VERSION ""

NS_ :

BS_:

BU_:

BO_ 1484 PDU_2125: 8 Vector__XXX
 SG_ LnchCtlWhlSlSts : 1|5@0+ (1,0) [0|21] "" Vector__XXX
 SG_ LnchCtlEngRE46ts : 7|6@0+ (1,0) [0|38] "" TCM
 SG_ LnchCtlBrkPresVal : 8|4@0+ (10,0) [0|150] "%" Vector__XXX
 SG_ DrvModeVisScreenSts : 12|4@0+ (1,0) [0|12] "" Vector__XXX
 SG_ EngSndPerfModeReq : 16|3@0+ (1,0) [0|7] "" Vector__XXX
 SG_ LnchCtlLineLckTmrVal : 20|4@0+ (1,0) [0|15] "sec" TCM
 SG_ PerfTracMgmtMode : 26|3@0+ (1,0) [0|6] "" PCM,TCM
 SG_ HillDscntCtlSysSts : 29|3@0+ (1,0) [0|4] "" Vector__XXX
 SG_ SprtModeDrvlineVisDispVal : 33|3@0+ (1,0) [0|7] "" Vector__XXX
 SG_ SprtModeBrkPedVisDispVal : 36|3@0+ (1,0) [0|7] "" Vector__XXX
 SG_ SprtModeActvAeroVisDispVal : 39|3@0+ (1,0) [0|7] "" Vector__XXX
 SG_ SprtModeRideHghtVisDispVal : 40|3@0+ (1,0) [0|7] "" Vector__XXX
 SG_ SprtModePwrtrnVisDispVal : 43|3@0+ (1,0) [0|7] "" Vector__XXX
 SG_ SprtModeESCVisDispVal : 46|3@0+ (1,0) [0|7] "" Vector__XXX
 SG_ SprtModeSpnsnVisDispVal : 50|3@0+ (1,0) [0|7] "" Vector__XXX
 SG_ SprtModeSndVisDispVal : 53|3@0+ (1,0) [0|7] "" Vector__XXX
 SG_ ShfToPrkBfrExtIndOn : 56|1@0+ (1,0) [0|1] "" Vector__XXX
 SG_ HillDscntCtlVirtSwAvl : 57|1@0+ (1,0) [0|1] "" Vector__XXX
 SG_ WthrSnwModeStrgVisDispVal : 60|3@0+ (1,0) [0|7] "" Vector__XXX
 SG_ SprtModeStrgVisDispVal : 63|3@0+ (1,0) [0|7] "" Vector__XXX

BO_ 1485 PDU_2126: 8 Vector__XXX
 SG_ TkModeBrkPedVisDispVal : 1|3@0+ (1,0) [0|7] "" CGM
 SG_ TkModeActvAeroVisDispVal : 4|3@0+ (1,0) [0|7] "" CGM
 SG_ TireTrdTempSts : 7|3@0+ (1,0) [0|5] "" CGM,PCM,TCM
 SG_ TkModePwrtrnVisDispVal : 8|3@0+ (1,0) [0|7] "" CGM
 SG_ TkModeESCVisDispVal : 11|3@0+ (1,0) [0|7] "" CGM
 SG_ TkModeDrvlineVisDispVal : 14|3@0+ (1,0) [0|7] "" CGM
 SG_ TkModeSndVisDispVal : 18|3@0+ (1,0) [0|7] "" CGM
 SG_ TkModeRideHghtVisDispVal : 21|3@0+ (1,0) [0|7] "" CGM
 SG_ TourModeActvAeroVisDispVal : 25|3@0+ (1,0) [0|7] "" CGM
 SG_ TkModeStrgVisDispVal : 28|3@0+ (1,0) [0|7] "" CGM
 SG_ TkModeSpnsnVisDispVal : 31|3@0+ (1,0) [0|7] "" CGM
 SG_ TourModeESCVisDispVal : 32|3@0+ (1,0) [0|7] "" CGM
 SG_ TourModeDrvlineVisDispVal : 35|3@0+ (1,0) [0|7] "" CGM
 SG_ TourModeBrkPedVisDispVal : 38|3@0+ (1,0) [0|7] "" CGM
 SG_ TourModeRideHghtVisDispVal : 42|3@0+ (1,0) [0|7] "" CGM
 SG_ TourModePwrtrnVisDispVal : 45|3@0+ (1,0) [0|7] "" CGM
 SG_ TourModeStrgVisDispVal : 49|3@0+ (1,0) [0|7] "" CGM
 SG_ TourModeSpnsnVisDispVal : 52|3@0+ (1,0) [0|7] "" CGM
 SG_ TourModeSndVisDispVal : 55|3@0+ (1,0) [0|7] "" CGM
 SG_ TrlrStbAsstActIO : 56|1@0+ (1,0) [0|1] "" CGM
 SG_ TrcCntrlOnIO : 57|1@0+ (1,0) [0|1] "" CGM
 SG_ TrcCntrlOffIO : 58|1@0+ (1,0) [0|1] "" CGM
 SG_ TnDrvTrCtrlOffUnvIndOn : 59|1@0+ (1,0) [0|1] "" CGM
 SG_ SrBkLwBkFlDrVisMsgRqOn : 60|1@0+ (1,0) [0|1] "" CGM
 SG_ TrcStbScrConfig : 62|2@0+ (1,0) [0|3] "" CGM

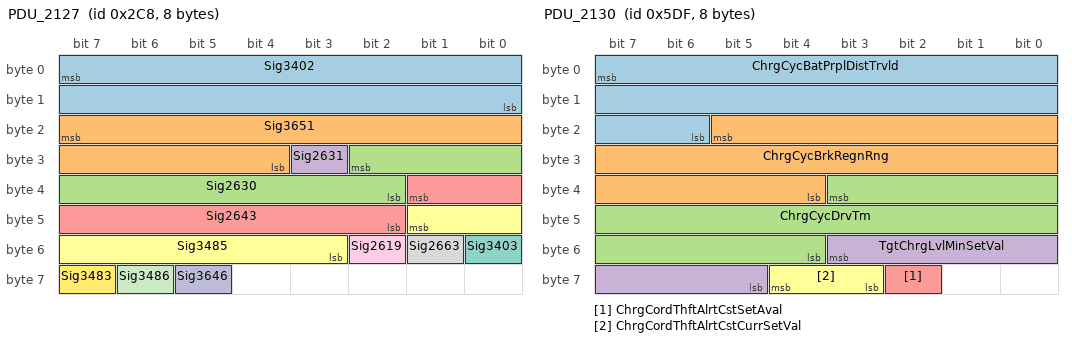
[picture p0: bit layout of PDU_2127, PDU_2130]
BO_ 712 PDU_2127: 8 Vector__XXX
 SG_ Sig3402 : 7|16@0+ (3.05176e-05,0) [0|1.99997] "liters" CGM
 SG_ Sig3651 : 23|12@0+ (0.025,0) [0|102.375] "ltrs/hr" CGM
 SG_ Sig2630 : 26|9@0+ (1,-110) [-110|401] "kPa" CGM
 SG_ Sig2631 : 27|1@0+ (1,0) [0|1] "" CGM
 SG_ Sig2643 : 33|8@0+ (0.392157,0) [0|100] "%" CGM
 SG_ Sig3485 : 41|7@0+ (1,0) [0|127] "%" CGM
 SG_ Sig3403 : 48|1@0+ (1,0) [0|1] "" CGM
 SG_ Sig2663 : 49|1@0+ (1,0) [0|1] "" CGM
 SG_ Sig2619 : 50|1@0+ (1,0) [0|1] "" CGM
 SG_ Sig3646 : 61|1@0+ (1,0) [0|1] "" CGM
 SG_ Sig3486 : 62|1@0+ (1,0) [0|1] "" CGM
 SG_ Sig3483 : 63|1@0+ (1,0) [0|1] "" CGM

BO_ 731 PDU_2128: 4 Vector__XXX
 SG_ ACRfHiSdFldPrs : 6|8@0+ (14,0) [0|3570] "kPaG" BSM,CGM
 SG_ ACRfHiSdFldPrs_Inv : 7|1@0+ (1,0) [0|1] "" BSM,CGM

BO_ 1503 PDU_2130: 8 Vector__XXX
 SG_ ChrgCycBatPrplDistTrvld : 7|18@0+ (0.1,0) [0|26214.3] "km" Vector__XXX
 SG_ ChrgCycBrkRegnRng : 21|18@0+ (0.1,0) [0|26214.3] "km" Vector__XXX
 SG_ ChrgCycDrvTm : 35|16@0+ (1,0) [0|65535] "min" Vector__XXX
 SG_ TgtChrgLvlMinSetVal : 51|7@0+ (1,0) [0|127] "%" Vector__XXX
 SG_ ChrgCordThftAlrtCstSetAval : 58|1@0+ (1,0) [0|1] "" Vector__XXX
 SG_ ChrgCordThftAlrtCstCurrSetVal : 60|2@0+ (1,0) [0|2] "" Vector__XXX

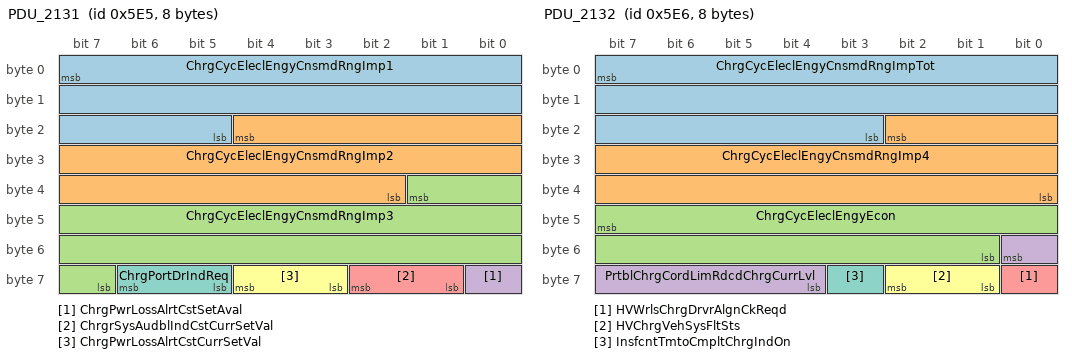
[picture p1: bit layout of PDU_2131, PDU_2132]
BO_ 1509 PDU_2131: 8 Vector__XXX
 SG_ ChrgCycEleclEngyCnsmdRngImp1 : 7|19@0- (0.1,0) [-26214.4|26214.3] "km" Vector__XXX
 SG_ ChrgCycEleclEngyCnsmdRngImp2 : 20|19@0- (0.1,0) [-26214.4|26214.3] "km" Vector__XXX
 SG_ ChrgCycEleclEngyCnsmdRngImp3 : 33|19@0- (0.1,0) [-26214.4|26214.3] "km" Vector__XXX
 SG_ ChrgPwrLossAlrtCstSetAval : 56|1@0+ (1,0) [0|1] "" Vector__XXX
 SG_ ChrgrSysAudblIndCstCurrSetVal : 58|2@0+ (1,0) [0|2] "" Vector__XXX
 SG_ ChrgPwrLossAlrtCstCurrSetVal : 60|2@0+ (1,0) [0|2] "" Vector__XXX
 SG_ ChrgPortDrIndReq : 62|2@0+ (1,0) [0|3] "" Vector__XXX

BO_ 1510 PDU_2132: 8 Vector__XXX
 SG_ ChrgCycEleclEngyCnsmdRngImpTot : 7|21@0- (0.1,0) [-104858|104858] "km" Vector__XXX
 SG_ ChrgCycEleclEngyCnsmdRngImp4 : 18|19@0- (0.1,0) [-26214.4|26214.3] "km" Vector__XXX
 SG_ ChrgCycEleclEngyEcon : 47|15@0- (0.1,0) [-1638.4|1638.3] "" Vector__XXX
 SG_ PrtblChrgCordLimRdcdChrgCurrLvl : 48|5@0+ (1,0) [0|31] "A" Vector__XXX
 SG_ HVWrlsChrgDrvrAlgnCkReqd : 56|1@0+ (1,0) [0|1] "" Vector__XXX
 SG_ HVChrgVehSysFltSts : 58|2@0+ (1,0) [0|2] "" Vector__XXX
 SG_ InsfcntTmtoCmpltChrgIndOn : 59|1@0+ (1,0) [0|1] "" Vector__XXX

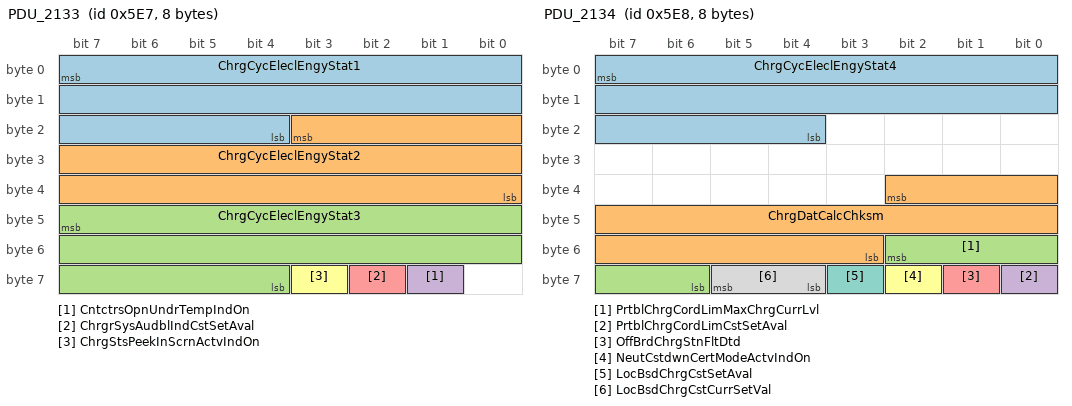
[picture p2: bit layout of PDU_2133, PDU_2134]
BO_ 1511 PDU_2133: 8 Vector__XXX
 SG_ ChrgCycEleclEngyStat1 : 7|20@0+ (0.01,0) [0|10485.8] "kWh" Vector__XXX
 SG_ ChrgCycEleclEngyStat2 : 19|20@0+ (0.01,0) [0|10485.8] "kWh" Vector__XXX
 SG_ ChrgCycEleclEngyStat3 : 47|20@0+ (0.01,0) [0|10485.8] "kWh" Vector__XXX
 SG_ CntctrsOpnUndrTempIndOn : 57|1@0+ (1,0) [0|1] "" Vector__XXX
 SG_ ChrgrSysAudblIndCstSetAval : 58|1@0+ (1,0) [0|1] "" Vector__XXX
 SG_ ChrgStsPeekInScrnActvIndOn : 59|1@0+ (1,0) [0|1] "" Vector__XXX

BO_ 1512 PDU_2134: 8 Vector__XXX
 SG_ ChrgCycEleclEngyStat4 : 7|20@0+ (0.01,0) [0|10485.8] "kWh" Vector__XXX
 SG_ ChrgDatCalcChksm : 34|16@0+ (1,0) [0|65535] "" Vector__XXX
 SG_ PrtblChrgCordLimMaxChrgCurrLvl : 50|5@0+ (1,0) [0|31] "A" Vector__XXX
 SG_ PrtblChrgCordLimCstSetAval : 56|1@0+ (1,0) [0|1] "" Vector__XXX
 SG_ OffBrdChrgStnFltDtd : 57|1@0+ (1,0) [0|1] "" Vector__XXX
 SG_ NeutCstdwnCertModeActvIndOn : 58|1@0+ (1,0) [0|1] "" Vector__XXX
 SG_ LocBsdChrgCstSetAval : 59|1@0+ (1,0) [0|1] "" Vector__XXX
 SG_ LocBsdChrgCstCurrSetVal : 61|2@0+ (1,0) [0|2] "" Vector__XXX

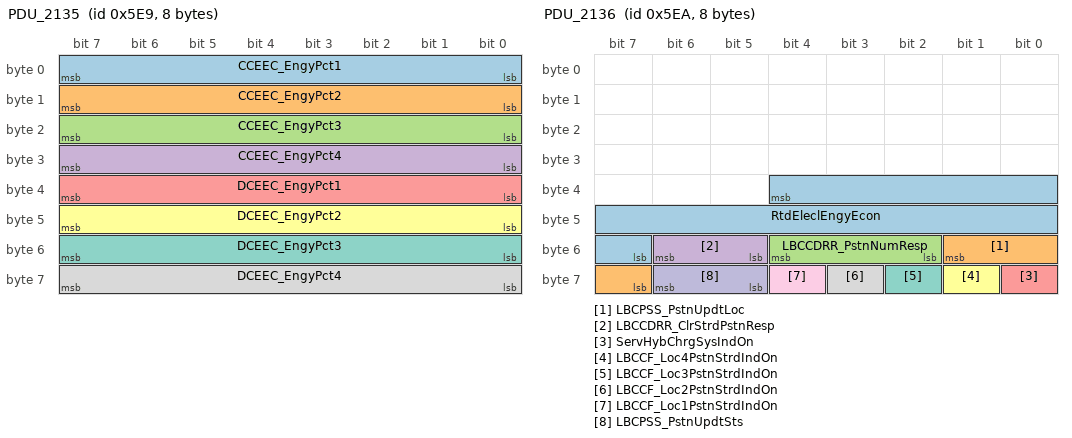
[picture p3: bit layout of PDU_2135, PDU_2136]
BO_ 1513 PDU_2135: 8 Vector__XXX
 SG_ CCEEC_EngyPct1 : 7|8@0+ (0.392157,0) [0|100] "%" Vector__XXX
 SG_ CCEEC_EngyPct2 : 15|8@0+ (0.392157,0) [0|100] "%" Vector__XXX
 SG_ CCEEC_EngyPct3 : 23|8@0+ (0.392157,0) [0|100] "%" Vector__XXX
 SG_ CCEEC_EngyPct4 : 31|8@0+ (0.392157,0) [0|100] "%" Vector__XXX
 SG_ DCEEC_EngyPct1 : 39|8@0+ (0.392157,0) [0|100] "%" Vector__XXX
 SG_ DCEEC_EngyPct2 : 47|8@0+ (0.392157,0) [0|100] "%" Vector__XXX
 SG_ DCEEC_EngyPct3 : 55|8@0+ (0.392157,0) [0|100] "%" Vector__XXX
 SG_ DCEEC_EngyPct4 : 63|8@0+ (0.392157,0) [0|100] "%" Vector__XXX

BO_ 1514 PDU_2136: 8 Vector__XXX
 SG_ RtdEleclEngyEcon : 36|14@0+ (0.1,0) [0|1638.3] "" Vector__XXX
 SG_ LBCPSS_PstnUpdtLoc : 49|3@0+ (1,0) [0|4] "" Vector__XXX
 SG_ LBCCDRR_PstnNumResp : 52|3@0+ (1,0) [0|4] "" Vector__XXX
 SG_ LBCCDRR_ClrStrdPstnResp : 54|2@0+ (1,0) [0|2] "" Vector__XXX
 SG_ ServHybChrgSysIndOn : 56|1@0+ (1,0) [0|1] "" VDM
 SG_ LBCCF_Loc4PstnStrdIndOn : 57|1@0+ (1,0) [0|1] "" Vector__XXX
 SG_ LBCCF_Loc3PstnStrdIndOn : 58|1@0+ (1,0) [0|1] "" Vector__XXX
 SG_ LBCCF_Loc2PstnStrdIndOn : 59|1@0+ (1,0) [0|1] "" Vector__XXX
 SG_ LBCCF_Loc1PstnStrdIndOn : 60|1@0+ (1,0) [0|1] "" Vector__XXX
 SG_ LBCPSS_PstnUpdtSts : 62|2@0+ (1,0) [0|2] "" Vector__XXX

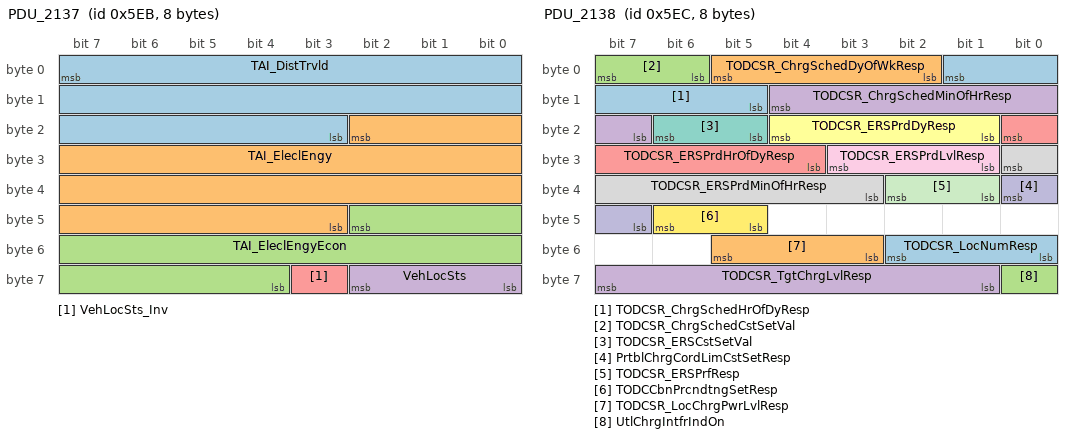
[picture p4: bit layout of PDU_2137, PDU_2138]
BO_ 1515 PDU_2137: 8 Vector__XXX
 SG_ TAI_DistTrvld : 7|21@0+ (0.1,0) [0|209715] "km" Vector__XXX
 SG_ TAI_EleclEngy : 18|24@0+ (0.1,0) [0|1.67772e+006] "kWh" Vector__XXX
 SG_ TAI_EleclEngyEcon : 42|15@0- (0.1,0) [-1638.4|1638.3] "" Vector__XXX
 SG_ VehLocSts : 58|3@0+ (1,0) [0|4] "" Vector__XXX
 SG_ VehLocSts_Inv : 59|1@0+ (1,0) [0|1] "" Vector__XXX

BO_ 1516 PDU_2138: 8 Vector__XXX
 SG_ TODCSR_ChrgSchedHrOfDyResp : 1|5@0+ (1,0) [0|31] "h" Vector__XXX
 SG_ TODCSR_ChrgSchedDyOfWkResp : 5|4@0+ (1,0) [0|10] "" Vector__XXX
 SG_ TODCSR_ChrgSchedCstSetVal : 7|2@0+ (1,0) [0|2] "" Vector__XXX
 SG_ TODCSR_ChrgSchedMinOfHrResp : 12|6@0+ (1,0) [0|63] "min" Vector__XXX
 SG_ TODCSR_ERSPrdHrOfDyResp : 16|5@0+ (1,0) [0|31] "h" Vector__XXX
 SG_ TODCSR_ERSPrdDyResp : 20|4@0+ (1,0) [0|10] "" Vector__XXX
 SG_ TODCSR_ERSCstSetVal : 22|2@0+ (1,0) [0|2] "" Vector__XXX
 SG_ TODCSR_ERSPrdMinOfHrResp : 24|6@0+ (1,0) [0|63] "min" Vector__XXX
 SG_ TODCSR_ERSPrdLvlResp : 27|3@0+ (1,0) [0|5] "" Vector__XXX
 SG_ PrtblChrgCordLimCstSetResp : 32|2@0+ (1,0) [0|2] "" Vector__XXX
 SG_ TODCSR_ERSPrfResp : 34|2@0+ (1,0) [0|3] "" Vector__XXX
 SG_ TODCCbnPrcndtngSetResp : 46|2@0+ (1,0) [0|2] "" Vector__XXX
 SG_ TODCSR_LocNumResp : 50|3@0+ (1,0) [0|5] "" Vector__XXX
 SG_ TODCSR_LocChrgPwrLvlResp : 53|3@0+ (1,0) [0|4] "" Vector__XXX
 SG_ UtlChrgIntfrIndOn : 56|1@0+ (1,0) [0|1] "" Vector__XXX
 SG_ TODCSR_TgtChrgLvlResp : 63|7@0+ (1,0) [0|127] "%" Vector__XXX

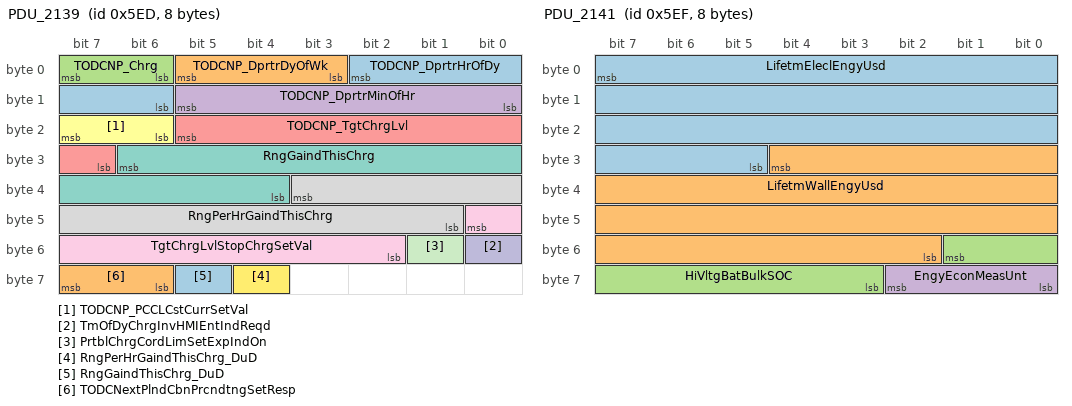
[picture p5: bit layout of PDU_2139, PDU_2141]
BO_ 1517 PDU_2139: 8 Vector__XXX
 SG_ TODCNP_DprtrHrOfDy : 2|5@0+ (1,0) [0|31] "h" Vector__XXX
 SG_ TODCNP_DprtrDyOfWk : 5|3@0+ (1,0) [0|7] "" Vector__XXX
 SG_ TODCNP_Chrg : 7|2@0+ (1,0) [0|3] "" Vector__XXX
 SG_ TODCNP_DprtrMinOfHr : 13|6@0+ (1,0) [0|63] "min" Vector__XXX
 SG_ TODCNP_TgtChrgLvl : 21|7@0+ (1,0) [0|127] "%" Vector__XXX
 SG_ TODCNP_PCCLCstCurrSetVal : 23|2@0+ (1,0) [0|2] "" Vector__XXX
 SG_ RngGaindThisChrg : 30|11@0+ (1,0) [0|2047] "km" Vector__XXX
 SG_ RngPerHrGaindThisChrg : 35|11@0+ (1,0) [0|2047] "km/h" Vector__XXX
 SG_ TgtChrgLvlStopChrgSetVal : 40|7@0+ (1,0) [0|127] "%" Vector__XXX
 SG_ TmOfDyChrgInvHMIEntIndReqd : 48|1@0+ (1,0) [0|1] "" Vector__XXX
 SG_ PrtblChrgCordLimSetExpIndOn : 49|1@0+ (1,0) [0|1] "" Vector__XXX
 SG_ RngPerHrGaindThisChrg_DuD : 60|1@0+ (1,0) [0|1] "" Vector__XXX
 SG_ RngGaindThisChrg_DuD : 61|1@0+ (1,0) [0|1] "" Vector__XXX
 SG_ TODCNextPlndCbnPrcndtngSetResp : 63|2@0+ (1,0) [0|2] "" Vector__XXX

BO_ 1518 PDU_2140: 8 Vector__XXX
 SG_ LifetmBatPrplDistTrvld : 7|24@0+ (0.1,0) [0|1.67772e+006] "km" Vector__XXX
 SG_ DrvCycBrkRegnRng : 32|14@0+ (0.1,0) [0|1638.3] "km" Vector__XXX
 SG_ DrvCycDrvTm : 50|11@0+ (1,0) [0|2047] "min" Vector__XXX

BO_ 1519 PDU_2141: 8 Vector__XXX
 SG_ LifetmEleclEngyUsd : 7|27@0+ (0.1,0) [0|1.34218e+007] "kWh" Vector__XXX
 SG_ LifetmWallEngyUsd : 28|27@0+ (0.1,0) [0|1.34218e+007] "kWh" Vector__XXX
 SG_ HiVltgBatBulkSOC : 49|7@0+ (1,0) [0|127] "%" Vector__XXX
 SG_ EngyEconMeasUnt : 58|3@0+ (1,0) [0|5] "" Vector__XXX

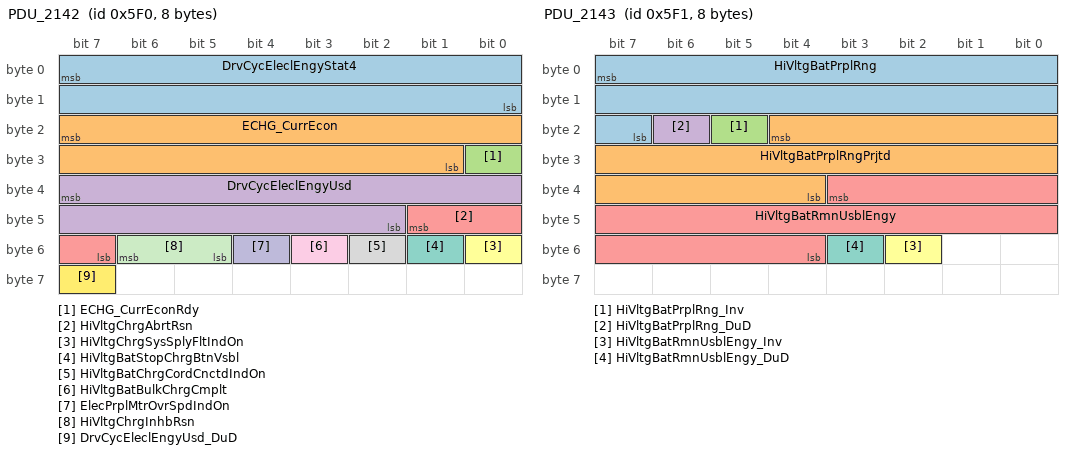
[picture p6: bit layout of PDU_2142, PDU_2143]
BO_ 1520 PDU_2142: 8 Vector__XXX
 SG_ DrvCycEleclEngyStat4 : 7|16@0+ (0.01,0) [0|655.35] "kWh" Vector__XXX
 SG_ ECHG_CurrEcon : 23|15@0- (0.1,0) [-1638.4|1638.3] "" Vector__XXX
 SG_ ECHG_CurrEconRdy : 24|1@0+ (1,0) [0|1] "" Vector__XXX
 SG_ DrvCycEleclEngyUsd : 39|14@0+ (0.1,0) [0|1638.3] "kWh" Vector__XXX
 SG_ HiVltgChrgAbrtRsn : 41|3@0+ (1,0) [0|6] "" Vector__XXX
 SG_ HiVltgChrgSysSplyFltIndOn : 48|1@0+ (1,0) [0|1] "" Vector__XXX
 SG_ HiVltgBatStopChrgBtnVsbl : 49|1@0+ (1,0) [0|1] "" Vector__XXX
 SG_ HiVltgBatChrgCordCnctdIndOn : 50|1@0+ (1,0) [0|1] "" VDM
 SG_ HiVltgBatBulkChrgCmplt : 51|1@0+ (1,0) [0|1] "" Vector__XXX
 SG_ ElecPrplMtrOvrSpdIndOn : 52|1@0+ (1,0) [0|1] "" Vector__XXX
 SG_ HiVltgChrgInhbRsn : 54|2@0+ (1,0) [0|3] "" Vector__XXX
 SG_ DrvCycEleclEngyUsd_DuD : 63|1@0+ (1,0) [0|1] "" Vector__XXX

BO_ 1521 PDU_2143: 8 Vector__XXX
 SG_ HiVltgBatPrplRng : 7|17@0+ (0.015625,0) [0|2047.98] "km" ADIMa,ADIMb,VDM
 SG_ HiVltgBatPrplRngPrjtd : 20|17@0+ (0.015625,0) [0|2047.98] "km" Vector__XXX
 SG_ HiVltgBatPrplRng_Inv : 21|1@0+ (1,0) [0|1] "" ADIMa,ADIMb,VDM
 SG_ HiVltgBatPrplRng_DuD : 22|1@0+ (1,0) [0|1] "" ADIMa,ADIMb,VDM
 SG_ HiVltgBatRmnUsblEngy : 35|16@0+ (0.01,0) [0|655.35] "kWh" VDM
 SG_ HiVltgBatRmnUsblEngy_Inv : 50|1@0+ (1,0) [0|1] "" VDM
 SG_ HiVltgBatRmnUsblEngy_DuD : 51|1@0+ (1,0) [0|1] "" VDM

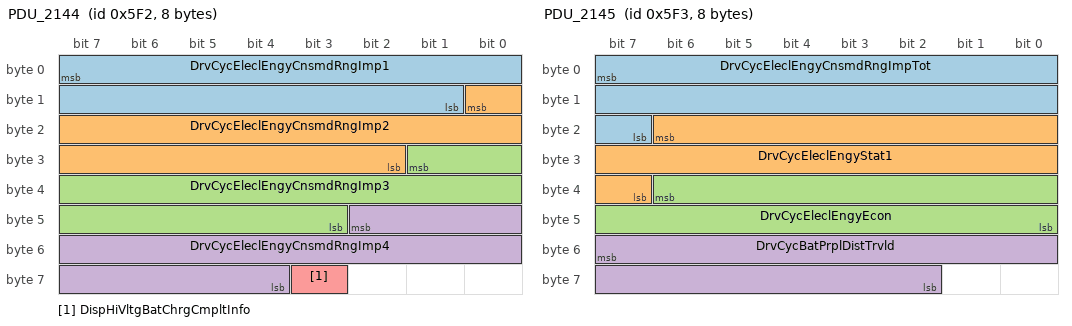
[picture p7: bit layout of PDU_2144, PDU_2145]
BO_ 1522 PDU_2144: 8 Vector__XXX
 SG_ DrvCycEleclEngyCnsmdRngImp1 : 7|15@0- (0.1,0) [-1638.4|1638.3] "km" Vector__XXX
 SG_ DrvCycEleclEngyCnsmdRngImp2 : 8|15@0- (0.1,0) [-1638.4|1638.3] "km" Vector__XXX
 SG_ DrvCycEleclEngyCnsmdRngImp3 : 25|15@0- (0.1,0) [-1638.4|1638.3] "km" Vector__XXX
 SG_ DrvCycEleclEngyCnsmdRngImp4 : 42|15@0- (0.1,0) [-1638.4|1638.3] "km" Vector__XXX
 SG_ DispHiVltgBatChrgCmpltInfo : 59|1@0+ (1,0) [0|1] "" Vector__XXX

BO_ 1523 PDU_2145: 8 Vector__XXX
 SG_ DrvCycEleclEngyCnsmdRngImpTot : 7|17@0- (0.1,0) [-6553.6|6553.5] "km" Vector__XXX
 SG_ DrvCycEleclEngyStat1 : 22|16@0+ (0.01,0) [0|655.35] "kWh" Vector__XXX
 SG_ DrvCycEleclEngyEcon : 38|15@0- (0.1,0) [-1638.4|1638.3] "" Vector__XXX
 SG_ DrvCycBatPrplDistTrvld : 55|14@0+ (0.1,0) [0|1638.3] "km" Vector__XXX

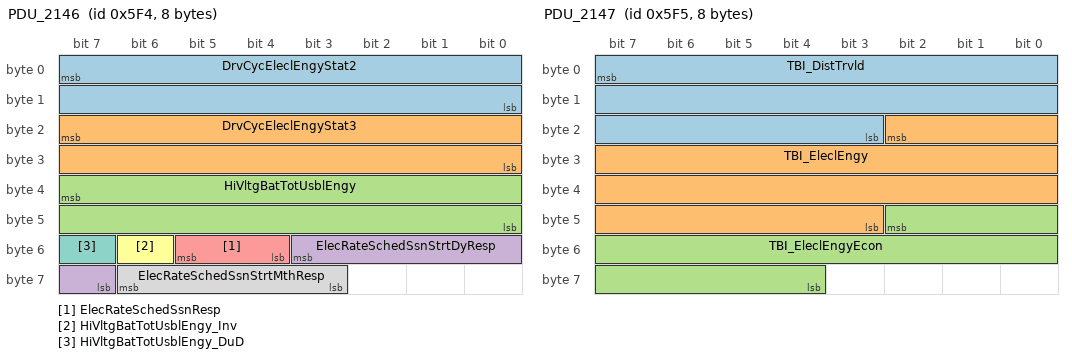
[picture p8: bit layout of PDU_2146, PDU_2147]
BO_ 1524 PDU_2146: 8 Vector__XXX
 SG_ DrvCycEleclEngyStat2 : 7|16@0+ (0.01,0) [0|655.35] "kWh" Vector__XXX
 SG_ DrvCycEleclEngyStat3 : 23|16@0+ (0.01,0) [0|655.35] "kWh" Vector__XXX
 SG_ HiVltgBatTotUsblEngy : 39|16@0+ (0.01,0) [0|655.35] "kWh" VDM
 SG_ ElecRateSchedSsnStrtDyResp : 51|5@0+ (1,0) [0|31] "day" Vector__XXX
 SG_ ElecRateSchedSsnResp : 53|2@0+ (1,0) [0|3] "" Vector__XXX
 SG_ HiVltgBatTotUsblEngy_Inv : 54|1@0+ (1,0) [0|1] "" VDM
 SG_ HiVltgBatTotUsblEngy_DuD : 55|1@0+ (1,0) [0|1] "" VDM
 SG_ ElecRateSchedSsnStrtMthResp : 62|4@0+ (1,0) [0|12] "" Vector__XXX

BO_ 1525 PDU_2147: 8 Vector__XXX
 SG_ TBI_DistTrvld : 7|21@0+ (0.1,0) [0|209715] "km" Vector__XXX
 SG_ TBI_EleclEngy : 18|24@0+ (0.1,0) [0|1.67772e+006] "kWh" Vector__XXX
 SG_ TBI_EleclEngyEcon : 42|15@0- (0.1,0) [-1638.4|1638.3] "" Vector__XXX

BO_ 736 PDU_2150: 8 Vector__XXX
 SG_ LIB1PackExtrnVltg : 7|11@0+ (0.01,3) [3|23.47] "Volts" FOPM
 SG_ LIB1AvgTemp : 10|8@0+ (1,-40) [-40|215] "C" ECM,FOPM,PCM
 SG_ LIB1PackExtrnVltg_Inv : 11|1@0+ (1,0) [0|1] "" FOPM
 SG_ LIB1PackExtrnVltg_DuD : 12|1@0+ (1,0) [0|1] "" Vector__XXX
 SG_ LIB1MaxTemp : 16|8@0+ (1,-40) [-40|215] "C" ADIMa,ADIMb,ECM,FOPM,PCM
 SG_ LIB1AvgTemp_Inv : 17|1@0+ (1,0) [0|1] "" ECM,FOPM,PCM
 SG_ LIB1AvgTemp_DuD : 18|1@0+ (1,0) [0|1] "" ECM,PCM
 SG_ LIB1MaxTemp_DuD : 24|1@0+ (1,0) [0|1] "" ECM,PCM
 SG_ LIB1MinTemp : 38|8@0+ (1,-40) [-40|215] "C" ADIMa,ADIMb,ECM,FOPM,PCM
 SG_ LIB1MaxTemp_Inv : 39|1@0+ (1,0) [0|1] "" ADIMa,ADIMb,ECM,FOPM,PCM
 SG_ LIB1StatOfChrg : 44|8@0+ (0.39,0) [0|99.45] "%" ECM,FOPM,PCM
 SG_ LIB1MinTemp_Inv : 45|1@0+ (1,0) [0|1] "" ADIMa,ADIMb,ECM,FOPM,PCM
 SG_ LIB1MinTemp_DuD : 46|1@0+ (1,0) [0|1] "" ECM,PCM
 SG_ LIB1CellBalFlt_DuD : 48|1@0+ (1,0) [0|1] "" Vector__XXX
 SG_ LIB1CellBalFlt : 50|2@0+ (1,0) [0|3] "" FOPM
 SG_ LIB1StatOfChrg_Inv : 51|1@0+ (1,0) [0|1] "" ECM,FOPM,PCM
 SG_ LIB1StatOfChrg_DuD : 52|1@0+ (1,0) [0|1] "" ECM,PCM
 SG_ LIB1CellVltgFlt_Inv : 59|1@0+ (1,0) [0|1] "" FOPM
 SG_ LIB1CellVltgFlt_DuD : 60|1@0+ (1,0) [0|1] "" Vector__XXX
 SG_ LIB1CellVltgFlt : 62|2@0+ (1,0) [0|3] "" FOPM
 SG_ LIB1CellBalFlt_Inv : 63|1@0+ (1,0) [0|1] "" FOPM

BO_ 949 PDU_2153: 8 Vector__XXX
 SG_ ACCTOSHiThrtLicVehTmToClsn1 : 7|16@0+ (0.001,0) [0|65.535] "s" Vector__XXX
 SG_ ACCTOSHiThrtLicVehTmToClsn10 : 23|16@0+ (0.001,0) [0|65.535] "s" Vector__XXX
 SG_ ACCTOSHiThrtLicVehTmToClsn2 : 39|16@0+ (0.001,0) [0|65.535] "s" Vector__XXX
 SG_ ACCTOSHiThrtLicVehTmToClsn3 : 55|16@0+ (0.001,0) [0|65.535] "s" Vector__XXX

BO_ 950 PDU_2154: 8 Vector__XXX
 SG_ ACCTOSHiThrtLicVehTmToClsn4 : 7|16@0+ (0.001,0) [0|65.535] "s" Vector__XXX
 SG_ ACCTOSHiThrtLicVehTmToClsn5 : 23|16@0+ (0.001,0) [0|65.535] "s" Vector__XXX
 SG_ ACCTOSHiThrtLicVehTmToClsn6 : 39|16@0+ (0.001,0) [0|65.535] "s" Vector__XXX
 SG_ ACCTOSHiThrtLicVehTmToClsn7 : 55|16@0+ (0.001,0) [0|65.535] "s" Vector__XXX

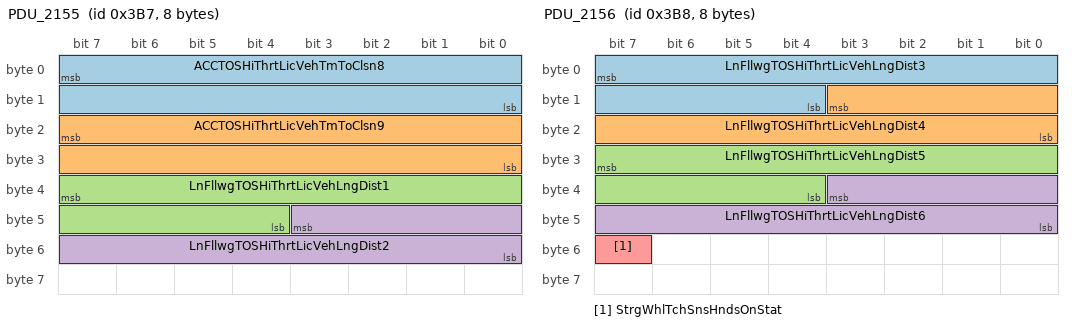
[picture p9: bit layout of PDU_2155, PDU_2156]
BO_ 951 PDU_2155: 8 Vector__XXX
 SG_ ACCTOSHiThrtLicVehTmToClsn8 : 7|16@0+ (0.001,0) [0|65.535] "s" Vector__XXX
 SG_ ACCTOSHiThrtLicVehTmToClsn9 : 23|16@0+ (0.001,0) [0|65.535] "s" Vector__XXX
 SG_ LnFllwgTOSHiThrtLicVehLngDist1 : 39|12@0- (0.125,0) [-256|255.875] "m" Vector__XXX
 SG_ LnFllwgTOSHiThrtLicVehLngDist2 : 43|12@0- (0.125,0) [-256|255.875] "m" Vector__XXX

BO_ 952 PDU_2156: 8 Vector__XXX
 SG_ LnFllwgTOSHiThrtLicVehLngDist3 : 7|12@0- (0.125,0) [-256|255.875] "m" Vector__XXX
 SG_ LnFllwgTOSHiThrtLicVehLngDist4 : 11|12@0- (0.125,0) [-256|255.875] "m" Vector__XXX
 SG_ LnFllwgTOSHiThrtLicVehLngDist5 : 31|12@0- (0.125,0) [-256|255.875] "m" Vector__XXX
 SG_ LnFllwgTOSHiThrtLicVehLngDist6 : 35|12@0- (0.125,0) [-256|255.875] "m" Vector__XXX
 SG_ StrgWhlTchSnsHndsOnStat : 55|1@0+ (1,0) [0|1] "" Vector__XXX

BO_ 1417 PDU_2157: 8 Vector__XXX
 SG_ ACCDrSlctdSpd : 5|12@0+ (0.0625,0) [0|255.938] "km/h" CGM
 SG_ ACCAutoStSpStat : 7|2@0+ (1,0) [0|3] "" CGM
 SG_ ACCSpdLimSgnUnt : 8|1@0+ (1,0) [0|1] "" CGM
 SG_ ACCDrSlctdSpdIndOn : 9|1@0+ (1,0) [0|1] "" CGM
 SG_ ACCSpdLimSgnVal : 23|8@0+ (1,0) [0|255] "" CGM
 SG_ FrwdImpMtgnOpSlctCstCrStVal : 26|3@0+ (1,0) [0|7] "" CGM
 SG_ FrntPCMRspTypCstCrStVal : 29|3@0+ (1,0) [0|7] "" CGM
 SG_ ACCSysSlctdMd : 31|2@0+ (1,0) [0|2] "" CGM
 SG_ FrntPCMRspTypCstAvlFlg1 : 32|1@0+ (1,0) [0|1] "" CGM
 SG_ AutoEmrgBrkgDsbldIndOn : 33|1@0+ (1,0) [0|1] "" CGM
 SG_ ACCGoNtfrChmEvntSt : 34|1@0+ (1,0) [0|1] "" CGM
 SG_ AnmlWrnIndReq : 36|2@0+ (1,0) [0|2] "" CGM
 SG_ FrwdVehAhdIndReq : 39|3@0+ (1,0) [0|5] "" CGM
 SG_ FrtPedtrnClsnMtgnAudAttnReqd : 40|1@0+ (1,0) [0|1] "" CGM
 SG_ FrntPCMRspTypCstStAvl : 41|1@0+ (1,0) [0|1] "" CGM
 SG_ FrntPCMRspTypCstAvlFlg7 : 42|1@0+ (1,0) [0|1] "" CGM
 SG_ FrntPCMRspTypCstAvlFlg6 : 43|1@0+ (1,0) [0|1] "" CGM
 SG_ FrntPCMRspTypCstAvlFlg5 : 44|1@0+ (1,0) [0|1] "" CGM
 SG_ FrntPCMRspTypCstAvlFlg4 : 45|1@0+ (1,0) [0|1] "" CGM
 SG_ FrntPCMRspTypCstAvlFlg3 : 46|1@0+ (1,0) [0|1] "" CGM
 SG_ FrntPCMRspTypCstAvlFlg2 : 47|1@0+ (1,0) [0|1] "" CGM
 SG_ FrwdImpMtgnOpSlctCstAvlFlg7 : 48|1@0+ (1,0) [0|1] "" CGM
 SG_ FrwdImpMtgnOpSlctCstAvlFlg6 : 49|1@0+ (1,0) [0|1] "" CGM
 SG_ FrwdImpMtgnOpSlctCstAvlFlg5 : 50|1@0+ (1,0) [0|1] "" CGM
 SG_ FrwdImpMtgnOpSlctCstAvlFlg4 : 51|1@0+ (1,0) [0|1] "" CGM
 SG_ FrwdImpMtgnOpSlctCstAvlFlg3 : 52|1@0+ (1,0) [0|1] "" CGM
 SG_ FrwdImpMtgnOpSlctCstAvlFlg2 : 53|1@0+ (1,0) [0|1] "" CGM
 SG_ FrwdImpMtgnOpSlctCstAvlFlg1 : 54|1@0+ (1,0) [0|1] "" CGM
 SG_ FrwdClsnAlrtImntAlrtAudAttnReqd : 55|1@0+ (1,0) [0|1] "" CGM
 SG_ GoNotfrCstAvlFlg7 : 56|1@0+ (1,0) [0|1] "" CGM
 SG_ GoNotfrCstAvlFlg6 : 57|1@0+ (1,0) [0|1] "" CGM
 SG_ GoNotfrCstAvlFlg5 : 58|1@0+ (1,0) [0|1] "" CGM
 SG_ GoNotfrCstAvlFlg4 : 59|1@0+ (1,0) [0|1] "" CGM
 SG_ GoNotfrCstAvlFlg3 : 60|1@0+ (1,0) [0|1] "" CGM
 SG_ GoNotfrCstAvlFlg2 : 61|1@0+ (1,0) [0|1] "" CGM
 SG_ GoNotfrCstAvlFlg1 : 62|1@0+ (1,0) [0|1] "" CGM
 SG_ FrwdImpMtgnOpSlctCstStAvl : 63|1@0+ (1,0) [0|1] "" CGM

BO_ 1259 PDU_2158: 6 Vector__XXX
 SG_ SprTireSt : 7|2@0+ (1,0) [0|2] "" CGM,EPS,EPSb,PCM,RDCM,TCCM,TCM

BO_ 40 PDU_2159: 16 Vector__XXX
 SG_ RAI1P_RrAxlEstdTrqAuth : 7|11@0+ (5,-5120) [-5120|5115] "Nm" ADIMa,ADIMb,ECP_E,ECP_S
 SG_ PrplSysPriAxlLtTrqCmdAuth : 9|19@0- (0.25,0) [-65536|65535.8] "Nm" EPS,EPSb
 SG_ RAI1P_RrAxlStsAuth : 11|2@0+ (1,0) [0|3] "" ADIMa,ADIMb,ECP_E,ECP_S
 SG_ RAI1P_RrAxlEstdTrqAuth_Inv : 12|1@0+ (1,0) [0|1] "" ADIMa,ADIMb,ECP_E,ECP_S
 SG_ PrplSysPriAxlRtTrqCmdAuth : 38|19@0- (0.25,0) [-65536|65535.8] "Nm" EPS,EPSb
 SG_ PrplSysSecAxlTrqCmdAuth : 51|19@0- (0.25,0) [-65536|65535.8] "Nm" EPS,EPSb

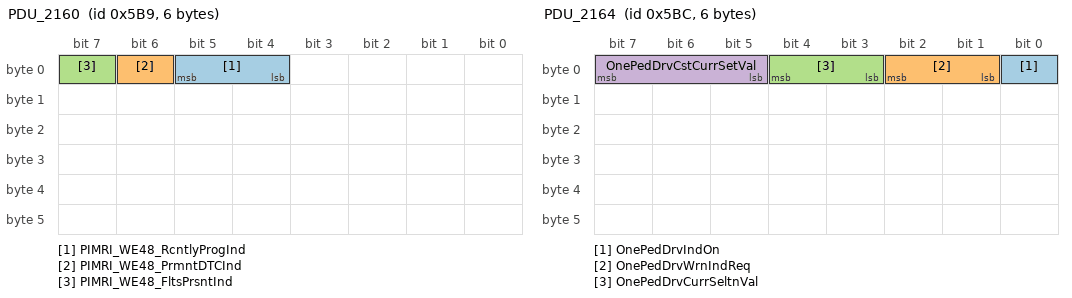
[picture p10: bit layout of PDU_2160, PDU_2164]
BO_ 1465 PDU_2160: 6 Vector__XXX
 SG_ PIMRI_WE48_RcntlyProgInd : 5|2@0+ (1,0) [0|3] "" ECM,PCM,ECP_E
 SG_ PIMRI_WE48_PrmntDTCInd : 6|1@0+ (1,0) [0|1] "" ECM,PCM,ECP_E
 SG_ PIMRI_WE48_FltsPrsntInd : 7|1@0+ (1,0) [0|1] "" ECM,PCM,ECP_E

BO_ 1466 PDU_2161: 8 Vector__XXX
 SG_ TirePrsLRInr : 7|8@0+ (4,0) [0|1020] "kPaG" EBCM
 SG_ TirePrsRRInr : 11|8@0+ (4,0) [0|1020] "kPaG" EBCM
 SG_ TirePrsStatLRInr : 14|3@0+ (1,0) [0|5] "" EBCM
 SG_ TirePrsLRInr_Inv : 15|1@0+ (1,0) [0|1] "" EBCM
 SG_ TirePrsStatRRInr : 18|3@0+ (1,0) [0|5] "" EBCM
 SG_ TirePrsRRInr_Inv : 19|1@0+ (1,0) [0|1] "" EBCM
 SG_ ElecRateSchedSsnStrtMthReq : 24|4@0+ (1,0) [0|12] "" VICM
 SG_ ElecRateSchedSsnStrtDyReq : 29|5@0+ (1,0) [0|31] "day" VICM
 SG_ ElecRateSchedSsnReq : 31|2@0+ (1,0) [0|3] "" VICM
 SG_ CbnPrcndtngSchTempCstSetReq : 36|5@0+ (0.5,16) [16|31.5] "Deg C" VICM
 SG_ VirtOnePedDrvReq : 40|2@0+ (1,0) [0|2] "" ECP_E
 SG_ TlmHVDCFstChrgSoonReq : 42|2@0+ (1,0) [0|2] "" VICM
 SG_ HVDCFstChrgSoonReq : 44|2@0+ (1,0) [0|2] "" VICM
 SG_ OnePedDrvCstChgSetReq : 47|3@0+ (1,0) [0|4] "" ECP_E
 SG_ Sig2580 : 49|2@0+ (1,0) [0|3] "" ADIMa,ADIMb
 SG_ Sig0613 : 51|2@0+ (1,0) [0|3] "" ADIMa,ADIMb
 SG_ E44MutDrvrReq : 53|2@0+ (1,0) [0|2] "" ACP2_MCU,EOCM,EOCM_HC_Superset
 SG_ CbnPrcndtngSchTempCstSetReqAtv : 54|1@0+ (1,0) [0|1] "" VICM
 SG_ DMSIntnDrvrCstChgSetReq : 58|3@0+ (1,0) [0|2] "" ACP2_MCU,EOCM_HC_Superset,FCM
 SG_ DMSDrwDrvrCstChgSetReq : 61|3@0+ (1,0) [0|3] "" ACP2_MCU,EOCM_HC_Superset,FCM
 SG_ Sig3200 : 63|2@0+ (1,0) [0|3] "" ADIMa,ADIMb

BO_ 929 PDU_2162: 6 Vector__XXX
 SG_ VehDynsPerfModeReq : 4|3@0+ (1,0) [0|7] "" ADIMa,ADIMb,ECP_E
 SG_ RrDiffPerfModeReq : 7|3@0+ (1,0) [0|7] "" ADIMa,ADIMb,ECP_E

BO_ 1467 PDU_2163: 6 Vector__XXX
 SG_ OnePedDrvCstSetAval : 0|1@0+ (1,0) [0|1] "" CGM
 SG_ OnePedDrvCstSetAllwdFlg7 : 1|1@0+ (1,0) [0|1] "" CGM
 SG_ OnePedDrvCstSetAllwdFlg6 : 2|1@0+ (1,0) [0|1] "" CGM
 SG_ OnePedDrvCstSetAllwdFlg5 : 3|1@0+ (1,0) [0|1] "" CGM
 SG_ OnePedDrvCstSetAllwdFlg4 : 4|1@0+ (1,0) [0|1] "" CGM
 SG_ OnePedDrvCstSetAllwdFlg3 : 5|1@0+ (1,0) [0|1] "" CGM
 SG_ OnePedDrvCstSetAllwdFlg2 : 6|1@0+ (1,0) [0|1] "" CGM
 SG_ OnePedDrvCstSetAllwdFlg1 : 7|1@0+ (1,0) [0|1] "" CGM
 SG_ VirtOnePedDrvCtlAval : 8|1@0+ (1,0) [0|1] "" CGM
 SG_ OnePedDrvCstSetAvlFlg7 : 9|1@0+ (1,0) [0|1] "" CGM
 SG_ OnePedDrvCstSetAvlFlg6 : 10|1@0+ (1,0) [0|1] "" CGM
 SG_ OnePedDrvCstSetAvlFlg5 : 11|1@0+ (1,0) [0|1] "" CGM
 SG_ OnePedDrvCstSetAvlFlg4 : 12|1@0+ (1,0) [0|1] "" CGM
 SG_ OnePedDrvCstSetAvlFlg3 : 13|1@0+ (1,0) [0|1] "" CGM
 SG_ OnePedDrvCstSetAvlFlg2 : 14|1@0+ (1,0) [0|1] "" CGM
 SG_ OnePedDrvCstSetAvlFlg1 : 15|1@0+ (1,0) [0|1] "" CGM
 SG_ VirtOnePedDrvUserCtlAllwd : 23|1@0+ (1,0) [0|1] "" CGM

BO_ 1468 PDU_2164: 6 Vector__XXX
 SG_ OnePedDrvIndOn : 0|1@0+ (1,0) [0|1] "" CGM
 SG_ OnePedDrvWrnIndReq : 2|2@0+ (1,0) [0|1] "" CGM
 SG_ OnePedDrvCurrSeltnVal : 4|2@0+ (1,0) [0|2] "" CGM
 SG_ OnePedDrvCstCurrSetVal : 7|3@0+ (1,0) [0|4] "" CGM

BO_ 931 PDU_2165: 6 Vector__XXX
 SG_ ElecMchnAInvrtStat : 7|3@0+ (1,0) [0|5] "" VDM

BO_ 115 PDU_2167: 6 Vector__XXX
 SG_ Sig4927 : 6|16@0- (0.125,0) [-4096|4095.88] "Nm" CGM,VDM
 SG_ Sig4928 : 7|1@0+ (1,0) [0|1] "" CGM,VDM

BO_ 194 PDU_2168: 6 Vector__XXX
 SG_ PrplSysInvrtBDCCurrAuth : 7|15@0- (0.1,0) [-1638.4|1638.3] "Amp" VDM
 SG_ PrplSysInvrtBDCCurrAuth_Inv : 8|1@0+ (1,0) [0|1] "" VDM

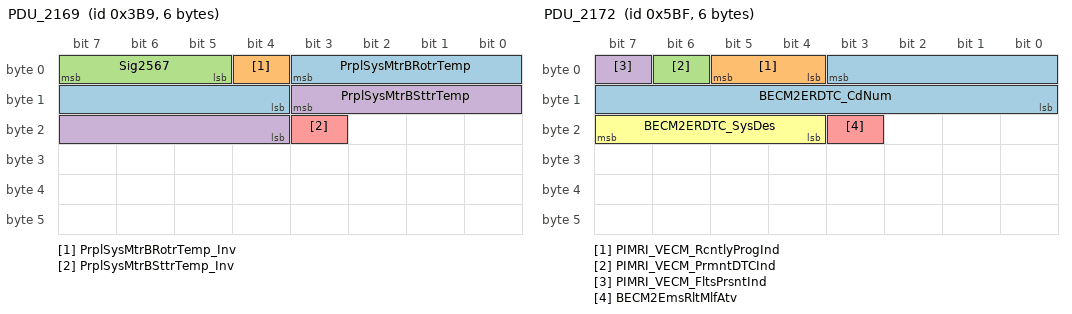
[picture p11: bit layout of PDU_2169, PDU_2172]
BO_ 953 PDU_2169: 6 Vector__XXX
 SG_ PrplSysMtrBRotrTemp : 3|8@0+ (1,-40) [-40|215] "deg C" VDM,ECP_E
 SG_ PrplSysMtrBRotrTemp_Inv : 4|1@0+ (1,0) [0|1] "" VDM,ECP_E
 SG_ Sig2567 : 7|3@0+ (1,0) [0|5] "" VDM
 SG_ PrplSysMtrBSttrTemp : 11|8@0+ (1,-40) [-40|215] "deg C" VDM,ECP_E
 SG_ PrplSysMtrBSttrTemp_Inv : 19|1@0+ (1,0) [0|1] "" VDM,ECP_E

BO_ 1471 PDU_2172: 6 Vector__XXX
 SG_ BECM2ERDTC_CdNum : 3|12@0+ (1,0) [0|4095] "Counts" ECP_E
 SG_ PIMRI_VECM_RcntlyProgInd : 5|2@0+ (1,0) [0|3] "" ECM,PCM,ECP_E
 SG_ PIMRI_VECM_PrmntDTCInd : 6|1@0+ (1,0) [0|1] "" ECM,PCM,ECP_E
 SG_ PIMRI_VECM_FltsPrsntInd : 7|1@0+ (1,0) [0|1] "" ECM,PCM,ECP_E
 SG_ BECM2EmsRltMlfAtv : 19|1@0+ (1,0) [0|1] "" ECP_E
 SG_ BECM2ERDTC_SysDes : 23|4@0+ (1,0) [0|15] "" ECP_E

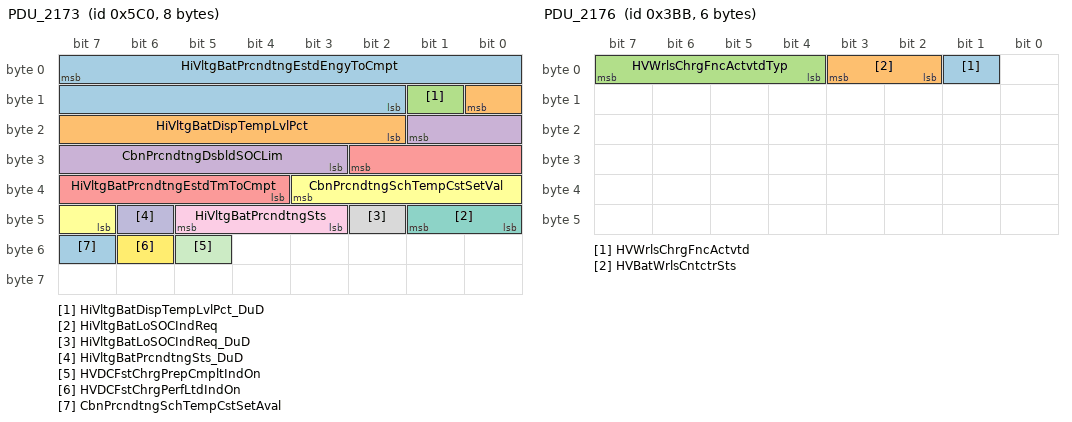
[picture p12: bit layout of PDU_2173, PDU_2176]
BO_ 1472 PDU_2173: 8 Vector__XXX
 SG_ HiVltgBatPrcndtngEstdEngyToCmpt : 7|14@0+ (0.01,0) [0|163.83] "kWh" CGM
 SG_ HiVltgBatDispTempLvlPct : 8|7@0+ (1,0) [0|127] "%" CGM
 SG_ HiVltgBatDispTempLvlPct_DuD : 9|1@0+ (1,0) [0|1] "" CGM
 SG_ CbnPrcndtngDsbldSOCLim : 17|7@0+ (1,0) [0|127] "%" CGM
 SG_ HiVltgBatPrcndtngEstdTmToCmpt : 26|7@0+ (1,0) [0|127] "min" CGM
 SG_ CbnPrcndtngSchTempCstSetVal : 35|5@0+ (0.5,16) [16|31.5] "Deg C" CGM
 SG_ HiVltgBatLoSOCIndReq : 41|2@0+ (1,0) [0|3] "" CGM
 SG_ HiVltgBatLoSOCIndReq_DuD : 42|1@0+ (1,0) [0|1] "" CGM
 SG_ HiVltgBatPrcndtngSts : 45|3@0+ (1,0) [0|5] "" CGM
 SG_ HiVltgBatPrcndtngSts_DuD : 46|1@0+ (1,0) [0|1] "" CGM
 SG_ HVDCFstChrgPrepCmpltIndOn : 53|1@0+ (1,0) [0|1] "" CGM
 SG_ HVDCFstChrgPerfLtdIndOn : 54|1@0+ (1,0) [0|1] "" CGM
 SG_ CbnPrcndtngSchTempCstSetAval : 55|1@0+ (1,0) [0|1] "" CGM

BO_ 954 PDU_2174: 12 Vector__XXX
 SG_ HiVltgIsltnResist : 7|16@0+ (1,0) [0|65535] "KOhm" VDM
 SG_ HiVltgBatMaxCellVltg : 22|13@0+ (0.001,0) [0|8.191] "Volt" VDM
 SG_ HiVltgBatMaxCellVltg_Inv : 23|1@0+ (1,0) [0|1] "" VDM
 SG_ HiVltgBatMinCellVltg : 24|13@0+ (0.001,0) [0|8.191] "Volt" VDM
 SG_ HiVltgBatMinCellVltg_Inv : 25|1@0+ (1,0) [0|1] "" VDM
 SG_ HiVltgBatMaxCellVltgNum : 43|7@0+ (1,1) [1|128] "" VDM
 SG_ HiVltgBatMaxTempSnsrNum : 52|7@0+ (1,1) [1|128] "" VDM
 SG_ HiVltgBatMinCellVltgNum : 61|7@0+ (1,1) [1|128] "cell" VDM
 SG_ HiVltgBatMinTempSnsrNum : 70|7@0+ (1,1) [1|128] "" VDM
 SG_ AuxPwrModDCDCStat : 79|1@0+ (1,0) [0|1] "" VDM

BO_ 178 PDU_2175: 6 Vector__XXX
 SG_ PrplSysInvrtADCCurrAuth : 7|15@0- (0.1,0) [-1638.4|1638.3] "Amp" BSM,VDM
 SG_ PrplSysInvrtADCCurrAuth_Inv : 8|1@0+ (1,0) [0|1] "" BSM,VDM

BO_ 955 PDU_2176: 6 Vector__XXX
 SG_ HVWrlsChrgFncActvtd : 1|1@0+ (1,0) [0|1] "" Vector__XXX
 SG_ HVBatWrlsCntctrSts : 3|2@0+ (1,0) [0|2] "" Vector__XXX
 SG_ HVWrlsChrgFncActvtdTyp : 7|4@0+ (1,0) [0|11] "" Vector__XXX

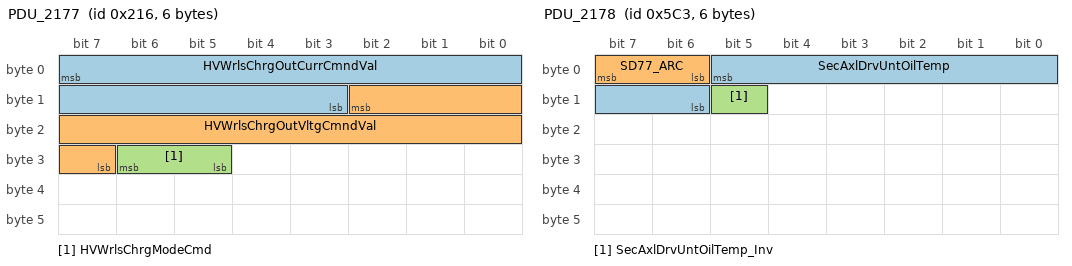
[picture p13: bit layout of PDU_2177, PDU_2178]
BO_ 534 PDU_2177: 6 Vector__XXX
 SG_ HVWrlsChrgOutCurrCmndVal : 7|13@0+ (0.02,0) [0|163.82] "A" Vector__XXX
 SG_ HVWrlsChrgOutVltgCmndVal : 10|12@0+ (0.125,0) [0|511.875] "V" Vector__XXX
 SG_ HVWrlsChrgModeCmd : 30|2@0+ (1,0) [0|2] "" Vector__XXX

BO_ 1475 PDU_2178: 6 Vector__XXX
 SG_ SecAxlDrvUntOilTemp : 5|8@0+ (1,-40) [-40|215] "deg C" ECM,PCM,ECP_E
 SG_ SD77_ARC : 7|2@0+ (1,0) [0|3] "" ECM,PCM,ECP_E
 SG_ SecAxlDrvUntOilTemp_Inv : 13|1@0+ (1,0) [0|1] "" ECM,PCM,ECP_E

BO_ 1435 PDU_2179: 6 Vector__XXX
 SG_ RrStrgModeSeltnIndOn : 4|1@0+ (1,0) [0|1] "" ACP2_MCU,CGM,EOCM,EOCM_HC_Superset,FCM
 SG_ RrStrgModeUnvIndReq : 7|3@0+ (1,0) [0|6] "" ACP2_MCU,CGM,EOCM,EOCM_HC_Superset,FCM

BO_ 1470 PDU_2180: 6 Vector__XXX
 SG_ Sig4476 : 7|1@0+ (1,0) [0|1] "" ECM

BO_ 1476 PDU_2181: 6 Vector__XXX
 SG_ Sig5753 : 4|2@0+ (1,0) [0|3] "" ECM,PCM
 SG_ Sig5752 : 6|2@0+ (1,0) [0|3] "" ECM,PCM
 SG_ Sig5020 : 7|1@0+ (1,0) [0|1] "" ECM,PCM

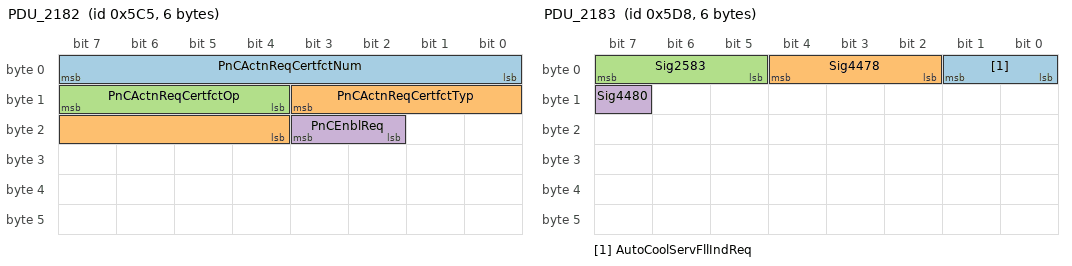
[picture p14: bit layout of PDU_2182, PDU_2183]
BO_ 1477 PDU_2182: 6 Vector__XXX
 SG_ PnCActnReqCertfctNum : 7|8@0+ (1,0) [0|255] "" VICM
 SG_ PnCActnReqCertfctTyp : 11|8@0+ (1,0) [0|14] "" VICM
 SG_ PnCActnReqCertfctOp : 15|4@0+ (1,0) [0|4] "" VICM
 SG_ PnCEnblReq : 19|2@0+ (1,0) [0|3] "" VICM

BO_ 1496 PDU_2183: 6 Vector__XXX
 SG_ AutoCoolServFllIndReq : 1|2@0+ (1,0) [0|3] "" CGM
 SG_ Sig4478 : 4|3@0+ (1,0) [0|7] "" CGM
 SG_ Sig2583 : 7|3@0+ (1,0) [0|4] "" CGM
 SG_ Sig4480 : 15|1@0+ (1,0) [0|1] "" CGM

BO_ 1504 PDU_2184: 6 Vector__XXX
 SG_ PrplSysChsSysPriAxlRtTrqReqSts : 4|3@0+ (1,0) [0|6] "" EBCM
 SG_ PrplSysChsSysPriAxlLtTrqReqSts : 7|3@0+ (1,0) [0|6] "" EBCM

BO_ 1505 PDU_2185: 6 Vector__XXX
 SG_ PrplSysElecPrkBrkApplReqd : 7|1@0+ (1,0) [0|1] "" EBCM

BO_ 74 PDU_2186: 6 Vector__XXX
 SG_ PrplSysAxlTrqDstTrqCmdPriLt : 7|15@0+ (2,-22534) [-22534|43000] "Nm" EBCM
 SG_ PrplSysAxlTrqDstTrqCmdPriRt : 8|15@0+ (2,-22534) [-22534|43000] "Nm" EBCM
 SG_ DrvMtrSysFltd : 25|1@0+ (1,0) [0|1] "" EBCM

BO_ 1535 PDU_2187: 6 Vector__XXX
 SG_ ICMTrngOncmgTrfcChmEvntStat : 3|2@0+ (1,0) [0|2] "" CGM
 SG_ ICMRtChmEvntStat : 5|2@0+ (1,0) [0|2] "" CGM
 SG_ ICMLtChmEvntStat : 7|2@0+ (1,0) [0|2] "" CGM

BO_ 1811 PDU_2188: 6 Vector__XXX
 SG_ RIMUnvTlgtIndOn : 4|1@0+ (1,0) [0|1] "" CGM
 SG_ ICMWrnIndReq : 7|3@0+ (1,0) [0|3] "" CGM

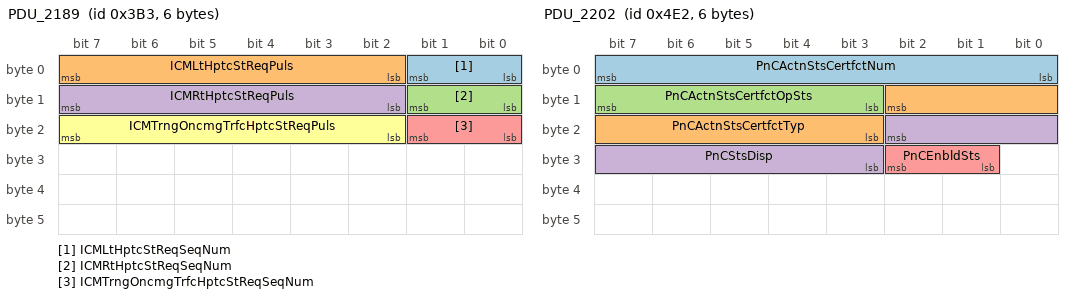
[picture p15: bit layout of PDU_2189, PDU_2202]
BO_ 947 PDU_2189: 6 Vector__XXX
 SG_ ICMLtHptcStReqSeqNum : 1|2@0+ (1,0) [0|3] "" CGM
 SG_ ICMLtHptcStReqPuls : 7|6@0+ (1,0) [0|63] "" CGM
 SG_ ICMRtHptcStReqSeqNum : 9|2@0+ (1,0) [0|3] "" CGM
 SG_ ICMRtHptcStReqPuls : 15|6@0+ (1,0) [0|63] "" CGM
 SG_ ICMTrngOncmgTrfcHptcStReqSeqNum : 17|2@0+ (1,0) [0|3] "" CGM
 SG_ ICMTrngOncmgTrfcHptcStReqPuls : 23|6@0+ (1,0) [0|63] "" CGM

BO_ 1812 PDU_2193: 64 Vector__XXX
 SG_ PnCCertStsDispCertIssdFrmNm : 7|496@0+ (1,0) [0|0] "" Vector__XXX
 SG_ PnCCertStsDispCertNum2 : 503|8@0+ (1,0) [0|255] "" Vector__XXX
 SG_ PnCCertStsDispCertTyp2 : 511|8@0+ (1,0) [0|5] "" Vector__XXX

BO_ 1253 PDU_2194: 64 Vector__XXX
 SG_ PnCCertStsDispCertIssdToNm : 7|496@0+ (1,0) [0|0] "" Vector__XXX
 SG_ PnCCertStsDispCertNum3 : 503|8@0+ (1,0) [0|255] "" Vector__XXX
 SG_ PnCCertStsDispCertTyp3 : 511|8@0+ (1,0) [0|5] "" Vector__XXX

BO_ 1813 PDU_2195: 64 Vector__XXX
 SG_ PnCCertStsDispCertExpiryDate : 7|192@0+ (1,0) [0|0] "" Vector__XXX
 SG_ PnCCertStsDispCertIssDate : 199|192@0+ (1,0) [0|0] "" Vector__XXX
 SG_ PnCCertStsDispCertNum4 : 391|8@0+ (1,0) [0|255] "" Vector__XXX
 SG_ PnCCertStsDispCertTyp4 : 399|8@0+ (1,0) [0|5] "" Vector__XXX
 SG_ PnCCertStsDispCertNum1 : 407|8@0+ (1,0) [0|255] "" Vector__XXX
 SG_ PnCCertStsDispCertTyp1 : 412|8@0+ (1,0) [0|5] "" Vector__XXX
 SG_ PnCCertStsDispCertSts : 415|3@0+ (1,0) [0|3] "" Vector__XXX
 SG_ PnCCertStsDispNumOfCertsInstld : 420|8@0+ (1,0) [0|255] "" Vector__XXX
 SG_ PnCCertStsDispNumOfCertsSuptd : 428|8@0+ (1,0) [0|255] "" Vector__XXX

BO_ 1252 PDU_2196: 48 Vector__XXX
 SG_ PnCCertStsDispCertIdNum : 7|144@0+ (1,0) [0|0] "" Vector__XXX
 SG_ PnCCertStsDispCertNum5 : 151|8@0+ (1,0) [0|255] "" Vector__XXX
 SG_ PnCCertStsDispCertTyp5 : 159|8@0+ (1,0) [0|5] "" Vector__XXX
 SG_ PnCPrvsngCertID : 167|144@0+ (1,0) [0|0] "" Vector__XXX

BO_ 957 PDU_2197: 6 Vector__XXX
 SG_ Sig0071 : 7|1@0+ (1,0) [0|1] "" ECM

BO_ 116 PDU_2198: 6 Vector__XXX
 SG_ HVBatOutOfEngyRdcdPrplReq : 7|1@0+ (1,0) [0|1] "" ECM,ECP_E

BO_ 958 PDU_2199: 6 Vector__XXX
 SG_ Sig0070 : 7|1@0+ (1,0) [0|1] "" BSM

BO_ 1814 PDU_2200: 6 Vector__XXX
 SG_ DrvMtrInvrt3MaxTemp : 6|8@0+ (1,-40) [-40|215] "deg C" VICM,ECP_E,ECP_S
 SG_ DrvMtrInvrt3MaxTemp_Inv : 7|1@0+ (1,0) [0|1] "" VICM,ECP_E,ECP_S

BO_ 1815 PDU_2201: 6 Vector__XXX
 SG_ ManRgnModeOvrrdn : 7|1@0+ (1,0) [0|1] "" Vector__XXX

BO_ 1250 PDU_2202: 6 Vector__XXX
 SG_ PnCActnStsCertfctNum : 7|8@0+ (1,0) [0|255] "" CGM
 SG_ PnCActnStsCertfctTyp : 10|8@0+ (1,0) [0|14] "" CGM
 SG_ PnCActnStsCertfctOpSts : 15|5@0+ (1,0) [0|17] "" CGM
 SG_ PnCStsDisp : 18|8@0+ (1,0) [0|8] "" CGM
 SG_ PnCEnbldSts : 26|2@0+ (1,0) [0|2] "" CGM

BO_ 659 PDU_2204: 12 Vector__XXX
 SG_ GNSSVel01EstVel : 7|15@0- (0.01,0) [-163.84|163.83] "" ECP_E
 SG_ GNSSVel01EstVelUncrtnty : 8|8@0+ (0.01,0) [0|2.55] "" ECP_E
 SG_ GNSSVel01EstVelUncrtnty_DuD : 16|1@0+ (1,0) [0|1] "" ECP_E
 SG_ GNSSVel01NrthVel : 28|15@0- (0.01,0) [-163.84|163.83] "" ECP_E
 SG_ GNSSVel01EstVel_Inv : 29|1@0+ (1,0) [0|1] "" ECP_E
 SG_ GNSSVel01EstVel_DuD : 30|1@0+ (1,0) [0|1] "" ECP_E
 SG_ GNSSVel01EstVelUncrtnty_Inv : 31|1@0+ (1,0) [0|1] "" ECP_E
 SG_ GNSSVel01NrthVelUncrtnty : 45|8@0+ (0.01,0) [0|2.55] "" ECP_E
 SG_ GNSSVel02UpVel : 49|14@0- (0.01,0) [-81.92|81.91] "" ECP_E
 SG_ GNSSVel01NrthVel_Inv : 50|1@0+ (1,0) [0|1] "" ECP_E
 SG_ GNSSVel01NrthVel_DuD : 51|1@0+ (1,0) [0|1] "" ECP_E
 SG_ GNSSVel01NrthVelUncrtnty_Inv : 52|1@0+ (1,0) [0|1] "" ECP_E
 SG_ GNSSVel01NrthVelUncrtnty_DuD : 53|1@0+ (1,0) [0|1] "" ECP_E
 SG_ GNSSVel02UpVelUncrtnty : 67|8@0+ (0.01,0) [0|2.55] "" ECP_E
 SG_ GNSSVel02UpVel_Inv : 72|1@0+ (1,0) [0|1] "" ECP_E
 SG_ GNSSVel02UpVel_DuD : 73|1@0+ (1,0) [0|1] "" ECP_E
 SG_ GNSSVel02UpVelUncrtnty_Inv : 74|1@0+ (1,0) [0|1] "" ECP_E
 SG_ GNSSVel02UpVelUncrtnty_DuD : 75|1@0+ (1,0) [0|1] "" ECP_E
 SG_ GPSQM_PPSMode : 80|3@0+ (1,0) [0|7] "" ACP2_MCU
 SG_ GPSQM_PPSMode_Inv : 81|1@0+ (1,0) [0|1] "" ACP2_MCU
 SG_ WndPstnStsRR : 84|3@0+ (1,0) [0|7] "" ACP2_MCU,EOCM,EOCM_HC_Superset
 SG_ WndPstnStsLR : 87|3@0+ (1,0) [0|7] "" ACP2_MCU,EOCM,EOCM_HC_Superset

BO_ 1249 PDU_2205: 6 Vector__XXX
 SG_ HiBmSelSwActv : 4|1@0+ (1,0) [0|1] "" AHL_AFL
 SG_ AE44BkBtnSts : 5|1@0+ (1,0) [0|1] "" ACP2_MCU,EOCM,EOCM_HC_Superset
 SG_ AE44SuprPrkSts : 7|2@0+ (1,0) [0|2] "" ACP2_MCU,EOCM,EOCM_HC_Superset

BO_ 961 PDU_2206: 6 Vector__XXX
 SG_ LvlgSysFrtAxlEstdLd : 7|9@0+ (10,0) [0|5110] "kg" ECP_E
 SG_ LvlgSysRrAxlEstdLd : 14|9@0+ (10,0) [0|5110] "kg" ECP_E

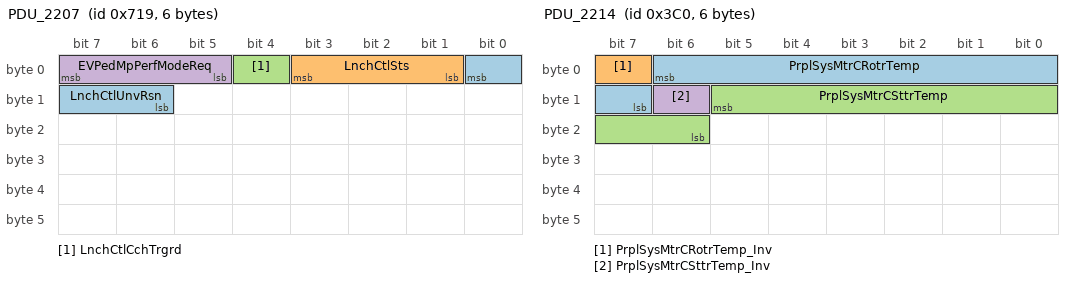
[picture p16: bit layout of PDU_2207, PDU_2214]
BO_ 1817 PDU_2207: 6 Vector__XXX
 SG_ LnchCtlUnvRsn : 0|3@0+ (1,0) [0|7] "" CGM
 SG_ LnchCtlSts : 3|3@0+ (1,0) [0|7] "" CGM,ECP_E
 SG_ LnchCtlCchTrgrd : 4|1@0+ (1,0) [0|1] "" CGM
 SG_ EVPedMpPerfModeReq : 7|3@0+ (1,0) [0|7] "" ECP_E

BO_ 31 PDU_2208: 6 Vector__XXX
 SG_ Sig2415 : 7|1@0+ (1,0) [0|1] "" ECP_X1

BO_ 1248 PDU_2210: 6 Vector__XXX
 SG_ VirtRrAxlLckSts : 7|2@0+ (1,0) [0|3] "" CGM

BO_ 960 PDU_2214: 6 Vector__XXX
 SG_ PrplSysMtrCRotrTemp : 6|8@0+ (1,-40) [-40|215] "deg C" ECP_E,ECP_S
 SG_ PrplSysMtrCRotrTemp_Inv : 7|1@0+ (1,0) [0|1] "" ECP_E,ECP_S
 SG_ PrplSysMtrCSttrTemp : 13|8@0+ (1,-40) [-40|215] "deg C" ECP_E,ECP_S
 SG_ PrplSysMtrCSttrTemp_Inv : 14|1@0+ (1,0) [0|1] "" ECP_E,ECP_S

BO_ 117 PDU_2215: 6 Vector__XXX
 SG_ Sig2414 : 7|3@0+ (1,0) [0|5] "" ECM

BO_ 1818 PDU_2216: 6 Vector__XXX
 SG_ SuprRmtPrkAval : 7|1@0+ (1,0) [0|1] "" CGM

BO_ 1247 PDU_2218: 12 Vector__XXX
 SG_ Sig4600 : 0|1@0+ (1,0) [0|1] "" CGM
 SG_ Sig4599 : 1|1@0+ (1,0) [0|1] "" CGM
 SG_ Sig4598 : 2|1@0+ (1,0) [0|1] "" CGM
 SG_ Sig4597 : 3|1@0+ (1,0) [0|1] "" CGM
 SG_ Sig4596 : 4|1@0+ (1,0) [0|1] "" CGM
 SG_ Sig4595 : 5|1@0+ (1,0) [0|1] "" CGM
 SG_ E49HrnChrpReq : 7|2@0+ (1,0) [0|2] "" CGM
 SG_ Sig4608 : 8|1@0+ (1,0) [0|1] "" CGM
 SG_ Sig4607 : 9|1@0+ (1,0) [0|1] "" CGM
 SG_ Sig4606 : 10|1@0+ (1,0) [0|1] "" CGM
 SG_ Sig4605 : 11|1@0+ (1,0) [0|1] "" CGM
 SG_ Sig4604 : 12|1@0+ (1,0) [0|1] "" CGM
 SG_ Sig4603 : 13|1@0+ (1,0) [0|1] "" CGM
 SG_ Sig4602 : 14|1@0+ (1,0) [0|1] "" CGM
 SG_ Sig4601 : 15|1@0+ (1,0) [0|1] "" CGM
 SG_ Sig4802 : 16|1@0+ (1,0) [0|1] "" CGM
 SG_ Sig4801 : 17|1@0+ (1,0) [0|1] "" CGM
 SG_ Sig4800 : 18|1@0+ (1,0) [0|1] "" CGM
 SG_ Sig4688 : 19|1@0+ (1,0) [0|1] "" CGM
 SG_ Sig4687 : 20|1@0+ (1,0) [0|1] "" CGM
 SG_ Sig4626 : 21|1@0+ (1,0) [0|1] "" CGM
 SG_ Sig4625 : 22|1@0+ (1,0) [0|1] "" CGM
 SG_ Sig4609 : 23|1@0+ (1,0) [0|1] "" CGM
 SG_ Sig4810 : 24|1@0+ (1,0) [0|1] "" CGM
 SG_ Sig4809 : 25|1@0+ (1,0) [0|1] "" CGM
 SG_ Sig4808 : 26|1@0+ (1,0) [0|1] "" CGM
 SG_ Sig4807 : 27|1@0+ (1,0) [0|1] "" CGM
 SG_ Sig4806 : 28|1@0+ (1,0) [0|1] "" CGM
 SG_ Sig4805 : 29|1@0+ (1,0) [0|1] "" CGM
 SG_ Sig4804 : 30|1@0+ (1,0) [0|1] "" CGM
 SG_ Sig4803 : 31|1@0+ (1,0) [0|1] "" CGM
 SG_ Sig4826 : 32|1@0+ (1,0) [0|1] "" CGM
 SG_ Sig4825 : 33|1@0+ (1,0) [0|1] "" CGM
 SG_ Sig4824 : 34|1@0+ (1,0) [0|1] "" CGM
 SG_ Sig4823 : 35|1@0+ (1,0) [0|1] "" CGM
 SG_ Sig4814 : 36|1@0+ (1,0) [0|1] "" CGM
 SG_ Sig4813 : 37|1@0+ (1,0) [0|1] "" CGM
 SG_ Sig4812 : 38|1@0+ (1,0) [0|1] "" CGM
 SG_ Sig4811 : 39|1@0+ (1,0) [0|1] "" CGM
 SG_ Sig4834 : 40|1@0+ (1,0) [0|1] "" CGM
 SG_ Sig4833 : 41|1@0+ (1,0) [0|1] "" CGM
 SG_ Sig4832 : 42|1@0+ (1,0) [0|1] "" CGM
 SG_ Sig4831 : 43|1@0+ (1,0) [0|1] "" CGM
 SG_ Sig4830 : 44|1@0+ (1,0) [0|1] "" CGM
 SG_ Sig4829 : 45|1@0+ (1,0) [0|1] "" CGM
 SG_ Sig4828 : 46|1@0+ (1,0) [0|1] "" CGM
 SG_ Sig4827 : 47|1@0+ (1,0) [0|1] "" CGM
 SG_ Sig4860 : 48|1@0+ (1,0) [0|1] "" CGM
 SG_ Sig4859 : 49|1@0+ (1,0) [0|1] "" CGM
 SG_ Sig4858 : 50|1@0+ (1,0) [0|1] "" CGM
 SG_ Sig4857 : 51|1@0+ (1,0) [0|1] "" CGM
 SG_ Sig4856 : 52|1@0+ (1,0) [0|1] "" CGM
 SG_ Sig4837 : 53|1@0+ (1,0) [0|1] "" CGM
 SG_ Sig4836 : 54|1@0+ (1,0) [0|1] "" CGM
 SG_ Sig4835 : 55|1@0+ (1,0) [0|1] "" CGM
 SG_ Sig4883 : 56|1@0+ (1,0) [0|1] "" CGM
 SG_ Sig4882 : 57|1@0+ (1,0) [0|1] "" CGM
 SG_ Sig4881 : 58|1@0+ (1,0) [0|1] "" CGM
 SG_ Sig4880 : 59|1@0+ (1,0) [0|1] "" CGM
 SG_ Sig4879 : 60|1@0+ (1,0) [0|1] "" CGM
 SG_ Sig4878 : 61|1@0+ (1,0) [0|1] "" CGM
 SG_ Sig4862 : 62|1@0+ (1,0) [0|1] "" CGM
 SG_ Sig4861 : 63|1@0+ (1,0) [0|1] "" CGM
 SG_ Sig4884 : 71|1@0+ (1,0) [0|1] "" CGM

BO_ 661 PDU_2219: 6 Vector__XXX
 SG_ LIBSOCCalReqd : 7|1@0+ (1,0) [0|1] "" Vector__XXX

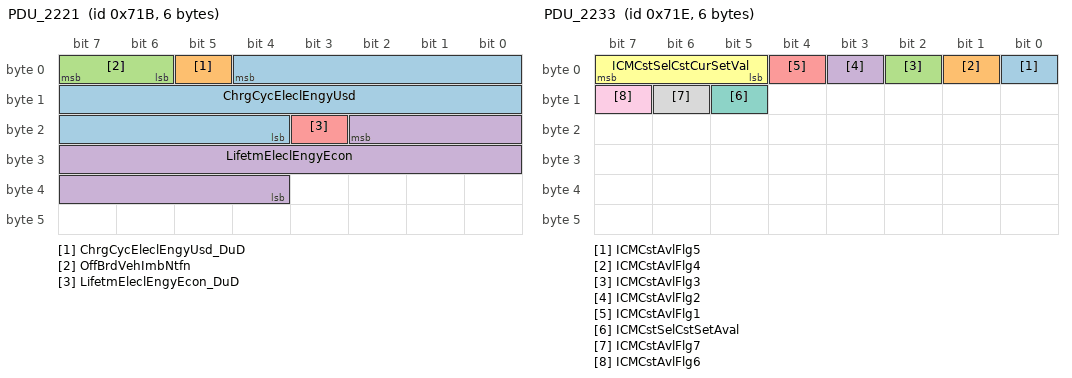
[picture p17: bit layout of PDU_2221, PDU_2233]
BO_ 1819 PDU_2221: 6 Vector__XXX
 SG_ ChrgCycEleclEngyUsd : 4|17@0+ (0.1,0) [0|13107.1] "kWh" CGM
 SG_ ChrgCycEleclEngyUsd_DuD : 5|1@0+ (1,0) [0|1] "" CGM
 SG_ OffBrdVehImbNtfn : 7|2@0+ (1,0) [0|3] "" CGM
 SG_ LifetmEleclEngyEcon : 18|15@0- (0.1,0) [-1638.4|1638.3] "" CGM
 SG_ LifetmEleclEngyEcon_DuD : 19|1@0+ (1,0) [0|1] "" CGM

BO_ 176 PDU_2222: 6 Vector__XXX
 SG_ Sig4428 : 7|4@0+ (1,0) [0|15] "counts" ECP_X1

BO_ 536 PDU_2223: 6 Vector__XXX
 SG_ Sig2531 : 1|11@0+ (0.5,130) [130|1153.5] "Ohm" ECM
 SG_ Sig2533 : 3|2@0+ (1,0) [0|3] "" ECM
 SG_ Sig4427 : 7|4@0+ (1,0) [0|15] "counts" ECM
 SG_ Sig2532 : 22|11@0+ (0.5,130) [130|1153.5] "Ohm" ECM

BO_ 1246 PDU_2224: 6 Vector__XXX
 SG_ HVThrmlPwrCnsmd : 7|12@0+ (0.1,0) [0|409.5] "KW" VDM
 SG_ HVThrmlPwrCnsmd_Inv : 10|1@0+ (1,0) [0|1] "" VDM
 SG_ HVThrmlPwrCnsmd_DuD : 11|1@0+ (1,0) [0|1] "" VDM

BO_ 959 PDU_2225: 6 Vector__XXX
 SG_ RmtPRNDMBklgtLvl : 7|8@0+ (0.392157,0) [0|100] "%" ECM,PCM
 SG_ RmtPRNDMIndLvl : 15|8@0+ (0.392157,0) [0|100] "%" ECM,PCM

BO_ 73 PDU_2226: 6 Vector__XXX
 SG_ Sig4939 : 7|12@0+ (0.5,-848) [-848|1199.5] "Nm" Vector__XXX
 SG_ Sig4940 : 11|1@0+ (1,0) [0|1] "" Vector__XXX

BO_ 1821 PDU_2229: 6 Vector__XXX
 SG_ EngCmptAjr : 6|1@0+ (1,0) [0|1] "" AHL_AFL
 SG_ EngCmptAjr_Inv : 7|1@0+ (1,0) [0|1] "" AHL_AFL

BO_ 738 PDU_2230: 6 Vector__XXX
 SG_ Sig7819 : 7|2@0+ (1,0) [0|2] "" CGM

BO_ 1245 PDU_2231: 6 Vector__XXX
 SG_ ElecShfPriLoManSeltnIndReq : 7|2@0+ (1,0) [0|2] "" CGM

BO_ 1244 PDU_2232: 6 Vector__XXX
 SG_ DrLckLRStsAuth : 1|2@0+ (1,0) [0|2] "" ACP2_MCU,EOCM,EOCM_HC_Superset
 SG_ DrLckLFStsAuth : 3|2@0+ (1,0) [0|2] "" ACP2_MCU,EOCM,EOCM_HC_Superset
 SG_ CntrStckDispFlrIndOn : 4|1@0+ (1,0) [0|1] "" ACP2_MCU,EBCM,EOCM,EOCM_HC_Superset
 SG_ ICMCstChgSetReq : 7|3@0+ (1,0) [0|4] "" ACP2_MCU,EOCM,EOCM_HC_Superset,FCM
 SG_ PrplDispExtndCpbltyLvlPct_DuD : 8|1@0+ (1,0) [0|1] "" EBCM
 SG_ Sig7636 : 9|1@0+ (1,0) [0|1] "" TCM
 SG_ CrnrLmpRtCmndOn : 10|1@0+ (1,0) [0|1] "" AHL_AFL
 SG_ CrnrLmpLtCmndOn : 11|1@0+ (1,0) [0|1] "" AHL_AFL
 SG_ DrLckRRStsAuth : 13|2@0+ (1,0) [0|2] "" ACP2_MCU,EOCM,EOCM_HC_Superset
 SG_ DrLckRFStsAuth : 15|2@0+ (1,0) [0|2] "" ACP2_MCU,EOCM,EOCM_HC_Superset
 SG_ DMSDrwIntnWrnDrvrResp : 16|1@0+ (1,0) [0|1] "" ACP2_MCU,EOCM_HC_Superset,FCM
 SG_ PrplDispExtndCpbltyLvlPct : 23|7@0+ (1,0) [0|127] "%" EBCM
 SG_ E44SftBtnSeltdStatRw : 26|2@0+ (1,0) [0|3] "" ACP2_MCU,EOCM,EOCM_HC_Superset
 SG_ FrtCmptShftrLckReqd : 27|1@0+ (1,0) [0|1] "" ECM,PCM
 SG_ VirtCtlVehEmrgOffSwReqd : 28|1@0+ (1,0) [0|1] "" ACP2_MCU,EOCM,EOCM_HC_Superset
 SG_ VirtCtlVehOffSwReq : 30|2@0+ (1,0) [0|2] "" ACP2_MCU,EOCM,EOCM_HC_Superset
 SG_ DrMtzdStBltUnIndOn : 31|1@0+ (1,0) [0|1] "" ACP2_MCU,EOCM_HC_Superset,FCM

BO_ 1822 PDU_2233: 6 Vector__XXX
 SG_ ICMCstAvlFlg5 : 0|1@0+ (1,0) [0|1] "" CGM
 SG_ ICMCstAvlFlg4 : 1|1@0+ (1,0) [0|1] "" CGM
 SG_ ICMCstAvlFlg3 : 2|1@0+ (1,0) [0|1] "" CGM
 SG_ ICMCstAvlFlg2 : 3|1@0+ (1,0) [0|1] "" CGM
 SG_ ICMCstAvlFlg1 : 4|1@0+ (1,0) [0|1] "" CGM
 SG_ ICMCstSelCstCurSetVal : 7|3@0+ (1,0) [0|4] "" CGM
 SG_ ICMCstSelCstSetAval : 13|1@0+ (1,0) [0|1] "" CGM
 SG_ ICMCstAvlFlg7 : 14|1@0+ (1,0) [0|1] "" CGM
 SG_ ICMCstAvlFlg6 : 15|1@0+ (1,0) [0|1] "" CGM

BO_ 175 PDU_2234: 6 Vector__XXX
 SG_ PrcsrSecurPtrn_ECP_E : 7|4@0+ (1,0) [0|15] "counts" VICM,ECP_S,ECP_S2

BO_ 537 PDU_2235: 6 Vector__XXX
 SG_ PrcsrSecurPtrn_VICM : 7|4@0+ (1,0) [0|15] "counts" ECP_E

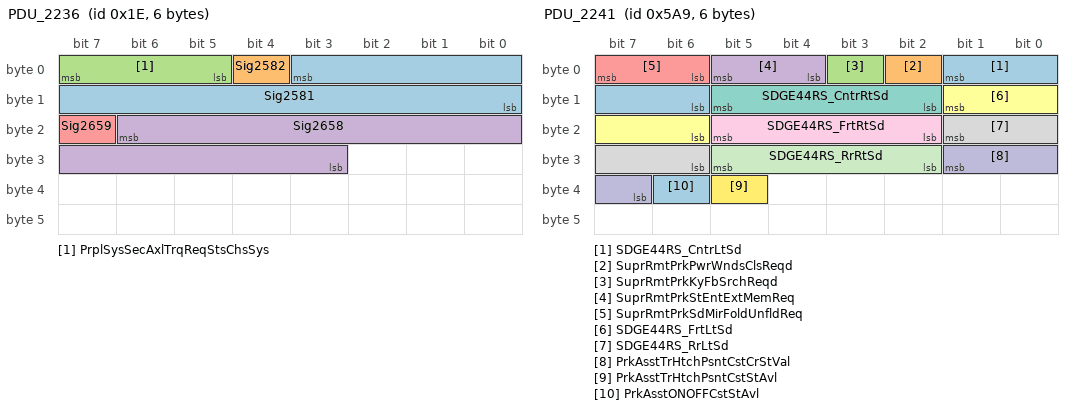
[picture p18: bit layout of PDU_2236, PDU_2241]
BO_ 30 PDU_2236: 6 Vector__XXX
 SG_ Sig2581 : 3|12@0+ (1,-848) [-848|3247] "Nm" TCM
 SG_ Sig2582 : 4|1@0+ (1,0) [0|1] "" TCM
 SG_ PrplSysSecAxlTrqReqStsChsSys : 7|3@0+ (1,0) [0|6] "" EBCM
 SG_ Sig2658 : 22|12@0+ (1,-848) [-848|3247] "Nm" TCM
 SG_ Sig2659 : 23|1@0+ (1,0) [0|1] "" TCM

BO_ 1243 PDU_2237: 48 Vector__XXX
 SG_ NextChrgDestLat : 7|30@0- (1,0) [-5.36871e+008|5.36871e+008] "ms arc" VICM
 SG_ NextChrgDestLng : 25|31@0- (1,0) [-1.07374e+009|1.07374e+009] "ms arc" VICM
 SG_ NavRtePrdtdCustUsblSOC : 57|16@0+ (0.00152588,0) [0|99.9985] "%" VICM
 SG_ NavRteChgOcc : 58|1@0+ (1,0) [0|1] "" VICM
 SG_ NavRtePrdtdOAT : 73|7@0+ (1,-40) [-40|87] "C" VICM
 SG_ NavRtePrdtdRdLdPwr : 82|17@0- (0.01,0) [-655.36|655.35] "kW" VICM
 SG_ NavRtePrdtdVehSpd : 97|8@0+ (1,0) [0|255] "km/h" VICM
 SG_ NavRteSts : 105|3@0+ (1,0) [0|4] "" VICM
 SG_ NavRtePrdtdEngyDelt : 112|17@0- (0.01,0) [-655.36|655.35] "kWh" VICM
 SG_ NavRteTmIdx1 : 118|6@0+ (1,0) [0|63] "minute" VICM
 SG_ NavRtePrdtdLat : 143|30@0- (1,0) [-5.36871e+008|5.36871e+008] "ms arc" VICM
 SG_ NavRteTmIdx3 : 161|6@0+ (1,0) [0|63] "minute" VICM
 SG_ NavRtePrdtdElvtn : 171|15@0- (1,0) [-16384|16383] "m" VICM
 SG_ NavRtePrdtdLng : 188|31@0- (1,0) [-1.07374e+009|1.07374e+009] "ms arc" VICM
 SG_ NavRteTmIdx2 : 221|6@0+ (1,0) [0|63] "minute" VICM
 SG_ NextChrgDestDistToArvl : 231|11@0+ (1,0) [0|2047] "km" VICM
 SG_ NextChrgDestPwrLvl : 236|16@0+ (0.01,0) [0|655.35] "kW" VICM
 SG_ NextChrgDestTmToArvl : 250|11@0+ (1,0) [0|2047] "minute" VICM
 SG_ NextChrgDestSts : 252|2@0+ (1,0) [0|3] "" VICM

BO_ 174 PDU_2239: 6 Vector__XXX
 SG_ RegnOnDmndActv : 7|1@0+ (1,0) [0|1] "" ACP2_MCU,EOCM,EOCM_HC_Superset,FCM

BO_ 965 PDU_2240: 6 Vector__XXX
 SG_ OnePedDrvMdDrvrSeltnEnbld : 7|1@0+ (1,0) [0|1] "" EBCM

BO_ 1449 PDU_2241: 6 Vector__XXX
 SG_ SDGE44RS_CntrLtSd : 1|4@0+ (1,0) [0|14] "" CGM
 SG_ SuprRmtPrkPwrWndsClsReqd : 2|1@0+ (1,0) [0|1] "" CGM
 SG_ SuprRmtPrkKyFbSrchReqd : 3|1@0+ (1,0) [0|1] "" CGM
 SG_ SuprRmtPrkStEntExtMemReq : 5|2@0+ (1,0) [0|3] "" CGM
 SG_ SuprRmtPrkSdMirFoldUnfldReq : 7|2@0+ (1,0) [0|2] "" CGM
 SG_ SDGE44RS_FrtLtSd : 9|4@0+ (1,0) [0|14] "" CGM
 SG_ SDGE44RS_CntrRtSd : 13|4@0+ (1,0) [0|14] "" CGM
 SG_ SDGE44RS_RrLtSd : 17|4@0+ (1,0) [0|14] "" CGM
 SG_ SDGE44RS_FrtRtSd : 21|4@0+ (1,0) [0|14] "" CGM
 SG_ PrkAsstTrHtchPsntCstCrStVal : 25|3@0+ (1,0) [0|7] "" CGM
 SG_ SDGE44RS_RrRtSd : 29|4@0+ (1,0) [0|14] "" CGM
 SG_ PrkAsstTrHtchPsntCstStAvl : 37|1@0+ (1,0) [0|1] "" CGM
 SG_ PrkAsstONOFFCstStAvl : 38|1@0+ (1,0) [0|1] "" CGM

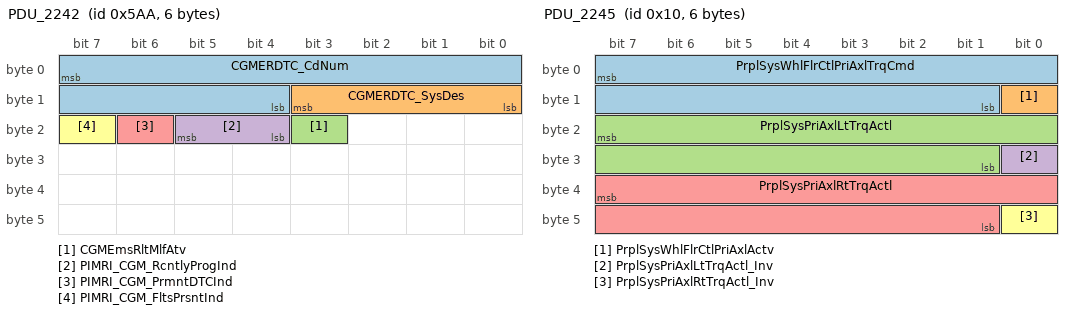
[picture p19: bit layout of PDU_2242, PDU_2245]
BO_ 1450 PDU_2242: 6 Vector__XXX
 SG_ CGMERDTC_CdNum : 7|12@0+ (1,0) [0|4095] "" ECM,PCM,ECP_E
 SG_ CGMERDTC_SysDes : 11|4@0+ (1,0) [0|15] "" ECM,PCM,ECP_E
 SG_ CGMEmsRltMlfAtv : 19|1@0+ (1,0) [0|1] "" ECM,PCM,ECP_E
 SG_ PIMRI_CGM_RcntlyProgInd : 21|2@0+ (1,0) [0|3] "" ECM,PCM,ECP_E
 SG_ PIMRI_CGM_PrmntDTCInd : 22|1@0+ (1,0) [0|1] "" ECM,PCM,ECP_E
 SG_ PIMRI_CGM_FltsPrsntInd : 23|1@0+ (1,0) [0|1] "" ECM,PCM,ECP_E

BO_ 1024 PDU_2243: 6 Vector__XXX
 SG_ Sig7635 : 0|1@0+ (1,0) [0|1] "" CGM
 SG_ Sig7637 : 7|7@0+ (1,0) [0|127] "%" CGM

BO_ 768 PDU_2244: 6 Vector__XXX
 SG_ ChsSysTracCtlTgtVel : 7|8@0+ (1,0) [0|255] "kph" ECP_E,ECP_S,ECP_S2

BO_ 16 PDU_2245: 6 Vector__XXX
 SG_ PrplSysWhlFlrCtlPriAxlTrqCmd : 7|15@0+ (2,-22534) [-22534|43000] "Nm" EBCM
 SG_ PrplSysWhlFlrCtlPriAxlActv : 8|1@0+ (1,0) [0|1] "" EBCM
 SG_ PrplSysPriAxlLtTrqActl : 23|15@0+ (2,-22534) [-22534|43000] "Nm" EBCM
 SG_ PrplSysPriAxlLtTrqActl_Inv : 24|1@0+ (1,0) [0|1] "" EBCM
 SG_ PrplSysPriAxlRtTrqActl : 39|15@0+ (2,-22534) [-22534|43000] "Nm" EBCM
 SG_ PrplSysPriAxlRtTrqActl_Inv : 40|1@0+ (1,0) [0|1] "" EBCM

BO_ 17 PDU_2246: 6 Vector__XXX
 SG_ PrplSysWhlFlrCtlSecAxlTrqCmd : 7|15@0+ (2,-22534) [-22534|43000] "Nm" EBCM
 SG_ PrplSysWhlFlrCtlSecAxlActv : 8|1@0+ (1,0) [0|1] "" EBCM

BO_ 18 PDU_2247: 6 Vector__XXX
 SG_ PrplSysWhlFlrCtlPriAxlLtTrqCmd : 7|15@0+ (2,-22534) [-22534|43000] "Nm" EBCM
 SG_ PrplSysWhlFlrCtlPriAxlLtActv : 8|1@0+ (1,0) [0|1] "" EBCM

BA_DEF_ SG_  "SignalType" STRING ;
BA_DEF_ SG_  "SignalLongName" STRING ;
BA_DEF_ BO_  "GenMsgCycleTime" INT 0 10000;
BA_DEF_ BO_  "GenMsgSendType" ENUM "cyclicX","spontanX","cyclicIfActiveX","spontanWithDelay","cyclicAndSpontanX","cyclicAndSpontanWithDelay","spontanWithRepetition","cyclicIfActiveAndSpontanWD";
BA_DEF_ BO_  "VFrameFormat" ENUM  "StandardCAN","ExtendedCAN","reserved","reserved","reserved","reserved","reserved","reserved","reserved","reserved","reserved","reserved","reserved","reserved","StandardCAN_FD","ExtendedCAN_FD";
BA_DEF_DEF_  "SignalType" "";
BA_DEF_DEF_  "SignalLongName" "";
BA_DEF_DEF_  "GenMsgCycleTime" 0;
BA_DEF_DEF_  "GenMsgSendType" "cyclicX";
BA_DEF_DEF_  "VFrameFormat" "StandardCAN";
BA_ "GenMsgCycleTime" BO_ 1484 1000;
BA_ "VFrameFormat" BO_ 1484 14;
BA_ "GenMsgCycleTime" BO_ 1485 1000;
BA_ "VFrameFormat" BO_ 1485 14;
BA_ "GenMsgCycleTime" BO_ 712 100;
BA_ "VFrameFormat" BO_ 712 14;
BA_ "GenMsgCycleTime" BO_ 731 100;
BA_ "VFrameFormat" BO_ 731 14;
BA_ "GenMsgCycleTime" BO_ 1503 1000;
BA_ "VFrameFormat" BO_ 1503 14;
BA_ "GenMsgCycleTime" BO_ 1509 1000;
BA_ "VFrameFormat" BO_ 1509 14;
BA_ "GenMsgCycleTime" BO_ 1510 1000;
BA_ "VFrameFormat" BO_ 1510 14;
BA_ "GenMsgCycleTime" BO_ 1511 1000;
BA_ "VFrameFormat" BO_ 1511 14;
BA_ "GenMsgCycleTime" BO_ 1512 1000;
BA_ "VFrameFormat" BO_ 1512 14;
BA_ "GenMsgCycleTime" BO_ 1513 1000;
BA_ "VFrameFormat" BO_ 1513 14;
BA_ "GenMsgCycleTime" BO_ 1514 1000;
BA_ "VFrameFormat" BO_ 1514 14;
BA_ "GenMsgCycleTime" BO_ 1515 1000;
BA_ "VFrameFormat" BO_ 1515 14;
BA_ "GenMsgCycleTime" BO_ 1516 1000;
BA_ "VFrameFormat" BO_ 1516 14;
BA_ "GenMsgCycleTime" BO_ 1517 1000;
BA_ "VFrameFormat" BO_ 1517 14;
BA_ "GenMsgCycleTime" BO_ 1518 1000;
BA_ "VFrameFormat" BO_ 1518 14;
BA_ "GenMsgCycleTime" BO_ 1519 1000;
BA_ "VFrameFormat" BO_ 1519 14;
BA_ "GenMsgCycleTime" BO_ 1520 1000;
BA_ "VFrameFormat" BO_ 1520 14;
BA_ "GenMsgCycleTime" BO_ 1521 1000;
BA_ "VFrameFormat" BO_ 1521 14;
BA_ "GenMsgCycleTime" BO_ 1522 1000;
BA_ "VFrameFormat" BO_ 1522 14;
BA_ "GenMsgCycleTime" BO_ 1523 1000;
BA_ "VFrameFormat" BO_ 1523 14;
BA_ "GenMsgCycleTime" BO_ 1524 1000;
BA_ "VFrameFormat" BO_ 1524 14;
BA_ "GenMsgCycleTime" BO_ 1525 1000;
BA_ "VFrameFormat" BO_ 1525 14;
BA_ "GenMsgCycleTime" BO_ 736 100;
BA_ "VFrameFormat" BO_ 736 14;
BA_ "GenMsgCycleTime" BO_ 949 500;
BA_ "VFrameFormat" BO_ 949 14;
BA_ "GenMsgCycleTime" BO_ 950 500;
BA_ "VFrameFormat" BO_ 950 14;
BA_ "GenMsgCycleTime" BO_ 951 500;
BA_ "VFrameFormat" BO_ 951 14;
BA_ "GenMsgCycleTime" BO_ 952 500;
BA_ "VFrameFormat" BO_ 952 14;
BA_ "GenMsgCycleTime" BO_ 1417 1000;
BA_ "VFrameFormat" BO_ 1417 14;
BA_ "GenMsgCycleTime" BO_ 1259 1000;
BA_ "VFrameFormat" BO_ 1259 14;
BA_ "GenMsgCycleTime" BO_ 40 10;
BA_ "VFrameFormat" BO_ 40 14;
BA_ "GenMsgCycleTime" BO_ 1465 1000;
BA_ "VFrameFormat" BO_ 1465 14;
BA_ "GenMsgCycleTime" BO_ 1466 1000;
BA_ "VFrameFormat" BO_ 1466 14;
BA_ "GenMsgCycleTime" BO_ 929 250;
BA_ "VFrameFormat" BO_ 929 14;
BA_ "GenMsgCycleTime" BO_ 1467 1000;
BA_ "VFrameFormat" BO_ 1467 14;
BA_ "GenMsgCycleTime" BO_ 1468 1000;
BA_ "VFrameFormat" BO_ 1468 14;
BA_ "GenMsgCycleTime" BO_ 931 250;
BA_ "VFrameFormat" BO_ 931 14;
BA_ "GenMsgCycleTime" BO_ 115 12.5;
BA_ "VFrameFormat" BO_ 115 14;
BA_ "GenMsgCycleTime" BO_ 194 25;
BA_ "VFrameFormat" BO_ 194 14;
BA_ "GenMsgCycleTime" BO_ 953 250;
BA_ "VFrameFormat" BO_ 953 14;
BA_ "GenMsgCycleTime" BO_ 1471 1000;
BA_ "VFrameFormat" BO_ 1471 14;
BA_ "GenMsgCycleTime" BO_ 1472 1000;
BA_ "VFrameFormat" BO_ 1472 14;
BA_ "GenMsgCycleTime" BO_ 954 250;
BA_ "VFrameFormat" BO_ 954 14;
BA_ "GenMsgCycleTime" BO_ 178 25;
BA_ "VFrameFormat" BO_ 178 14;
BA_ "GenMsgCycleTime" BO_ 955 250;
BA_ "VFrameFormat" BO_ 955 14;
BA_ "GenMsgCycleTime" BO_ 534 50;
BA_ "VFrameFormat" BO_ 534 14;
BA_ "GenMsgCycleTime" BO_ 1475 1000;
BA_ "VFrameFormat" BO_ 1475 14;
BA_ "GenMsgCycleTime" BO_ 1435 1000;
BA_ "VFrameFormat" BO_ 1435 14;
BA_ "GenMsgCycleTime" BO_ 1470 1000;
BA_ "VFrameFormat" BO_ 1470 14;
BA_ "GenMsgCycleTime" BO_ 1476 1000;
BA_ "VFrameFormat" BO_ 1476 14;
BA_ "GenMsgCycleTime" BO_ 1477 1000;
BA_ "VFrameFormat" BO_ 1477 14;
BA_ "GenMsgCycleTime" BO_ 1496 1000;
BA_ "VFrameFormat" BO_ 1496 14;
BA_ "GenMsgCycleTime" BO_ 1504 1000;
BA_ "VFrameFormat" BO_ 1504 14;
BA_ "GenMsgCycleTime" BO_ 1505 1000;
BA_ "VFrameFormat" BO_ 1505 14;
BA_ "GenMsgCycleTime" BO_ 74 12.5;
BA_ "VFrameFormat" BO_ 74 14;
BA_ "GenMsgCycleTime" BO_ 1535 1000;
BA_ "VFrameFormat" BO_ 1535 14;
BA_ "GenMsgCycleTime" BO_ 1811 1000;
BA_ "VFrameFormat" BO_ 1811 14;
BA_ "GenMsgCycleTime" BO_ 947 250;
BA_ "VFrameFormat" BO_ 947 14;
BA_ "GenMsgCycleTime" BO_ 1812 1000;
BA_ "VFrameFormat" BO_ 1812 14;
BA_ "GenMsgCycleTime" BO_ 1253 1000;
BA_ "VFrameFormat" BO_ 1253 14;
BA_ "GenMsgCycleTime" BO_ 1813 1000;
BA_ "VFrameFormat" BO_ 1813 14;
BA_ "GenMsgCycleTime" BO_ 1252 1000;
BA_ "VFrameFormat" BO_ 1252 14;
BA_ "GenMsgCycleTime" BO_ 957 250;
BA_ "VFrameFormat" BO_ 957 14;
BA_ "GenMsgCycleTime" BO_ 116 12.5;
BA_ "VFrameFormat" BO_ 116 14;
BA_ "GenMsgCycleTime" BO_ 958 250;
BA_ "VFrameFormat" BO_ 958 14;
BA_ "GenMsgCycleTime" BO_ 1814 1000;
BA_ "VFrameFormat" BO_ 1814 14;
BA_ "GenMsgCycleTime" BO_ 1815 1000;
BA_ "VFrameFormat" BO_ 1815 14;
BA_ "GenMsgCycleTime" BO_ 1250 1000;
BA_ "VFrameFormat" BO_ 1250 14;
BA_ "GenMsgCycleTime" BO_ 659 100;
BA_ "VFrameFormat" BO_ 659 14;
BA_ "GenMsgCycleTime" BO_ 1249 1000;
BA_ "VFrameFormat" BO_ 1249 14;
BA_ "GenMsgCycleTime" BO_ 961 500;
BA_ "VFrameFormat" BO_ 961 14;
BA_ "GenMsgCycleTime" BO_ 1817 1000;
BA_ "VFrameFormat" BO_ 1817 14;
BA_ "GenMsgCycleTime" BO_ 31 12.5;
BA_ "VFrameFormat" BO_ 31 14;
BA_ "GenMsgCycleTime" BO_ 1248 1000;
BA_ "VFrameFormat" BO_ 1248 14;
BA_ "GenMsgCycleTime" BO_ 960 250;
BA_ "VFrameFormat" BO_ 960 14;
BA_ "GenMsgCycleTime" BO_ 117 12.5;
BA_ "VFrameFormat" BO_ 117 14;
BA_ "GenMsgCycleTime" BO_ 1818 1000;
BA_ "VFrameFormat" BO_ 1818 14;
BA_ "GenMsgCycleTime" BO_ 1247 1000;
BA_ "VFrameFormat" BO_ 1247 14;
BA_ "GenMsgCycleTime" BO_ 661 100;
BA_ "VFrameFormat" BO_ 661 14;
BA_ "GenMsgCycleTime" BO_ 1819 1000;
BA_ "VFrameFormat" BO_ 1819 14;
BA_ "GenMsgCycleTime" BO_ 176 25;
BA_ "VFrameFormat" BO_ 176 14;
BA_ "GenMsgCycleTime" BO_ 536 25;
BA_ "VFrameFormat" BO_ 536 14;
BA_ "GenMsgCycleTime" BO_ 1246 1000;
BA_ "VFrameFormat" BO_ 1246 14;
BA_ "GenMsgCycleTime" BO_ 959 250;
BA_ "VFrameFormat" BO_ 959 14;
BA_ "GenMsgCycleTime" BO_ 73 12.5;
BA_ "VFrameFormat" BO_ 73 14;
BA_ "GenMsgCycleTime" BO_ 1821 1000;
BA_ "VFrameFormat" BO_ 1821 14;
BA_ "GenMsgCycleTime" BO_ 738 100;
BA_ "VFrameFormat" BO_ 738 14;
BA_ "GenMsgCycleTime" BO_ 1245 1000;
BA_ "VFrameFormat" BO_ 1245 14;
BA_ "GenMsgCycleTime" BO_ 1244 1000;
BA_ "VFrameFormat" BO_ 1244 14;
BA_ "GenMsgCycleTime" BO_ 1822 1000;
BA_ "VFrameFormat" BO_ 1822 14;
BA_ "GenMsgCycleTime" BO_ 175 25;
BA_ "VFrameFormat" BO_ 175 14;
BA_ "GenMsgCycleTime" BO_ 537 25;
BA_ "VFrameFormat" BO_ 537 14;
BA_ "GenMsgCycleTime" BO_ 30 12.5;
BA_ "VFrameFormat" BO_ 30 14;
BA_ "GenMsgCycleTime" BO_ 1243 1000;
BA_ "VFrameFormat" BO_ 1243 14;
BA_ "GenMsgCycleTime" BO_ 174 25;
BA_ "VFrameFormat" BO_ 174 14;
BA_ "GenMsgCycleTime" BO_ 965 250;
BA_ "VFrameFormat" BO_ 965 14;
BA_ "GenMsgCycleTime" BO_ 1449 1000;
BA_ "VFrameFormat" BO_ 1449 14;
BA_ "GenMsgCycleTime" BO_ 1450 1000;
BA_ "VFrameFormat" BO_ 1450 14;
BA_ "GenMsgCycleTime" BO_ 1024 1000;
BA_ "VFrameFormat" BO_ 1024 14;
BA_ "GenMsgCycleTime" BO_ 768 250;
BA_ "VFrameFormat" BO_ 768 14;
BA_ "GenMsgCycleTime" BO_ 16 12.5;
BA_ "VFrameFormat" BO_ 16 14;
BA_ "GenMsgCycleTime" BO_ 17 12.5;
BA_ "VFrameFormat" BO_ 17 14;
BA_ "GenMsgCycleTime" BO_ 18 12.5;
BA_ "VFrameFormat" BO_ 18 14;
BA_ "SignalType" SG_ 1484 LnchCtlWhlSlSts "ENM";
BA_ "SignalLongName" SG_ 1484 LnchCtlWhlSlSts "Launch Control Wheel Slip Status";
BA_ "SignalType" SG_ 1484 LnchCtlEngRE46ts "ENM";
BA_ "SignalLongName" SG_ 1484 LnchCtlEngRE46ts "Launch Control Engine RPM Status";
BA_ "SignalLongName" SG_ 1484 LnchCtlBrkPresVal "Launch Control Brake Pressure Value";
BA_ "SignalType" SG_ 1484 DrvModeVisScreenSts "ENM";
BA_ "SignalLongName" SG_ 1484 DrvModeVisScreenSts "Driving Mode Visualization Screen Status";
BA_ "SignalType" SG_ 1484 EngSndPerfModeReq "ENM";
BA_ "SignalLongName" SG_ 1484 EngSndPerfModeReq "Engine Sound Performance Mode Request";
BA_ "SignalLongName" SG_ 1484 LnchCtlLineLckTmrVal "Launch Control Line Lock Timer Value";
BA_ "SignalType" SG_ 1484 PerfTracMgmtMode "ENM";
BA_ "SignalLongName" SG_ 1484 PerfTracMgmtMode "Performance Traction Management Mode";
BA_ "SignalType" SG_ 1484 HillDscntCtlSysSts "ENM";
BA_ "SignalLongName" SG_ 1484 HillDscntCtlSysSts "Hill Descent Control System Status";
BA_ "SignalType" SG_ 1484 SprtModeDrvlineVisDispVal "ENM";
BA_ "SignalLongName" SG_ 1484 SprtModeDrvlineVisDispVal "Sport Mode Driveline Visualization Display Value";
BA_ "SignalType" SG_ 1484 SprtModeBrkPedVisDispVal "ENM";
BA_ "SignalLongName" SG_ 1484 SprtModeBrkPedVisDispVal "Sport Mode Brake Pedal Visualization Display Value";
BA_ "SignalType" SG_ 1484 SprtModeActvAeroVisDispVal "ENM";
BA_ "SignalLongName" SG_ 1484 SprtModeActvAeroVisDispVal "Sport Mode Active Aerodynamics Visualization Display Value";
BA_ "SignalType" SG_ 1484 SprtModeRideHghtVisDispVal "ENM";
BA_ "SignalLongName" SG_ 1484 SprtModeRideHghtVisDispVal "Sport Mode Ride Height Visualization Display Value";
BA_ "SignalType" SG_ 1484 SprtModePwrtrnVisDispVal "ENM";
BA_ "SignalLongName" SG_ 1484 SprtModePwrtrnVisDispVal "Sport Mode Powertrain Visualization Display Value";
BA_ "SignalType" SG_ 1484 SprtModeESCVisDispVal "ENM";
BA_ "SignalLongName" SG_ 1484 SprtModeESCVisDispVal "Sport Mode ESC Visualization Display Value";
BA_ "SignalType" SG_ 1484 SprtModeSpnsnVisDispVal "ENM";
BA_ "SignalLongName" SG_ 1484 SprtModeSpnsnVisDispVal "Sport Mode Suspension Visualization Display Value";
BA_ "SignalType" SG_ 1484 SprtModeSndVisDispVal "ENM";
BA_ "SignalLongName" SG_ 1484 SprtModeSndVisDispVal "Sport Mode Sound Visualization Display Value";
BA_ "SignalType" SG_ 1484 ShfToPrkBfrExtIndOn "ENM";
BA_ "SignalLongName" SG_ 1484 ShfToPrkBfrExtIndOn "Shift To Park Before Exiting Indication On";
BA_ "SignalType" SG_ 1484 HillDscntCtlVirtSwAvl "ENM";
BA_ "SignalLongName" SG_ 1484 HillDscntCtlVirtSwAvl "Hill Descent Control Virtual Switch Available";
BA_ "SignalType" SG_ 1484 WthrSnwModeStrgVisDispVal "ENM";
BA_ "SignalLongName" SG_ 1484 WthrSnwModeStrgVisDispVal "Weather Snow Mode Steering Visualization Display Value";
BA_ "SignalType" SG_ 1484 SprtModeStrgVisDispVal "ENM";
BA_ "SignalLongName" SG_ 1484 SprtModeStrgVisDispVal "Sport Mode Steering Visualization Display Value";
BA_ "SignalType" SG_ 1485 TkModeBrkPedVisDispVal "ENM";
BA_ "SignalLongName" SG_ 1485 TkModeBrkPedVisDispVal "Track Mode Brake Pedal Visualization Display Value";
BA_ "SignalType" SG_ 1485 TkModeActvAeroVisDispVal "ENM";
BA_ "SignalLongName" SG_ 1485 TkModeActvAeroVisDispVal "Track Mode Active Aerodynamics Visualization Display Value";
BA_ "SignalType" SG_ 1485 TireTrdTempSts "ENM";
BA_ "SignalLongName" SG_ 1485 TireTrdTempSts "Tire Tread Temperature Status";
BA_ "SignalType" SG_ 1485 TkModePwrtrnVisDispVal "ENM";
BA_ "SignalLongName" SG_ 1485 TkModePwrtrnVisDispVal "Track Mode Powertrain Visualization Display Value";
BA_ "SignalType" SG_ 1485 TkModeESCVisDispVal "ENM";
BA_ "SignalLongName" SG_ 1485 TkModeESCVisDispVal "Track Mode ESC Visualization Display Value";
BA_ "SignalType" SG_ 1485 TkModeDrvlineVisDispVal "ENM";
BA_ "SignalLongName" SG_ 1485 TkModeDrvlineVisDispVal "Track Mode Driveline Visualization Display Value";
BA_ "SignalType" SG_ 1485 TkModeSndVisDispVal "ENM";
BA_ "SignalLongName" SG_ 1485 TkModeSndVisDispVal "Track Mode Sound Visualization Display Value";
BA_ "SignalType" SG_ 1485 TkModeRideHghtVisDispVal "ENM";
BA_ "SignalLongName" SG_ 1485 TkModeRideHghtVisDispVal "Track Mode Ride Height Visualization Display Value";
BA_ "SignalType" SG_ 1485 TourModeActvAeroVisDispVal "ENM";
BA_ "SignalLongName" SG_ 1485 TourModeActvAeroVisDispVal "Tour Mode Active Aerodynamics Visualization Display Value";
BA_ "SignalType" SG_ 1485 TkModeStrgVisDispVal "ENM";
BA_ "SignalLongName" SG_ 1485 TkModeStrgVisDispVal "Track Mode Steering Visualization Display Value";
BA_ "SignalType" SG_ 1485 TkModeSpnsnVisDispVal "ENM";
BA_ "SignalLongName" SG_ 1485 TkModeSpnsnVisDispVal "Track Mode Suspension Visualization Display Value";
BA_ "SignalType" SG_ 1485 TourModeESCVisDispVal "ENM";
BA_ "SignalLongName" SG_ 1485 TourModeESCVisDispVal "Tour Mode ESC Visualization Display Value";
BA_ "SignalType" SG_ 1485 TourModeDrvlineVisDispVal "ENM";
BA_ "SignalLongName" SG_ 1485 TourModeDrvlineVisDispVal "Tour Mode Driveline Visualization Display Value";
BA_ "SignalType" SG_ 1485 TourModeBrkPedVisDispVal "ENM";
BA_ "SignalLongName" SG_ 1485 TourModeBrkPedVisDispVal "Tour Mode Brake Pedal Visualization Display Value";
BA_ "SignalType" SG_ 1485 TourModeRideHghtVisDispVal "ENM";
BA_ "SignalLongName" SG_ 1485 TourModeRideHghtVisDispVal "Tour Mode Ride Height Visualization Display Value";
BA_ "SignalType" SG_ 1485 TourModePwrtrnVisDispVal "ENM";
BA_ "SignalLongName" SG_ 1485 TourModePwrtrnVisDispVal "Tour Mode Powertrain Visualization Display Value";
BA_ "SignalType" SG_ 1485 TourModeStrgVisDispVal "ENM";
BA_ "SignalLongName" SG_ 1485 TourModeStrgVisDispVal "Tour Mode Steering Visualization Display Value";
BA_ "SignalType" SG_ 1485 TourModeSpnsnVisDispVal "ENM";
BA_ "SignalLongName" SG_ 1485 TourModeSpnsnVisDispVal "Tour Mode Suspension Visualization Display Value";
BA_ "SignalType" SG_ 1485 TourModeSndVisDispVal "ENM";
BA_ "SignalLongName" SG_ 1485 TourModeSndVisDispVal "Tour Mode Sound Visualization Display Value";
BA_ "SignalType" SG_ 1485 TrlrStbAsstActIO "ENM";
BA_ "SignalLongName" SG_ 1485 TrlrStbAsstActIO "TrailerStabilityAssistActiveIndicationOn";
BA_ "SignalType" SG_ 1485 TrcCntrlOnIO "ENM";
BA_ "SignalLongName" SG_ 1485 TrcCntrlOnIO "Traction Control On Indication On";
BA_ "SignalType" SG_ 1485 TrcCntrlOffIO "ENM";
BA_ "SignalLongName" SG_ 1485 TrcCntrlOffIO "Traction Control Off Indication On";
BA_ "SignalType" SG_ 1485 TnDrvTrCtrlOffUnvIndOn "ENM";
BA_ "SignalLongName" SG_ 1485 TnDrvTrCtrlOffUnvIndOn "Teen Driver Traction Control Off Unavailable Indication On";
BA_ "SignalType" SG_ 1485 SrBkLwBkFlDrVisMsgRqOn "ENM";
BA_ "SignalLongName" SG_ 1485 SrBkLwBkFlDrVisMsgRqOn "Service Brakes Low Brake Fluid Driver Visual Message Request On";
BA_ "SignalType" SG_ 1485 TrcStbScrConfig "ENM";
BA_ "SignalLongName" SG_ 1485 TrcStbScrConfig "Traction and Stability Screen Configuration";
BA_ "SignalLongName" SG_ 712 Sig3402 "Signal3350";
BA_ "SignalLongName" SG_ 712 Sig3651 "Signal4034";
BA_ "SignalLongName" SG_ 712 Sig2630 "Signal2636";
BA_ "SignalType" SG_ 712 Sig2631 "ENM";
BA_ "SignalLongName" SG_ 712 Sig2631 "Signal2637";
BA_ "SignalLongName" SG_ 712 Sig2643 "Signal2649";
BA_ "SignalLongName" SG_ 712 Sig3485 "Signal3343";
BA_ "SignalType" SG_ 712 Sig3403 "ENM";
BA_ "SignalLongName" SG_ 712 Sig3403 "Signal3351";
BA_ "SignalType" SG_ 712 Sig2663 "ENM";
BA_ "SignalLongName" SG_ 712 Sig2663 "Signal2669";
BA_ "SignalType" SG_ 712 Sig2619 "ENM";
BA_ "SignalLongName" SG_ 712 Sig2619 "Signal2625";
BA_ "SignalType" SG_ 712 Sig3646 "ENM";
BA_ "SignalLongName" SG_ 712 Sig3646 "Signal4029";
BA_ "SignalType" SG_ 712 Sig3486 "ENM";
BA_ "SignalLongName" SG_ 712 Sig3486 "Signal3364";
BA_ "SignalType" SG_ 712 Sig3483 "ENM";
BA_ "SignalLongName" SG_ 712 Sig3483 "Signal3341";
BA_ "SignalLongName" SG_ 731 ACRfHiSdFldPrs "Air Conditioning Refrigerant High Side Fluid Pressure";
BA_ "SignalType" SG_ 731 ACRfHiSdFldPrs_Inv "ENM";
BA_ "SignalLongName" SG_ 731 ACRfHiSdFldPrs_Inv "Air Conditioning Refrigerant High Side Fluid Pressure Invalid";
BA_ "SignalLongName" SG_ 1503 ChrgCycBatPrplDistTrvld "Charge Cycle Battery Propulsion Distance Traveled";
BA_ "SignalLongName" SG_ 1503 ChrgCycBrkRegnRng "Charge Cycle Brake Regeneration Range";
BA_ "SignalLongName" SG_ 1503 ChrgCycDrvTm "Charge Cycle Drive Time";
BA_ "SignalLongName" SG_ 1503 TgtChrgLvlMinSetVal "Target Charge Level Minimum Setting Value";
BA_ "SignalType" SG_ 1503 ChrgCordThftAlrtCstSetAval "ENM";
BA_ "SignalLongName" SG_ 1503 ChrgCordThftAlrtCstSetAval "Charge Cord Theft Alert Customization Setting Available";
BA_ "SignalType" SG_ 1503 ChrgCordThftAlrtCstCurrSetVal "ENM";
BA_ "SignalLongName" SG_ 1503 ChrgCordThftAlrtCstCurrSetVal "Charge Cord Theft Alert Customization Current Setting Value";
BA_ "SignalLongName" SG_ 1509 ChrgCycEleclEngyCnsmdRngImp1 "Charge Cycle Electrical Energy Consumed Range Impact 1";
BA_ "SignalLongName" SG_ 1509 ChrgCycEleclEngyCnsmdRngImp2 "Charge Cycle Electrical Energy Consumed Range Impact 2";
BA_ "SignalLongName" SG_ 1509 ChrgCycEleclEngyCnsmdRngImp3 "Charge Cycle Electrical Energy Consumed Range Impact 3";
BA_ "SignalType" SG_ 1509 ChrgPwrLossAlrtCstSetAval "ENM";
BA_ "SignalLongName" SG_ 1509 ChrgPwrLossAlrtCstSetAval "Charge Power Loss Alert Customization Setting Available";
BA_ "SignalType" SG_ 1509 ChrgrSysAudblIndCstCurrSetVal "ENM";
BA_ "SignalLongName" SG_ 1509 ChrgrSysAudblIndCstCurrSetVal "Charger System Audible Indication Customization Current Setting Value";
BA_ "SignalType" SG_ 1509 ChrgPwrLossAlrtCstCurrSetVal "ENM";
BA_ "SignalLongName" SG_ 1509 ChrgPwrLossAlrtCstCurrSetVal "Charge Power Loss Alert Customization Current Setting Value";
BA_ "SignalType" SG_ 1509 ChrgPortDrIndReq "ENM";
BA_ "SignalLongName" SG_ 1509 ChrgPortDrIndReq "Charge Port Door Indication Request";
BA_ "SignalLongName" SG_ 1510 ChrgCycEleclEngyCnsmdRngImpTot "Charge Cycle Electrical Energy Consumed Range Impact Total";
BA_ "SignalLongName" SG_ 1510 ChrgCycEleclEngyCnsmdRngImp4 "Charge Cycle Electrical Energy Consumed Range Impact 4";
BA_ "SignalLongName" SG_ 1510 ChrgCycEleclEngyEcon "Charge Cycle Electrical Energy Economy";
BA_ "SignalLongName" SG_ 1510 PrtblChrgCordLimRdcdChrgCurrLvl "Portable Charge Cord Limit Reduced Charge Current Level";
BA_ "SignalType" SG_ 1510 HVWrlsChrgDrvrAlgnCkReqd "ENM";
BA_ "SignalLongName" SG_ 1510 HVWrlsChrgDrvrAlgnCkReqd "High Voltage Wireless Charging Driver Alignment Check Requested";
BA_ "SignalType" SG_ 1510 HVChrgVehSysFltSts "ENM";
BA_ "SignalLongName" SG_ 1510 HVChrgVehSysFltSts "High Voltage Charging Vehicle System Fault Status";
BA_ "SignalType" SG_ 1510 InsfcntTmtoCmpltChrgIndOn "ENM";
BA_ "SignalLongName" SG_ 1510 InsfcntTmtoCmpltChrgIndOn "Insufficient Time to Complete Charge Indication On";
BA_ "SignalLongName" SG_ 1511 ChrgCycEleclEngyStat1 "Charge Cycle Electrical Energy State 1";
BA_ "SignalLongName" SG_ 1511 ChrgCycEleclEngyStat2 "Charge Cycle Electrical Energy State 2";
BA_ "SignalLongName" SG_ 1511 ChrgCycEleclEngyStat3 "Charge Cycle Electrical Energy State 3";
BA_ "SignalType" SG_ 1511 CntctrsOpnUndrTempIndOn "ENM";
BA_ "SignalLongName" SG_ 1511 CntctrsOpnUndrTempIndOn "Contactors Open Under Temperature Indication On";
BA_ "SignalType" SG_ 1511 ChrgrSysAudblIndCstSetAval "ENM";
BA_ "SignalLongName" SG_ 1511 ChrgrSysAudblIndCstSetAval "Charger System Audible Indication Customization Setting Available";
BA_ "SignalType" SG_ 1511 ChrgStsPeekInScrnActvIndOn "ENM";
BA_ "SignalLongName" SG_ 1511 ChrgStsPeekInScrnActvIndOn "Charge Status Peek In Screen Active Indication On";
BA_ "SignalLongName" SG_ 1512 ChrgCycEleclEngyStat4 "Charge Cycle Electrical Energy State 4";
BA_ "SignalLongName" SG_ 1512 ChrgDatCalcChksm "Charging Data Calculated Checksum";
BA_ "SignalLongName" SG_ 1512 PrtblChrgCordLimMaxChrgCurrLvl "Portable Charge Cord Limit Maximum Charge Current Level";
BA_ "SignalType" SG_ 1512 PrtblChrgCordLimCstSetAval "ENM";
BA_ "SignalLongName" SG_ 1512 PrtblChrgCordLimCstSetAval "Portable Charge Cord Limit Customization Setting Available";
BA_ "SignalType" SG_ 1512 OffBrdChrgStnFltDtd "ENM";
BA_ "SignalLongName" SG_ 1512 OffBrdChrgStnFltDtd "Off Board Charge Station Fault Detected";
BA_ "SignalType" SG_ 1512 NeutCstdwnCertModeActvIndOn "ENM";
BA_ "SignalLongName" SG_ 1512 NeutCstdwnCertModeActvIndOn "Neutral Coastdown Certification Mode Active Indication On";
BA_ "SignalType" SG_ 1512 LocBsdChrgCstSetAval "ENM";
BA_ "SignalLongName" SG_ 1512 LocBsdChrgCstSetAval "Location Based Charging Customization Setting Available";
BA_ "SignalType" SG_ 1512 LocBsdChrgCstCurrSetVal "ENM";
BA_ "SignalLongName" SG_ 1512 LocBsdChrgCstCurrSetVal "Location Based Charging Customization Current Setting Value";
BA_ "SignalLongName" SG_ 1513 CCEEC_EngyPct1 "Charge Cycle Electrical Energy Consumed : Energy Percent 1";
BA_ "SignalLongName" SG_ 1513 CCEEC_EngyPct2 "Charge Cycle Electrical Energy Consumed : Energy Percent 2";
BA_ "SignalLongName" SG_ 1513 CCEEC_EngyPct3 "Charge Cycle Electrical Energy Consumed : Energy Percent 3";
BA_ "SignalLongName" SG_ 1513 CCEEC_EngyPct4 "Charge Cycle Electrical Energy Consumed : Energy Percent 4";
BA_ "SignalLongName" SG_ 1513 DCEEC_EngyPct1 "Drive Cycle Electrical Energy Consumed : Energy Percent 1";
BA_ "SignalLongName" SG_ 1513 DCEEC_EngyPct2 "Drive Cycle Electrical Energy Consumed : Energy Percent 2";
BA_ "SignalLongName" SG_ 1513 DCEEC_EngyPct3 "Drive Cycle Electrical Energy Consumed : Energy Percent 3";
BA_ "SignalLongName" SG_ 1513 DCEEC_EngyPct4 "Drive Cycle Electrical Energy Consumed : Energy Percent 4";
BA_ "SignalLongName" SG_ 1514 RtdEleclEngyEcon "Rated Electrical Energy Economy";
BA_ "SignalType" SG_ 1514 LBCPSS_PstnUpdtLoc "ENM";
BA_ "SignalLongName" SG_ 1514 LBCPSS_PstnUpdtLoc "Location Based Charging Position Storage Status : Position Update Location";
BA_ "SignalType" SG_ 1514 LBCCDRR_PstnNumResp "ENM";
BA_ "SignalLongName" SG_ 1514 LBCCDRR_PstnNumResp "Location Based Charging Customer Data Reset Response : Position Number Response";
BA_ "SignalType" SG_ 1514 LBCCDRR_ClrStrdPstnResp "ENM";
BA_ "SignalLongName" SG_ 1514 LBCCDRR_ClrStrdPstnResp "Location Based Charging Customer Data Reset Response : Clear Stored Position Response";
BA_ "SignalType" SG_ 1514 ServHybChrgSysIndOn "ENM";
BA_ "SignalLongName" SG_ 1514 ServHybChrgSysIndOn "Service Hybrid Charging System Indication On";
BA_ "SignalType" SG_ 1514 LBCCF_Loc4PstnStrdIndOn "ENM";
BA_ "SignalLongName" SG_ 1514 LBCCF_Loc4PstnStrdIndOn "Location Based Charging Customer Feedback : Location 4 Position Stored Indication On";
BA_ "SignalType" SG_ 1514 LBCCF_Loc3PstnStrdIndOn "ENM";
BA_ "SignalLongName" SG_ 1514 LBCCF_Loc3PstnStrdIndOn "Location Based Charging Customer Feedback : Location 3 Position Stored Indication On";
BA_ "SignalType" SG_ 1514 LBCCF_Loc2PstnStrdIndOn "ENM";
BA_ "SignalLongName" SG_ 1514 LBCCF_Loc2PstnStrdIndOn "Location Based Charging Customer Feedback : Location 2 Position Stored Indication On";
BA_ "SignalType" SG_ 1514 LBCCF_Loc1PstnStrdIndOn "ENM";
BA_ "SignalLongName" SG_ 1514 LBCCF_Loc1PstnStrdIndOn "Location Based Charging Customer Feedback : Location 1 Position Stored Indication On";
BA_ "SignalType" SG_ 1514 LBCPSS_PstnUpdtSts "ENM";
BA_ "SignalLongName" SG_ 1514 LBCPSS_PstnUpdtSts "Location Based Charging Position Storage Status : Position Update Status";
BA_ "SignalLongName" SG_ 1515 TAI_DistTrvld "Trip A Information : Distance Traveled";
BA_ "SignalLongName" SG_ 1515 TAI_EleclEngy "Trip A Information : Electrical Energy";
BA_ "SignalLongName" SG_ 1515 TAI_EleclEngyEcon "Trip A Information : Electrical Energy Economy";
BA_ "SignalType" SG_ 1515 VehLocSts "ENM";
BA_ "SignalLongName" SG_ 1515 VehLocSts "Vehicle Location Status";
BA_ "SignalType" SG_ 1515 VehLocSts_Inv "ENM";
BA_ "SignalLongName" SG_ 1515 VehLocSts_Inv "Vehicle Location Status Invalid";
BA_ "SignalLongName" SG_ 1516 TODCSR_ChrgSchedHrOfDyResp "Time of Day Charging Setting Response : Charge Schedule Hour of Day Response";
BA_ "SignalType" SG_ 1516 TODCSR_ChrgSchedDyOfWkResp "ENM";
BA_ "SignalLongName" SG_ 1516 TODCSR_ChrgSchedDyOfWkResp "Time of Day Charging Setting Response : Charge Schedule Day of Week Response";
BA_ "SignalType" SG_ 1516 TODCSR_ChrgSchedCstSetVal "ENM";
BA_ "SignalLongName" SG_ 1516 TODCSR_ChrgSchedCstSetVal "Time of Day Charging Setting Response : Charge Schedule Customization Setting Value";
BA_ "SignalLongName" SG_ 1516 TODCSR_ChrgSchedMinOfHrResp "Time of Day Charging Setting Response : Charge Schedule Minute of Hour Response";
BA_ "SignalLongName" SG_ 1516 TODCSR_ERSPrdHrOfDyResp "Time of Day Charging Setting Response : Electric Rate Schedule Period Hour of Day Response";
BA_ "SignalType" SG_ 1516 TODCSR_ERSPrdDyResp "ENM";
BA_ "SignalLongName" SG_ 1516 TODCSR_ERSPrdDyResp "Time of Day Charging Setting Response : Electric Rate Schedule Period Day Response";
BA_ "SignalType" SG_ 1516 TODCSR_ERSCstSetVal "ENM";
BA_ "SignalLongName" SG_ 1516 TODCSR_ERSCstSetVal "Time of Day Charging Setting Response : Electric Rate Schedule Customization Setting Value";
BA_ "SignalLongName" SG_ 1516 TODCSR_ERSPrdMinOfHrResp "Time of Day Charging Setting Response : Electric Rate Schedule Period Minute of Hour Response";
BA_ "SignalType" SG_ 1516 TODCSR_ERSPrdLvlResp "ENM";
BA_ "SignalLongName" SG_ 1516 TODCSR_ERSPrdLvlResp "Time of Day Charging Setting Response : Electric Rate Schedule Period Level Response";
BA_ "SignalType" SG_ 1516 PrtblChrgCordLimCstSetResp "ENM";
BA_ "SignalLongName" SG_ 1516 PrtblChrgCordLimCstSetResp "Time of Day Charging Setting Response : Portable Charge Cord Limit Customization Setting Response";
BA_ "SignalType" SG_ 1516 TODCSR_ERSPrfResp "ENM";
BA_ "SignalLongName" SG_ 1516 TODCSR_ERSPrfResp "Time of Day Charging Setting Response : Electric Rate Schedule Preference Response";
BA_ "SignalType" SG_ 1516 TODCCbnPrcndtngSetResp "ENM";
BA_ "SignalLongName" SG_ 1516 TODCCbnPrcndtngSetResp "Time of Day Charging Setting Response : Time of Day Charging Cabin Preconditioning Setting Response";
BA_ "SignalType" SG_ 1516 TODCSR_LocNumResp "ENM";
BA_ "SignalLongName" SG_ 1516 TODCSR_LocNumResp "Time of Day Charging Setting Response : Location Number Response";
BA_ "SignalType" SG_ 1516 TODCSR_LocChrgPwrLvlResp "ENM";
BA_ "SignalLongName" SG_ 1516 TODCSR_LocChrgPwrLvlResp "Time of Day Charging Setting Response : Location Charging Power Level Response";
BA_ "SignalType" SG_ 1516 UtlChrgIntfrIndOn "ENM";
BA_ "SignalLongName" SG_ 1516 UtlChrgIntfrIndOn "Utility Charging Interference Indication On";
BA_ "SignalLongName" SG_ 1516 TODCSR_TgtChrgLvlResp "Time of Day Charging Setting Response : Target Charge Level Response";
BA_ "SignalLongName" SG_ 1517 TODCNP_DprtrHrOfDy "Time of Day Charging Next Planned : Departure Hour of Day";
BA_ "SignalType" SG_ 1517 TODCNP_DprtrDyOfWk "ENM";
BA_ "SignalLongName" SG_ 1517 TODCNP_DprtrDyOfWk "Time of Day Charging Next Planned : Departure Day of Week";
BA_ "SignalType" SG_ 1517 TODCNP_Chrg "ENM";
BA_ "SignalLongName" SG_ 1517 TODCNP_Chrg "Time of Day Charging Next Planned : Charge";
BA_ "SignalLongName" SG_ 1517 TODCNP_DprtrMinOfHr "Time of Day Charging Next Planned : Departure Minute of Hour";
BA_ "SignalLongName" SG_ 1517 TODCNP_TgtChrgLvl "Time of Day Charging Next Planned : Target Charge Level";
BA_ "SignalType" SG_ 1517 TODCNP_PCCLCstCurrSetVal "ENM";
BA_ "SignalLongName" SG_ 1517 TODCNP_PCCLCstCurrSetVal "Time of Day Charging Next Planned : Portable Charge Cord Limit Customization Current Setting Value";
BA_ "SignalLongName" SG_ 1517 RngGaindThisChrg "Range Gained This Charge";
BA_ "SignalLongName" SG_ 1517 RngPerHrGaindThisChrg "Range Per Hour Gained This Charge";
BA_ "SignalLongName" SG_ 1517 TgtChrgLvlStopChrgSetVal "Target Charge Level Stop Charging Setting Value";
BA_ "SignalType" SG_ 1517 TmOfDyChrgInvHMIEntIndReqd "ENM";
BA_ "SignalLongName" SG_ 1517 TmOfDyChrgInvHMIEntIndReqd "Time of Day Charging Invalid HMI Entry Indication Requested";
BA_ "SignalType" SG_ 1517 PrtblChrgCordLimSetExpIndOn "ENM";
BA_ "SignalLongName" SG_ 1517 PrtblChrgCordLimSetExpIndOn "Portable Charge Cord Limit Setting Expiration Indication On";
BA_ "SignalType" SG_ 1517 RngPerHrGaindThisChrg_DuD "ENM";
BA_ "SignalLongName" SG_ 1517 RngPerHrGaindThisChrg_DuD "Range Per Hour Gained This Charge Don't Use Data";
BA_ "SignalType" SG_ 1517 RngGaindThisChrg_DuD "ENM";
BA_ "SignalLongName" SG_ 1517 RngGaindThisChrg_DuD "Range Gained This Charge Don't Use Data";
BA_ "SignalType" SG_ 1517 TODCNextPlndCbnPrcndtngSetResp "ENM";
BA_ "SignalLongName" SG_ 1517 TODCNextPlndCbnPrcndtngSetResp "Time of Day Charging Next Planned : Time of Day Charging Next Planned Cabin Preconditioning Setting Response";
BA_ "SignalLongName" SG_ 1518 LifetmBatPrplDistTrvld "Lifetime Battery Propulsion Distance Traveled";
BA_ "SignalLongName" SG_ 1518 DrvCycBrkRegnRng "Drive Cycle Brake Regeneration Range";
BA_ "SignalLongName" SG_ 1518 DrvCycDrvTm "Drive Cycle Drive Time";
BA_ "SignalLongName" SG_ 1519 LifetmEleclEngyUsd "Lifetime Electrical Energy Used";
BA_ "SignalLongName" SG_ 1519 LifetmWallEngyUsd "Lifetime Wall Energy Used";
BA_ "SignalLongName" SG_ 1519 HiVltgBatBulkSOC "High Voltage Battery Bulk State of Charge";
BA_ "SignalType" SG_ 1519 EngyEconMeasUnt "ENM";
BA_ "SignalLongName" SG_ 1519 EngyEconMeasUnt "Energy Economy Measurement Unit";
BA_ "SignalLongName" SG_ 1520 DrvCycEleclEngyStat4 "Drive Cycle Electrical Energy State 4";
BA_ "SignalLongName" SG_ 1520 ECHG_CurrEcon "Energy Consumption History Graph : Current Economy";
BA_ "SignalType" SG_ 1520 ECHG_CurrEconRdy "ENM";
BA_ "SignalLongName" SG_ 1520 ECHG_CurrEconRdy "Energy Consumption History Graph : Current Economy Ready";
BA_ "SignalLongName" SG_ 1520 DrvCycEleclEngyUsd "Drive Cycle Electrical Energy Used";
BA_ "SignalType" SG_ 1520 HiVltgChrgAbrtRsn "ENM";
BA_ "SignalLongName" SG_ 1520 HiVltgChrgAbrtRsn "High Voltage Charge Abort Reason";
BA_ "SignalType" SG_ 1520 HiVltgChrgSysSplyFltIndOn "ENM";
BA_ "SignalLongName" SG_ 1520 HiVltgChrgSysSplyFltIndOn "High Voltage Charging System Supply Fault Indication On";
BA_ "SignalType" SG_ 1520 HiVltgBatStopChrgBtnVsbl "ENM";
BA_ "SignalLongName" SG_ 1520 HiVltgBatStopChrgBtnVsbl "High Voltage Battery Stop Charging Button Visible";
BA_ "SignalType" SG_ 1520 HiVltgBatChrgCordCnctdIndOn "ENM";
BA_ "SignalLongName" SG_ 1520 HiVltgBatChrgCordCnctdIndOn "High Voltage Battery Charge Cord Connected Indication On";
BA_ "SignalType" SG_ 1520 HiVltgBatBulkChrgCmplt "ENM";
BA_ "SignalLongName" SG_ 1520 HiVltgBatBulkChrgCmplt "High Voltage Battery Bulk Charge Complete";
BA_ "SignalType" SG_ 1520 ElecPrplMtrOvrSpdIndOn "ENM";
BA_ "SignalLongName" SG_ 1520 ElecPrplMtrOvrSpdIndOn "Electric Propulsion Motor Over Speed Indication On";
BA_ "SignalType" SG_ 1520 HiVltgChrgInhbRsn "ENM";
BA_ "SignalLongName" SG_ 1520 HiVltgChrgInhbRsn "High Voltage Charge Inhibit Reason";
BA_ "SignalType" SG_ 1520 DrvCycEleclEngyUsd_DuD "ENM";
BA_ "SignalLongName" SG_ 1520 DrvCycEleclEngyUsd_DuD "Drive Cycle Electrical Energy Used Don't Use Data";
BA_ "SignalLongName" SG_ 1521 HiVltgBatPrplRng "High Voltage Battery Propulsion Range";
BA_ "SignalLongName" SG_ 1521 HiVltgBatPrplRngPrjtd "High Voltage Battery Propulsion Range Projected";
BA_ "SignalType" SG_ 1521 HiVltgBatPrplRng_Inv "ENM";
BA_ "SignalLongName" SG_ 1521 HiVltgBatPrplRng_Inv "High Voltage Battery Propulsion Range Invalid";
BA_ "SignalType" SG_ 1521 HiVltgBatPrplRng_DuD "ENM";
BA_ "SignalLongName" SG_ 1521 HiVltgBatPrplRng_DuD "High Voltage Battery Propulsion Range Don't Use Data";
BA_ "SignalLongName" SG_ 1521 HiVltgBatRmnUsblEngy "High Voltage Battery Remaining Usable Energy";
BA_ "SignalType" SG_ 1521 HiVltgBatRmnUsblEngy_Inv "ENM";
BA_ "SignalLongName" SG_ 1521 HiVltgBatRmnUsblEngy_Inv "High Voltage Battery Remaining Usable Energy Invalid";
BA_ "SignalType" SG_ 1521 HiVltgBatRmnUsblEngy_DuD "ENM";
BA_ "SignalLongName" SG_ 1521 HiVltgBatRmnUsblEngy_DuD "High Voltage Battery Remaining Usable Energy Don't Use Data";
BA_ "SignalLongName" SG_ 1522 DrvCycEleclEngyCnsmdRngImp1 "Drive Cycle Electrical Energy Consumed Range Impact 1";
BA_ "SignalLongName" SG_ 1522 DrvCycEleclEngyCnsmdRngImp2 "Drive Cycle Electrical Energy Consumed Range Impact 2";
BA_ "SignalLongName" SG_ 1522 DrvCycEleclEngyCnsmdRngImp3 "Drive Cycle Electrical Energy Consumed Range Impact 3";
BA_ "SignalLongName" SG_ 1522 DrvCycEleclEngyCnsmdRngImp4 "Drive Cycle Electrical Energy Consumed Range Impact 4";
BA_ "SignalType" SG_ 1522 DispHiVltgBatChrgCmpltInfo "ENM";
BA_ "SignalLongName" SG_ 1522 DispHiVltgBatChrgCmpltInfo "Display High Voltage Battery Charging Complete Information";
BA_ "SignalLongName" SG_ 1523 DrvCycEleclEngyCnsmdRngImpTot "Drive Cycle Electrical Energy Consumed Range Impact Total";
BA_ "SignalLongName" SG_ 1523 DrvCycEleclEngyStat1 "Drive Cycle Electrical Energy State 1";
BA_ "SignalLongName" SG_ 1523 DrvCycEleclEngyEcon "Drive Cycle Electrical Energy Economy";
BA_ "SignalLongName" SG_ 1523 DrvCycBatPrplDistTrvld "Drive Cycle Battery Propulsion Distance Traveled";
BA_ "SignalLongName" SG_ 1524 DrvCycEleclEngyStat2 "Drive Cycle Electrical Energy State 2";
BA_ "SignalLongName" SG_ 1524 DrvCycEleclEngyStat3 "Drive Cycle Electrical Energy State 3";
BA_ "SignalLongName" SG_ 1524 HiVltgBatTotUsblEngy "High Voltage Battery Total Usable Energy";
BA_ "SignalLongName" SG_ 1524 ElecRateSchedSsnStrtDyResp "Electric Rate Season Settings Response : Electric Rate Schedule Season Start Day Response";
BA_ "SignalType" SG_ 1524 ElecRateSchedSsnResp "ENM";
BA_ "SignalLongName" SG_ 1524 ElecRateSchedSsnResp "Electric Rate Season Settings Response : Electric Rate Schedule Season Response";
BA_ "SignalType" SG_ 1524 HiVltgBatTotUsblEngy_Inv "ENM";
BA_ "SignalLongName" SG_ 1524 HiVltgBatTotUsblEngy_Inv "High Voltage Battery Total Usable Energy Invalid";
BA_ "SignalType" SG_ 1524 HiVltgBatTotUsblEngy_DuD "ENM";
BA_ "SignalLongName" SG_ 1524 HiVltgBatTotUsblEngy_DuD "High Voltage Battery Total Usable Energy Don't Use Data";
BA_ "SignalType" SG_ 1524 ElecRateSchedSsnStrtMthResp "ENM";
BA_ "SignalLongName" SG_ 1524 ElecRateSchedSsnStrtMthResp "Electric Rate Season Settings Response : Electric Rate Schedule Season Start Month Response";
BA_ "SignalLongName" SG_ 1525 TBI_DistTrvld "Trip B Information : Distance Traveled";
BA_ "SignalLongName" SG_ 1525 TBI_EleclEngy "Trip B Information : Electrical Energy";
BA_ "SignalLongName" SG_ 1525 TBI_EleclEngyEcon "Trip B Information : Electrical Energy Economy";
BA_ "SignalLongName" SG_ 736 LIB1PackExtrnVltg "Lithium Ion Battery 1 Pack External Voltage";
BA_ "SignalLongName" SG_ 736 LIB1AvgTemp "Lithium Ion Battery 1 Average Temperature";
BA_ "SignalType" SG_ 736 LIB1PackExtrnVltg_Inv "ENM";
BA_ "SignalLongName" SG_ 736 LIB1PackExtrnVltg_Inv "Lithium Ion Battery 1 Pack External Voltage Invalid";
BA_ "SignalType" SG_ 736 LIB1PackExtrnVltg_DuD "ENM";
BA_ "SignalLongName" SG_ 736 LIB1PackExtrnVltg_DuD "Lithium Ion Battery 1 Pack External Voltage Don't Use Data";
BA_ "SignalLongName" SG_ 736 LIB1MaxTemp "Lithium Ion Battery 1 Maximum Temperature";
BA_ "SignalType" SG_ 736 LIB1AvgTemp_Inv "ENM";
BA_ "SignalLongName" SG_ 736 LIB1AvgTemp_Inv "Lithium Ion Battery 1 Average Temperature Invalid";
BA_ "SignalType" SG_ 736 LIB1AvgTemp_DuD "ENM";
BA_ "SignalLongName" SG_ 736 LIB1AvgTemp_DuD "Lithium Ion Battery 1 Average Temperature Don't Use Data";
BA_ "SignalType" SG_ 736 LIB1MaxTemp_DuD "ENM";
BA_ "SignalLongName" SG_ 736 LIB1MaxTemp_DuD "Lithium Ion Battery 1 Maximum Temperature Don't Use Data";
BA_ "SignalLongName" SG_ 736 LIB1MinTemp "Lithium Ion Battery 1 Minimum Temperature";
BA_ "SignalType" SG_ 736 LIB1MaxTemp_Inv "ENM";
BA_ "SignalLongName" SG_ 736 LIB1MaxTemp_Inv "Lithium Ion Battery 1 Maximum Temperature Invalid";
BA_ "SignalLongName" SG_ 736 LIB1StatOfChrg "Lithium Ion Battery 1 State Of Charge";
BA_ "SignalType" SG_ 736 LIB1MinTemp_Inv "ENM";
BA_ "SignalLongName" SG_ 736 LIB1MinTemp_Inv "Lithium Ion Battery 1 Minimum Temperature Invalid";
BA_ "SignalType" SG_ 736 LIB1MinTemp_DuD "ENM";
BA_ "SignalLongName" SG_ 736 LIB1MinTemp_DuD "Lithium Ion Battery 1 Minimum Temperature Don't Use Data";
BA_ "SignalType" SG_ 736 LIB1CellBalFlt_DuD "ENM";
BA_ "SignalLongName" SG_ 736 LIB1CellBalFlt_DuD "Lithium Ion Battery 1 Cell Balancing Fault Don't Use Data";
BA_ "SignalType" SG_ 736 LIB1CellBalFlt "ENM";
BA_ "SignalLongName" SG_ 736 LIB1CellBalFlt "Lithium Ion Battery 1 Cell Balancing Fault";
BA_ "SignalType" SG_ 736 LIB1StatOfChrg_Inv "ENM";
BA_ "SignalLongName" SG_ 736 LIB1StatOfChrg_Inv "Lithium Ion Battery 1 State Of Charge Invalid";
BA_ "SignalType" SG_ 736 LIB1StatOfChrg_DuD "ENM";
BA_ "SignalLongName" SG_ 736 LIB1StatOfChrg_DuD "Lithium Ion Battery 1 State Of Charge Don't Use Data";
BA_ "SignalType" SG_ 736 LIB1CellVltgFlt_Inv "ENM";
BA_ "SignalLongName" SG_ 736 LIB1CellVltgFlt_Inv "Lithium Ion Battery 1 Cell Voltage Fault Invalid";
BA_ "SignalType" SG_ 736 LIB1CellVltgFlt_DuD "ENM";
BA_ "SignalLongName" SG_ 736 LIB1CellVltgFlt_DuD "Lithium Ion Battery 1 Cell Voltage Fault Don't Use Data";
BA_ "SignalType" SG_ 736 LIB1CellVltgFlt "ENM";
BA_ "SignalLongName" SG_ 736 LIB1CellVltgFlt "Lithium Ion Battery 1 Cell Voltage Fault";
BA_ "SignalType" SG_ 736 LIB1CellBalFlt_Inv "ENM";
BA_ "SignalLongName" SG_ 736 LIB1CellBalFlt_Inv "Lithium Ion Battery 1 Cell Balancing Fault Invalid";
BA_ "SignalLongName" SG_ 949 ACCTOSHiThrtLicVehTmToClsn1 "Adaptive Cruise Control Target Object Selection High Threat Licensable Vehicle Time to Collision 1";
BA_ "SignalLongName" SG_ 949 ACCTOSHiThrtLicVehTmToClsn10 "Adaptive Cruise Control Target Object Selection High Threat Licensable Vehicle Time to Collision 10";
BA_ "SignalLongName" SG_ 949 ACCTOSHiThrtLicVehTmToClsn2 "Adaptive Cruise Control Target Object Selection High Threat Licensable Vehicle Time to Collision 2";
BA_ "SignalLongName" SG_ 949 ACCTOSHiThrtLicVehTmToClsn3 "Adaptive Cruise Control Target Object Selection High Threat Licensable Vehicle Time to Collision 3";
BA_ "SignalLongName" SG_ 950 ACCTOSHiThrtLicVehTmToClsn4 "Adaptive Cruise Control Target Object Selection High Threat Licensable Vehicle Time to Collision 4";
BA_ "SignalLongName" SG_ 950 ACCTOSHiThrtLicVehTmToClsn5 "Adaptive Cruise Control Target Object Selection High Threat Licensable Vehicle Time to Collision 5";
BA_ "SignalLongName" SG_ 950 ACCTOSHiThrtLicVehTmToClsn6 "Adaptive Cruise Control Target Object Selection High Threat Licensable Vehicle Time to Collision 6";
BA_ "SignalLongName" SG_ 950 ACCTOSHiThrtLicVehTmToClsn7 "Adaptive Cruise Control Target Object Selection High Threat Licensable Vehicle Time to Collision 7";
BA_ "SignalLongName" SG_ 951 ACCTOSHiThrtLicVehTmToClsn8 "Adaptive Cruise Control Target Object Selection High Threat Licensable Vehicle Time to Collision 8";
BA_ "SignalLongName" SG_ 951 ACCTOSHiThrtLicVehTmToClsn9 "Adaptive Cruise Control Target Object Selection High Threat Licensable Vehicle Time to Collision 9";
BA_ "SignalLongName" SG_ 951 LnFllwgTOSHiThrtLicVehLngDist1 "Lane Following Target Object Selection High Threat Licensable Vehicle Longitudinal Distance 1";
BA_ "SignalLongName" SG_ 951 LnFllwgTOSHiThrtLicVehLngDist2 "Lane Following Target Object Selection High Threat Licensable Vehicle Longitudinal Distance 2";
BA_ "SignalLongName" SG_ 952 LnFllwgTOSHiThrtLicVehLngDist3 "Lane Following Target Object Selection High Threat Licensable Vehicle Longitudinal Distance 3";
BA_ "SignalLongName" SG_ 952 LnFllwgTOSHiThrtLicVehLngDist4 "Lane Following Target Object Selection High Threat Licensable Vehicle Longitudinal Distance 4";
BA_ "SignalLongName" SG_ 952 LnFllwgTOSHiThrtLicVehLngDist5 "Lane Following Target Object Selection High Threat Licensable Vehicle Longitudinal Distance 5";
BA_ "SignalLongName" SG_ 952 LnFllwgTOSHiThrtLicVehLngDist6 "Lane Following Target Object Selection High Threat Licensable Vehicle Longitudinal Distance 6";
BA_ "SignalType" SG_ 952 StrgWhlTchSnsHndsOnStat "ENM";
BA_ "SignalLongName" SG_ 952 StrgWhlTchSnsHndsOnStat "Steering Wheel Touch Sense Hands On State";
BA_ "SignalLongName" SG_ 1417 ACCDrSlctdSpd "Adaptive Cruise Control Information 1 : Adaptive Cruise Control Driver Selected Speed";
BA_ "SignalType" SG_ 1417 ACCAutoStSpStat "ENM";
BA_ "SignalLongName" SG_ 1417 ACCAutoStSpStat "Adaptive Cruise Control Information 1 : Adaptive Cruise Control Auto Set Speed Status";
BA_ "SignalType" SG_ 1417 ACCSpdLimSgnUnt "ENM";
BA_ "SignalLongName" SG_ 1417 ACCSpdLimSgnUnt "Adaptive Cruise Control Information 1 : Adaptive Cruise Control Speed Limit Sign Unit";
BA_ "SignalType" SG_ 1417 ACCDrSlctdSpdIndOn "ENM";
BA_ "SignalLongName" SG_ 1417 ACCDrSlctdSpdIndOn "Adaptive Cruise Control Information 1 : Adaptive Cruise Control Driver Selected Speed Indication On";
BA_ "SignalLongName" SG_ 1417 ACCSpdLimSgnVal "Adaptive Cruise Control Information 1 : Adaptive Cruise Control Speed Limit Sign Value";
BA_ "SignalType" SG_ 1417 FrwdImpMtgnOpSlctCstCrStVal "ENM";
BA_ "SignalLongName" SG_ 1417 FrwdImpMtgnOpSlctCstCrStVal "Forward Impact Mitigation Operation Select Customization Current Setting Value";
BA_ "SignalType" SG_ 1417 FrntPCMRspTypCstCrStVal "ENM";
BA_ "SignalLongName" SG_ 1417 FrntPCMRspTypCstCrStVal "Front Pedestrian Collision Mitigation Response Type Customization Current Setting Value";
BA_ "SignalType" SG_ 1417 ACCSysSlctdMd "ENM";
BA_ "SignalLongName" SG_ 1417 ACCSysSlctdMd "Adaptive Cruise Control Information 1 : Adaptive Cruise Control System Selected Mode";
BA_ "SignalType" SG_ 1417 FrntPCMRspTypCstAvlFlg1 "ENM";
BA_ "SignalLongName" SG_ 1417 FrntPCMRspTypCstAvlFlg1 "Front Pedestrian Collision Mitigation Response Type Customization Availability Flag 1";
BA_ "SignalType" SG_ 1417 AutoEmrgBrkgDsbldIndOn "ENM";
BA_ "SignalLongName" SG_ 1417 AutoEmrgBrkgDsbldIndOn "Automatic Emergency Braking Disabled Indication On";
BA_ "SignalType" SG_ 1417 ACCGoNtfrChmEvntSt "ENM";
BA_ "SignalLongName" SG_ 1417 ACCGoNtfrChmEvntSt "Adaptive Cruise Control Go Notifier Chime Event State";
BA_ "SignalType" SG_ 1417 AnmlWrnIndReq "ENM";
BA_ "SignalLongName" SG_ 1417 AnmlWrnIndReq "Animal Warning Indication Request";
BA_ "SignalType" SG_ 1417 FrwdVehAhdIndReq "ENM";
BA_ "SignalLongName" SG_ 1417 FrwdVehAhdIndReq "Forward Vehicle Ahead Indication Request";
BA_ "SignalType" SG_ 1417 FrtPedtrnClsnMtgnAudAttnReqd "ENM";
BA_ "SignalLongName" SG_ 1417 FrtPedtrnClsnMtgnAudAttnReqd "Front Pedestrian Collision Mitigation Audio Attenuation Requested";
BA_ "SignalType" SG_ 1417 FrntPCMRspTypCstStAvl "ENM";
BA_ "SignalLongName" SG_ 1417 FrntPCMRspTypCstStAvl "Front Pedestrian Collision Mitigation Response Type Customization Setting Available";
BA_ "SignalType" SG_ 1417 FrntPCMRspTypCstAvlFlg7 "ENM";
BA_ "SignalLongName" SG_ 1417 FrntPCMRspTypCstAvlFlg7 "Front Pedestrian Collision Mitigation Response Type Customization Availability Flag 7";
BA_ "SignalType" SG_ 1417 FrntPCMRspTypCstAvlFlg6 "ENM";
BA_ "SignalLongName" SG_ 1417 FrntPCMRspTypCstAvlFlg6 "Front Pedestrian Collision Mitigation Response Type Customization Availability Flag 6";
BA_ "SignalType" SG_ 1417 FrntPCMRspTypCstAvlFlg5 "ENM";
BA_ "SignalLongName" SG_ 1417 FrntPCMRspTypCstAvlFlg5 "Front Pedestrian Collision Mitigation Response Type Customization Availability Flag 5";
BA_ "SignalType" SG_ 1417 FrntPCMRspTypCstAvlFlg4 "ENM";
BA_ "SignalLongName" SG_ 1417 FrntPCMRspTypCstAvlFlg4 "Front Pedestrian Collision Mitigation Response Type Customization Availability Flag 4";
BA_ "SignalType" SG_ 1417 FrntPCMRspTypCstAvlFlg3 "ENM";
BA_ "SignalLongName" SG_ 1417 FrntPCMRspTypCstAvlFlg3 "Front Pedestrian Collision Mitigation Response Type Customization Availability Flag 3";
BA_ "SignalType" SG_ 1417 FrntPCMRspTypCstAvlFlg2 "ENM";
BA_ "SignalLongName" SG_ 1417 FrntPCMRspTypCstAvlFlg2 "Front Pedestrian Collision Mitigation Response Type Customization Availability Flag 2";
BA_ "SignalType" SG_ 1417 FrwdImpMtgnOpSlctCstAvlFlg7 "ENM";
BA_ "SignalLongName" SG_ 1417 FrwdImpMtgnOpSlctCstAvlFlg7 "Forward Impact Mitigation Operation Select Customization Availability Flag 7";
BA_ "SignalType" SG_ 1417 FrwdImpMtgnOpSlctCstAvlFlg6 "ENM";
BA_ "SignalLongName" SG_ 1417 FrwdImpMtgnOpSlctCstAvlFlg6 "Forward Impact Mitigation Operation Select Customization Availability Flag 6";
BA_ "SignalType" SG_ 1417 FrwdImpMtgnOpSlctCstAvlFlg5 "ENM";
BA_ "SignalLongName" SG_ 1417 FrwdImpMtgnOpSlctCstAvlFlg5 "Forward Impact Mitigation Operation Select Customization Availability Flag 5";
BA_ "SignalType" SG_ 1417 FrwdImpMtgnOpSlctCstAvlFlg4 "ENM";
BA_ "SignalLongName" SG_ 1417 FrwdImpMtgnOpSlctCstAvlFlg4 "Forward Impact Mitigation Operation Select Customization Availability Flag 4";
BA_ "SignalType" SG_ 1417 FrwdImpMtgnOpSlctCstAvlFlg3 "ENM";
BA_ "SignalLongName" SG_ 1417 FrwdImpMtgnOpSlctCstAvlFlg3 "Forward Impact Mitigation Operation Select Customization Availability Flag 3";
BA_ "SignalType" SG_ 1417 FrwdImpMtgnOpSlctCstAvlFlg2 "ENM";
BA_ "SignalLongName" SG_ 1417 FrwdImpMtgnOpSlctCstAvlFlg2 "Forward Impact Mitigation Operation Select Customization Availability Flag 2";
BA_ "SignalType" SG_ 1417 FrwdImpMtgnOpSlctCstAvlFlg1 "ENM";
BA_ "SignalLongName" SG_ 1417 FrwdImpMtgnOpSlctCstAvlFlg1 "Forward Impact Mitigation Operation Select Customization Availability Flag 1";
BA_ "SignalType" SG_ 1417 FrwdClsnAlrtImntAlrtAudAttnReqd "ENM";
BA_ "SignalLongName" SG_ 1417 FrwdClsnAlrtImntAlrtAudAttnReqd "Forward Collision Alert Imminent Alert Audio Attenuation Requested";
BA_ "SignalType" SG_ 1417 GoNotfrCstAvlFlg7 "ENM";
BA_ "SignalLongName" SG_ 1417 GoNotfrCstAvlFlg7 "Go Notifier Customization Availability Flag 7";
BA_ "SignalType" SG_ 1417 GoNotfrCstAvlFlg6 "ENM";
BA_ "SignalLongName" SG_ 1417 GoNotfrCstAvlFlg6 "Go Notifier Customization Availability Flag 6";
BA_ "SignalType" SG_ 1417 GoNotfrCstAvlFlg5 "ENM";
BA_ "SignalLongName" SG_ 1417 GoNotfrCstAvlFlg5 "Go Notifier Customization Availability Flag 5";
BA_ "SignalType" SG_ 1417 GoNotfrCstAvlFlg4 "ENM";
BA_ "SignalLongName" SG_ 1417 GoNotfrCstAvlFlg4 "Go Notifier Customization Availability Flag 4";
BA_ "SignalType" SG_ 1417 GoNotfrCstAvlFlg3 "ENM";
BA_ "SignalLongName" SG_ 1417 GoNotfrCstAvlFlg3 "Go Notifier Customization Availability Flag 3";
BA_ "SignalType" SG_ 1417 GoNotfrCstAvlFlg2 "ENM";
BA_ "SignalLongName" SG_ 1417 GoNotfrCstAvlFlg2 "Go Notifier Customization Availability Flag 2";
BA_ "SignalType" SG_ 1417 GoNotfrCstAvlFlg1 "ENM";
BA_ "SignalLongName" SG_ 1417 GoNotfrCstAvlFlg1 "Go Notifier Customization Availability Flag 1";
BA_ "SignalType" SG_ 1417 FrwdImpMtgnOpSlctCstStAvl "ENM";
BA_ "SignalLongName" SG_ 1417 FrwdImpMtgnOpSlctCstStAvl "Forward Impact Mitigation Operation Select Customization Setting Available";
BA_ "SignalType" SG_ 1259 SprTireSt "ENM";
BA_ "SignalLongName" SG_ 1259 SprTireSt "Spare Tire Status";
BA_ "SignalLongName" SG_ 40 RAI1P_RrAxlEstdTrqAuth "Serial Data 41 Protected : Rear Axle Estimated Torque Authenticated";
BA_ "SignalLongName" SG_ 40 PrplSysPriAxlLtTrqCmdAuth "Serial Data 144 Protected : Propulsion System Primary Axle Left Torque Command Authenticated";
BA_ "SignalType" SG_ 40 RAI1P_RrAxlStsAuth "ENM";
BA_ "SignalLongName" SG_ 40 RAI1P_RrAxlStsAuth "Serial Data 41 Protected : Rear Axle Status Authenticated";
BA_ "SignalType" SG_ 40 RAI1P_RrAxlEstdTrqAuth_Inv "ENM";
BA_ "SignalLongName" SG_ 40 RAI1P_RrAxlEstdTrqAuth_Inv "Serial Data 41 Protected : Rear Axle Estimated Torque Authenticated Invalid";
BA_ "SignalLongName" SG_ 40 PrplSysPriAxlRtTrqCmdAuth "Serial Data 144 Protected : Propulsion System Primary Axle Right Torque Command Authenticated";
BA_ "SignalLongName" SG_ 40 PrplSysSecAxlTrqCmdAuth "Serial Data 144 Protected : Propulsion System Secondary Axle Torque Command Authenticated";
BA_ "SignalLongName" SG_ 1465 PIMRI_WE48_RcntlyProgInd "Programming Inspection and Maintenance Readiness Indication - WE48 : Recently Programmed Indicator";
BA_ "SignalType" SG_ 1465 PIMRI_WE48_PrmntDTCInd "ENM";
BA_ "SignalLongName" SG_ 1465 PIMRI_WE48_PrmntDTCInd "Programming Inspection and Maintenance Readiness Indication - WE48 : Permanent DTC Indicator";
BA_ "SignalType" SG_ 1465 PIMRI_WE48_FltsPrsntInd "ENM";
BA_ "SignalLongName" SG_ 1465 PIMRI_WE48_FltsPrsntInd "Programming Inspection and Maintenance Readiness Indication - WE48 : Faults Present Indicator";
BA_ "SignalLongName" SG_ 1466 TirePrsLRInr "Tire Pressure Left Rear Inner Information : Tire Pressure Left Rear Inner";
BA_ "SignalLongName" SG_ 1466 TirePrsRRInr "Tire Pressure Right Rear Inner Information : Tire Pressure Right Rear Inner";
BA_ "SignalType" SG_ 1466 TirePrsStatLRInr "ENM";
BA_ "SignalLongName" SG_ 1466 TirePrsStatLRInr "Tire Pressure Left Rear Inner Information : TE46 Status Left Rear Inner";
BA_ "SignalType" SG_ 1466 TirePrsLRInr_Inv "ENM";
BA_ "SignalLongName" SG_ 1466 TirePrsLRInr_Inv "Tire Pressure Left Rear Inner Information : Tire Pressure Left Rear Inner Invalid";
BA_ "SignalType" SG_ 1466 TirePrsStatRRInr "ENM";
BA_ "SignalLongName" SG_ 1466 TirePrsStatRRInr "Tire Pressure Right Rear Inner Information : TE46 Status Right Rear Inner";
BA_ "SignalType" SG_ 1466 TirePrsRRInr_Inv "ENM";
BA_ "SignalLongName" SG_ 1466 TirePrsRRInr_Inv "Tire Pressure Right Rear Inner Information : Tire Pressure Right Rear Inner Invalid";
BA_ "SignalType" SG_ 1466 ElecRateSchedSsnStrtMthReq "ENM";
BA_ "SignalLongName" SG_ 1466 ElecRateSchedSsnStrtMthReq "Electric Rate Season Settings Request : Electric Rate Schedule Season Start Month Request";
BA_ "SignalLongName" SG_ 1466 ElecRateSchedSsnStrtDyReq "Electric Rate Season Settings Request : Electric Rate Schedule Season Start Day Request";
BA_ "SignalType" SG_ 1466 ElecRateSchedSsnReq "ENM";
BA_ "SignalLongName" SG_ 1466 ElecRateSchedSsnReq "Electric Rate Season Settings Request : Electric Rate Schedule Season Request";
BA_ "SignalLongName" SG_ 1466 CbnPrcndtngSchTempCstSetReq "Cabin Preconditioning Schedule Temperature Customization Setting Request";
BA_ "SignalType" SG_ 1466 VirtOnePedDrvReq "ENM";
BA_ "SignalLongName" SG_ 1466 VirtOnePedDrvReq "Virtual One Pedal Driving Request";
BA_ "SignalType" SG_ 1466 TlmHVDCFstChrgSoonReq "ENM";
BA_ "SignalLongName" SG_ 1466 TlmHVDCFstChrgSoonReq "Telematics High Voltage DC Fast Charge Soon Request";
BA_ "SignalType" SG_ 1466 HVDCFstChrgSoonReq "ENM";
BA_ "SignalLongName" SG_ 1466 HVDCFstChrgSoonReq "High Voltage DC Fast Charge Soon Request";
BA_ "SignalType" SG_ 1466 OnePedDrvCstChgSetReq "ENM";
BA_ "SignalLongName" SG_ 1466 OnePedDrvCstChgSetReq "One Pedal Driving Customization Change Setting Request";
BA_ "SignalType" SG_ 1466 Sig2580 "ENM";
BA_ "SignalLongName" SG_ 1466 Sig2580 "Signal2575";
BA_ "SignalType" SG_ 1466 Sig0613 "ENM";
BA_ "SignalLongName" SG_ 1466 Sig0613 "Signal0499";
BA_ "SignalType" SG_ 1466 E44MutDrvrReq "ENM";
BA_ "SignalLongName" SG_ 1466 E44MutDrvrReq "Park Assist Mute Driver Request";
BA_ "SignalType" SG_ 1466 CbnPrcndtngSchTempCstSetReqAtv "ENM";
BA_ "SignalLongName" SG_ 1466 CbnPrcndtngSchTempCstSetReqAtv "Cabin Preconditioning Schedule Temperature Customization Setting Request Active";
BA_ "SignalType" SG_ 1466 DMSIntnDrvrCstChgSetReq "ENM";
BA_ "SignalLongName" SG_ 1466 DMSIntnDrvrCstChgSetReq "Driver Monitoring System Inattentive Driver Customization Change Setting Request";
BA_ "SignalType" SG_ 1466 DMSDrwDrvrCstChgSetReq "ENM";
BA_ "SignalLongName" SG_ 1466 DMSDrwDrvrCstChgSetReq "Driver Monitoring System Drowsy Driver Customization Change Setting Request";
BA_ "SignalType" SG_ 1466 Sig3200 "ENM";
BA_ "SignalLongName" SG_ 1466 Sig3200 "Signal3209";
BA_ "SignalType" SG_ 929 VehDynsPerfModeReq "ENM";
BA_ "SignalLongName" SG_ 929 VehDynsPerfModeReq "Vehicle Dynamics Performance Mode Request";
BA_ "SignalType" SG_ 929 RrDiffPerfModeReq "ENM";
BA_ "SignalLongName" SG_ 929 RrDiffPerfModeReq "Rear Differential Performance Mode Request";
BA_ "SignalType" SG_ 1467 OnePedDrvCstSetAval "ENM";
BA_ "SignalLongName" SG_ 1467 OnePedDrvCstSetAval "One Pedal Driving Customization Setting Available";
BA_ "SignalType" SG_ 1467 OnePedDrvCstSetAllwdFlg7 "ENM";
BA_ "SignalLongName" SG_ 1467 OnePedDrvCstSetAllwdFlg7 "One Pedal Driving Customization Setting Allowed Flag 7";
BA_ "SignalType" SG_ 1467 OnePedDrvCstSetAllwdFlg6 "ENM";
BA_ "SignalLongName" SG_ 1467 OnePedDrvCstSetAllwdFlg6 "One Pedal Driving Customization Setting Allowed Flag 6";
BA_ "SignalType" SG_ 1467 OnePedDrvCstSetAllwdFlg5 "ENM";
BA_ "SignalLongName" SG_ 1467 OnePedDrvCstSetAllwdFlg5 "One Pedal Driving Customization Setting Allowed Flag 5";
BA_ "SignalType" SG_ 1467 OnePedDrvCstSetAllwdFlg4 "ENM";
BA_ "SignalLongName" SG_ 1467 OnePedDrvCstSetAllwdFlg4 "One Pedal Driving Customization Setting Allowed Flag 4";
BA_ "SignalType" SG_ 1467 OnePedDrvCstSetAllwdFlg3 "ENM";
BA_ "SignalLongName" SG_ 1467 OnePedDrvCstSetAllwdFlg3 "One Pedal Driving Customization Setting Allowed Flag 3";
BA_ "SignalType" SG_ 1467 OnePedDrvCstSetAllwdFlg2 "ENM";
BA_ "SignalLongName" SG_ 1467 OnePedDrvCstSetAllwdFlg2 "One Pedal Driving Customization Setting Allowed Flag 2";
BA_ "SignalType" SG_ 1467 OnePedDrvCstSetAllwdFlg1 "ENM";
BA_ "SignalLongName" SG_ 1467 OnePedDrvCstSetAllwdFlg1 "One Pedal Driving Customization Setting Allowed Flag 1";
BA_ "SignalType" SG_ 1467 VirtOnePedDrvCtlAval "ENM";
BA_ "SignalLongName" SG_ 1467 VirtOnePedDrvCtlAval "Virtual One Pedal Driving Control Available";
BA_ "SignalType" SG_ 1467 OnePedDrvCstSetAvlFlg7 "ENM";
BA_ "SignalLongName" SG_ 1467 OnePedDrvCstSetAvlFlg7 "One Pedal Driving Customization Setting Availability Flag 7";
BA_ "SignalType" SG_ 1467 OnePedDrvCstSetAvlFlg6 "ENM";
BA_ "SignalLongName" SG_ 1467 OnePedDrvCstSetAvlFlg6 "One Pedal Driving Customization Setting Availability Flag 6";
BA_ "SignalType" SG_ 1467 OnePedDrvCstSetAvlFlg5 "ENM";
BA_ "SignalLongName" SG_ 1467 OnePedDrvCstSetAvlFlg5 "One Pedal Driving Customization Setting Availability Flag 5";
BA_ "SignalType" SG_ 1467 OnePedDrvCstSetAvlFlg4 "ENM";
BA_ "SignalLongName" SG_ 1467 OnePedDrvCstSetAvlFlg4 "One Pedal Driving Customization Setting Availability Flag 4";
BA_ "SignalType" SG_ 1467 OnePedDrvCstSetAvlFlg3 "ENM";
BA_ "SignalLongName" SG_ 1467 OnePedDrvCstSetAvlFlg3 "One Pedal Driving Customization Setting Availability Flag 3";
BA_ "SignalType" SG_ 1467 OnePedDrvCstSetAvlFlg2 "ENM";
BA_ "SignalLongName" SG_ 1467 OnePedDrvCstSetAvlFlg2 "One Pedal Driving Customization Setting Availability Flag 2";
BA_ "SignalType" SG_ 1467 OnePedDrvCstSetAvlFlg1 "ENM";
BA_ "SignalLongName" SG_ 1467 OnePedDrvCstSetAvlFlg1 "One Pedal Driving Customization Setting Availability Flag 1";
BA_ "SignalType" SG_ 1467 VirtOnePedDrvUserCtlAllwd "ENM";
BA_ "SignalLongName" SG_ 1467 VirtOnePedDrvUserCtlAllwd "Virtual One Pedal Driving User Control Allowed";
BA_ "SignalType" SG_ 1468 OnePedDrvIndOn "ENM";
BA_ "SignalLongName" SG_ 1468 OnePedDrvIndOn "One Pedal Driving Indication On";
BA_ "SignalType" SG_ 1468 OnePedDrvWrnIndReq "ENM";
BA_ "SignalLongName" SG_ 1468 OnePedDrvWrnIndReq "One Pedal Driving Warning Indication Request";
BA_ "SignalType" SG_ 1468 OnePedDrvCurrSeltnVal "ENM";
BA_ "SignalLongName" SG_ 1468 OnePedDrvCurrSeltnVal "One Pedal Driving Current Selection Value";
BA_ "SignalType" SG_ 1468 OnePedDrvCstCurrSetVal "ENM";
BA_ "SignalLongName" SG_ 1468 OnePedDrvCstCurrSetVal "One Pedal Driving Customization Current Setting Value";
BA_ "SignalType" SG_ 931 ElecMchnAInvrtStat "ENM";
BA_ "SignalLongName" SG_ 931 ElecMchnAInvrtStat "Electric Machine A Inverter State";
BA_ "SignalLongName" SG_ 115 Sig4927 "Signal5092";
BA_ "SignalType" SG_ 115 Sig4928 "ENM";
BA_ "SignalLongName" SG_ 115 Sig4928 "Signal5093";
BA_ "SignalLongName" SG_ 194 PrplSysInvrtBDCCurrAuth "Serial Data 52 : Propulsion System Inverter B DC Current Authenticated";
BA_ "SignalType" SG_ 194 PrplSysInvrtBDCCurrAuth_Inv "ENM";
BA_ "SignalLongName" SG_ 194 PrplSysInvrtBDCCurrAuth_Inv "Serial Data 52 : Propulsion System Inverter B DC Current Authenticated Invalid";
BA_ "SignalLongName" SG_ 953 PrplSysMtrBRotrTemp "Propulsion System Motor B Rotor Temperature";
BA_ "SignalType" SG_ 953 PrplSysMtrBRotrTemp_Inv "ENM";
BA_ "SignalLongName" SG_ 953 PrplSysMtrBRotrTemp_Inv "Propulsion System Motor B Rotor Temperature Invalid";
BA_ "SignalType" SG_ 953 Sig2567 "ENM";
BA_ "SignalLongName" SG_ 953 Sig2567 "Signal2549";
BA_ "SignalLongName" SG_ 953 PrplSysMtrBSttrTemp "Propulsion System Motor B Stator Temperature";
BA_ "SignalType" SG_ 953 PrplSysMtrBSttrTemp_Inv "ENM";
BA_ "SignalLongName" SG_ 953 PrplSysMtrBSttrTemp_Inv "Propulsion System Motor B Stator Temperature Invalid";
BA_ "SignalLongName" SG_ 1471 BECM2ERDTC_CdNum "Battery Energy Control Module 2 Emissions Related DTC : Code Number";
BA_ "SignalLongName" SG_ 1471 PIMRI_VECM_RcntlyProgInd "Programming Inspection and Maintenance Readiness Indication - VECM : Recently Programmed Indicator";
BA_ "SignalType" SG_ 1471 PIMRI_VECM_PrmntDTCInd "ENM";
BA_ "SignalLongName" SG_ 1471 PIMRI_VECM_PrmntDTCInd "Programming Inspection and Maintenance Readiness Indication - VECM : Permanent DTC Indicator";
BA_ "SignalType" SG_ 1471 PIMRI_VECM_FltsPrsntInd "ENM";
BA_ "SignalLongName" SG_ 1471 PIMRI_VECM_FltsPrsntInd "Programming Inspection and Maintenance Readiness Indication - VECM : Faults Present Indicator";
BA_ "SignalType" SG_ 1471 BECM2EmsRltMlfAtv "ENM";
BA_ "SignalLongName" SG_ 1471 BECM2EmsRltMlfAtv "Battery Energy Control Module 2 Emissions Related Malfunction Active";
BA_ "SignalType" SG_ 1471 BECM2ERDTC_SysDes "ENM";
BA_ "SignalLongName" SG_ 1471 BECM2ERDTC_SysDes "Battery Energy Control Module 2 Emissions Related DTC : System Designator";
BA_ "SignalLongName" SG_ 1472 HiVltgBatPrcndtngEstdEngyToCmpt "High Voltage Battery Preconditioning Estimated Energy To Complete";
BA_ "SignalLongName" SG_ 1472 HiVltgBatDispTempLvlPct "High Voltage Battery Display Temperature Level Percent";
BA_ "SignalType" SG_ 1472 HiVltgBatDispTempLvlPct_DuD "ENM";
BA_ "SignalLongName" SG_ 1472 HiVltgBatDispTempLvlPct_DuD "High Voltage Battery Display Temperature Level Percent Don't Use Data";
BA_ "SignalLongName" SG_ 1472 CbnPrcndtngDsbldSOCLim "Cabin Preconditioning Disabled State of Charge Limit";
BA_ "SignalLongName" SG_ 1472 HiVltgBatPrcndtngEstdTmToCmpt "High Voltage Battery Preconditioning Estimated Time To Complete";
BA_ "SignalLongName" SG_ 1472 CbnPrcndtngSchTempCstSetVal "Cabin Preconditioning Schedule Temperature Customization Setting Value";
BA_ "SignalType" SG_ 1472 HiVltgBatLoSOCIndReq "ENM";
BA_ "SignalLongName" SG_ 1472 HiVltgBatLoSOCIndReq "High Voltage Battery Low State of Charge Indication Request";
BA_ "SignalType" SG_ 1472 HiVltgBatLoSOCIndReq_DuD "ENM";
BA_ "SignalLongName" SG_ 1472 HiVltgBatLoSOCIndReq_DuD "High Voltage Battery Low State of Charge Indication Request Don't Use Data";
BA_ "SignalType" SG_ 1472 HiVltgBatPrcndtngSts "ENM";
BA_ "SignalLongName" SG_ 1472 HiVltgBatPrcndtngSts "High Voltage Battery Preconditioning Status";
BA_ "SignalType" SG_ 1472 HiVltgBatPrcndtngSts_DuD "ENM";
BA_ "SignalLongName" SG_ 1472 HiVltgBatPrcndtngSts_DuD "High Voltage Battery Preconditioning Status Don't Use Data";
BA_ "SignalType" SG_ 1472 HVDCFstChrgPrepCmpltIndOn "ENM";
BA_ "SignalLongName" SG_ 1472 HVDCFstChrgPrepCmpltIndOn "High Voltage DC Fast Charge Preparation Complete Indication On";
BA_ "SignalType" SG_ 1472 HVDCFstChrgPerfLtdIndOn "ENM";
BA_ "SignalLongName" SG_ 1472 HVDCFstChrgPerfLtdIndOn "High Voltage DC Fast Charge Performance Limited Indication On";
BA_ "SignalType" SG_ 1472 CbnPrcndtngSchTempCstSetAval "ENM";
BA_ "SignalLongName" SG_ 1472 CbnPrcndtngSchTempCstSetAval "Cabin Preconditioning Schedule Temperature Customization Setting Available";
BA_ "SignalLongName" SG_ 954 HiVltgIsltnResist "High Voltage Isolation Resistance";
BA_ "SignalLongName" SG_ 954 HiVltgBatMaxCellVltg "High Voltage Battery Maximum Cell Voltage";
BA_ "SignalType" SG_ 954 HiVltgBatMaxCellVltg_Inv "ENM";
BA_ "SignalLongName" SG_ 954 HiVltgBatMaxCellVltg_Inv "High Voltage Battery Maximum Cell Voltage Invalid";
BA_ "SignalLongName" SG_ 954 HiVltgBatMinCellVltg "High Voltage Battery Minimum Cell Voltage";
BA_ "SignalType" SG_ 954 HiVltgBatMinCellVltg_Inv "ENM";
BA_ "SignalLongName" SG_ 954 HiVltgBatMinCellVltg_Inv "High Voltage Battery Minimum Cell Voltage Invalid";
BA_ "SignalLongName" SG_ 954 HiVltgBatMaxCellVltgNum "High Voltage Battery Maximum Cell Voltage Number";
BA_ "SignalLongName" SG_ 954 HiVltgBatMaxTempSnsrNum "High Voltage Battery Maximum Temperature Sensor Number";
BA_ "SignalLongName" SG_ 954 HiVltgBatMinCellVltgNum "High Voltage Battery Minimum Cell Voltage Number";
BA_ "SignalLongName" SG_ 954 HiVltgBatMinTempSnsrNum "High Voltage Battery Minimum Temperature Sensor Number";
BA_ "SignalType" SG_ 954 AuxPwrModDCDCStat "ENM";
BA_ "SignalLongName" SG_ 954 AuxPwrModDCDCStat "Auxiliary Power Module DC DC State";
BA_ "SignalLongName" SG_ 178 PrplSysInvrtADCCurrAuth "Propulsion System Inverter A DC Current Authenticated";
BA_ "SignalType" SG_ 178 PrplSysInvrtADCCurrAuth_Inv "ENM";
BA_ "SignalLongName" SG_ 178 PrplSysInvrtADCCurrAuth_Inv "Propulsion System Inverter A DC Current Authenticated Invalid";
BA_ "SignalType" SG_ 955 HVWrlsChrgFncActvtd "ENM";
BA_ "SignalLongName" SG_ 955 HVWrlsChrgFncActvtd "High Voltage Wireless Charging Function Activated";
BA_ "SignalType" SG_ 955 HVBatWrlsCntctrSts "ENM";
BA_ "SignalLongName" SG_ 955 HVBatWrlsCntctrSts "High Voltage Battery Wireless Contactor Status";
BA_ "SignalType" SG_ 955 HVWrlsChrgFncActvtdTyp "ENM";
BA_ "SignalLongName" SG_ 955 HVWrlsChrgFncActvtdTyp "High Voltage Wireless Charging Function Activated Type";
BA_ "SignalLongName" SG_ 534 HVWrlsChrgOutCurrCmndVal "High Voltage Wireless Charging Output Current Commanded Value";
BA_ "SignalLongName" SG_ 534 HVWrlsChrgOutVltgCmndVal "High Voltage Wireless Charging Output Voltage Commanded Value";
BA_ "SignalType" SG_ 534 HVWrlsChrgModeCmd "ENM";
BA_ "SignalLongName" SG_ 534 HVWrlsChrgModeCmd "High Voltage Wireless Charging Mode Command";
BA_ "SignalLongName" SG_ 1475 SecAxlDrvUntOilTemp "Serial Data 77 : Secondary Axle Drive Unit Oil Temperature";
BA_ "SignalLongName" SG_ 1475 SD77_ARC "Serial Data 77 : Alive Rolling Count";
BA_ "SignalType" SG_ 1475 SecAxlDrvUntOilTemp_Inv "ENM";
BA_ "SignalLongName" SG_ 1475 SecAxlDrvUntOilTemp_Inv "Serial Data 77 : Secondary Axle Drive Unit Oil Temperature Invalid";
BA_ "SignalType" SG_ 1435 RrStrgModeSeltnIndOn "ENM";
BA_ "SignalLongName" SG_ 1435 RrStrgModeSeltnIndOn "Rear Steering Mode Selection Indication On";
BA_ "SignalType" SG_ 1435 RrStrgModeUnvIndReq "ENM";
BA_ "SignalLongName" SG_ 1435 RrStrgModeUnvIndReq "Rear Steering Mode Unavailable Indication Request";
BA_ "SignalType" SG_ 1470 Sig4476 "ENM";
BA_ "SignalLongName" SG_ 1470 Sig4476 "Signal5059";
BA_ "SignalLongName" SG_ 1476 Sig5753 "Signal6754";
BA_ "SignalLongName" SG_ 1476 Sig5752 "Signal6752";
BA_ "SignalType" SG_ 1476 Sig5020 "ENM";
BA_ "SignalLongName" SG_ 1476 Sig5020 "Signal6753";
BA_ "SignalLongName" SG_ 1477 PnCActnReqCertfctNum "Plug And Charge Certificate Action Request : Plug And Charge Action Request Certificate Number";
BA_ "SignalType" SG_ 1477 PnCActnReqCertfctTyp "ENM";
BA_ "SignalLongName" SG_ 1477 PnCActnReqCertfctTyp "Plug And Charge Certificate Action Request : Plug And Charge Action Request Certificate Type";
BA_ "SignalType" SG_ 1477 PnCActnReqCertfctOp "ENM";
BA_ "SignalLongName" SG_ 1477 PnCActnReqCertfctOp "Plug And Charge Certificate Action Request : Plug And Charge Action Request Certificate Operation";
BA_ "SignalType" SG_ 1477 PnCEnblReq "ENM";
BA_ "SignalLongName" SG_ 1477 PnCEnblReq "Plug And Charge Enable Request";
BA_ "SignalType" SG_ 1496 AutoCoolServFllIndReq "ENM";
BA_ "SignalLongName" SG_ 1496 AutoCoolServFllIndReq "Automatic Coolant Service Fill Indication Request";
BA_ "SignalType" SG_ 1496 Sig4478 "ENM";
BA_ "SignalLongName" SG_ 1496 Sig4478 "Signal5061";
BA_ "SignalType" SG_ 1496 Sig2583 "ENM";
BA_ "SignalLongName" SG_ 1496 Sig2583 "Signal2578";
BA_ "SignalType" SG_ 1496 Sig4480 "ENM";
BA_ "SignalLongName" SG_ 1496 Sig4480 "Signal5063";
BA_ "SignalType" SG_ 1504 PrplSysChsSysPriAxlRtTrqReqSts "ENM";
BA_ "SignalLongName" SG_ 1504 PrplSysChsSysPriAxlRtTrqReqSts "Propulsion System Chassis System Primary Axle Torque Request Status : Propulsion System Chassis System Primary Axle Right Torque Request Status";
BA_ "SignalType" SG_ 1504 PrplSysChsSysPriAxlLtTrqReqSts "ENM";
BA_ "SignalLongName" SG_ 1504 PrplSysChsSysPriAxlLtTrqReqSts "Propulsion System Chassis System Primary Axle Torque Request Status : Propulsion System Chassis System Primary Axle Left Torque Request Status";
BA_ "SignalType" SG_ 1505 PrplSysElecPrkBrkApplReqd "ENM";
BA_ "SignalLongName" SG_ 1505 PrplSysElecPrkBrkApplReqd "Propulsion System Electric Park Brake Application Requested";
BA_ "SignalLongName" SG_ 74 PrplSysAxlTrqDstTrqCmdPriLt "Propulsion System Axle Torque Distribution Torque Command Primary : Propulsion System Axle Torque Distribution Torque Command Primary Left";
BA_ "SignalLongName" SG_ 74 PrplSysAxlTrqDstTrqCmdPriRt "Propulsion System Axle Torque Distribution Torque Command Primary : Propulsion System Axle Torque Distribution Torque Command Primary Right";
BA_ "SignalType" SG_ 74 DrvMtrSysFltd "ENM";
BA_ "SignalLongName" SG_ 74 DrvMtrSysFltd "Drive Motor System Faulted";
BA_ "SignalType" SG_ 1535 ICMTrngOncmgTrfcChmEvntStat "ENM";
BA_ "SignalLongName" SG_ 1535 ICMTrngOncmgTrfcChmEvntStat "Intersection Collision Mitigation Turning Oncoming Traffic Chime Event State";
BA_ "SignalType" SG_ 1535 ICMRtChmEvntStat "ENM";
BA_ "SignalLongName" SG_ 1535 ICMRtChmEvntStat "Intersection Collision Mitigation Right Chime Event State";
BA_ "SignalType" SG_ 1535 ICMLtChmEvntStat "ENM";
BA_ "SignalLongName" SG_ 1535 ICMLtChmEvntStat "Intersection Collision Mitigation Left Chime Event State";
BA_ "SignalType" SG_ 1811 RIMUnvTlgtIndOn "ENM";
BA_ "SignalLongName" SG_ 1811 RIMUnvTlgtIndOn "Rearward Impact Mitigation Unavailable Tailgate Indication On";
BA_ "SignalType" SG_ 1811 ICMWrnIndReq "ENM";
BA_ "SignalLongName" SG_ 1811 ICMWrnIndReq "Intersection Collision Mitigation Warning Indication Request";
BA_ "SignalLongName" SG_ 947 ICMLtHptcStReqSeqNum "Intersection Collision Mitigation Left Haptic Seat Request : Intersection Collision Mitigation Left Haptic Seat Request Sequence Number";
BA_ "SignalLongName" SG_ 947 ICMLtHptcStReqPuls "Intersection Collision Mitigation Left Haptic Seat Request : Intersection Collision Mitigation Left Haptic Seat Request Pulses";
BA_ "SignalLongName" SG_ 947 ICMRtHptcStReqSeqNum "Intersection Collision Mitigation Right Haptic Seat Request : Intersection Collision Mitigation Right Haptic Seat Request Sequence Number";
BA_ "SignalLongName" SG_ 947 ICMRtHptcStReqPuls "Intersection Collision Mitigation Right Haptic Seat Request : Intersection Collision Mitigation Right Haptic Seat Request Pulses";
BA_ "SignalLongName" SG_ 947 ICMTrngOncmgTrfcHptcStReqSeqNum "Intersection Collision Mitigation Turning Oncoming Traffic Haptic Seat Request : Intersection Collision Mitigation Turning Oncoming Traffic Haptic Seat Request Sequence Number";
BA_ "SignalLongName" SG_ 947 ICMTrngOncmgTrfcHptcStReqPuls "Intersection Collision Mitigation Turning Oncoming Traffic Haptic Seat Request : Intersection Collision Mitigation Turning Oncoming Traffic Haptic Seat Request Pulses";
BA_ "SignalLongName" SG_ 1812 PnCCertStsDispCertIssdFrmNm "Plug And Charge Certificate Status Display 2 : Plug And Charge Certificate Status Display Certificate Issued From Name";
BA_ "SignalLongName" SG_ 1812 PnCCertStsDispCertNum2 "Plug And Charge Certificate Status Display 2 : Plug And Charge Certificate Status Display Certificate Number 2";
BA_ "SignalType" SG_ 1812 PnCCertStsDispCertTyp2 "ENM";
BA_ "SignalLongName" SG_ 1812 PnCCertStsDispCertTyp2 "Plug And Charge Certificate Status Display 2 : Plug And Charge Certificate Status Display Certificate Type 2";
BA_ "SignalLongName" SG_ 1253 PnCCertStsDispCertIssdToNm "Plug And Charge Certificate Status Display 3 : Plug And Charge Certificate Status Display Certificate Issued To Name";
BA_ "SignalLongName" SG_ 1253 PnCCertStsDispCertNum3 "Plug And Charge Certificate Status Display 3 : Plug And Charge Certificate Status Display Certificate Number 3";
BA_ "SignalType" SG_ 1253 PnCCertStsDispCertTyp3 "ENM";
BA_ "SignalLongName" SG_ 1253 PnCCertStsDispCertTyp3 "Plug And Charge Certificate Status Display 3 : Plug And Charge Certificate Status Display Certificate Type 3";
BA_ "SignalLongName" SG_ 1813 PnCCertStsDispCertExpiryDate "Plug And Charge Certificate Status Display 4 : Plug And Charge Certificate Status Display Certificate Expiry Date";
BA_ "SignalLongName" SG_ 1813 PnCCertStsDispCertIssDate "Plug And Charge Certificate Status Display 4 : Plug And Charge Certificate Status Display Certificate Issue Date";
BA_ "SignalLongName" SG_ 1813 PnCCertStsDispCertNum4 "Plug And Charge Certificate Status Display 4 : Plug And Charge Certificate Status Display Certificate Number 4";
BA_ "SignalType" SG_ 1813 PnCCertStsDispCertTyp4 "ENM";
BA_ "SignalLongName" SG_ 1813 PnCCertStsDispCertTyp4 "Plug And Charge Certificate Status Display 4 : Plug And Charge Certificate Status Display Certificate Type 4";
BA_ "SignalLongName" SG_ 1813 PnCCertStsDispCertNum1 "Plug And Charge Certificate Status Display 1 : Plug And Charge Certificate Status Display Certificate Number 1";
BA_ "SignalType" SG_ 1813 PnCCertStsDispCertTyp1 "ENM";
BA_ "SignalLongName" SG_ 1813 PnCCertStsDispCertTyp1 "Plug And Charge Certificate Status Display 1 : Plug And Charge Certificate Status Display Certificate Type 1";
BA_ "SignalType" SG_ 1813 PnCCertStsDispCertSts "ENM";
BA_ "SignalLongName" SG_ 1813 PnCCertStsDispCertSts "Plug And Charge Certificate Status Display 1 : Plug And Charge Certificate Status Display Certificate Status";
BA_ "SignalLongName" SG_ 1813 PnCCertStsDispNumOfCertsInstld "Plug And Charge Certificate Status Display 1 : Plug And Charge Certificate Status Display Number of Certificates Installed";
BA_ "SignalLongName" SG_ 1813 PnCCertStsDispNumOfCertsSuptd "Plug And Charge Certificate Status Display 1 : Plug And Charge Certificate Status Display Number of Certificates Supported";
BA_ "SignalLongName" SG_ 1252 PnCCertStsDispCertIdNum "Plug And Charge Certificate Status Display 5 : Plug And Charge Certificate Status Display Certificate Identification Number";
BA_ "SignalLongName" SG_ 1252 PnCCertStsDispCertNum5 "Plug And Charge Certificate Status Display 5 : Plug And Charge Certificate Status Display Certificate Number 5";
BA_ "SignalType" SG_ 1252 PnCCertStsDispCertTyp5 "ENM";
BA_ "SignalLongName" SG_ 1252 PnCCertStsDispCertTyp5 "Plug And Charge Certificate Status Display 5 : Plug And Charge Certificate Status Display Certificate Type 5";
BA_ "SignalLongName" SG_ 1252 PnCPrvsngCertID "Plug And Charge Provisioning Certificate ID";
BA_ "SignalType" SG_ 957 Sig0071 "ENM";
BA_ "SignalLongName" SG_ 957 Sig0071 "Signal0175";
BA_ "SignalType" SG_ 116 HVBatOutOfEngyRdcdPrplReq "ENM";
BA_ "SignalLongName" SG_ 116 HVBatOutOfEngyRdcdPrplReq "High Voltage Battery Out Of Energy Reduced Propulsion Request";
BA_ "SignalType" SG_ 958 Sig0070 "ENM";
BA_ "SignalLongName" SG_ 958 Sig0070 "Signal0174";
BA_ "SignalLongName" SG_ 1814 DrvMtrInvrt3MaxTemp "Drive Motor Inverter 3 Maximum Temperature";
BA_ "SignalType" SG_ 1814 DrvMtrInvrt3MaxTemp_Inv "ENM";
BA_ "SignalLongName" SG_ 1814 DrvMtrInvrt3MaxTemp_Inv "Drive Motor Inverter 3 Maximum Temperature Invalid";
BA_ "SignalType" SG_ 1815 ManRgnModeOvrrdn "ENM";
BA_ "SignalLongName" SG_ 1815 ManRgnModeOvrrdn "Manual Regeneration Mode Overridden";
BA_ "SignalLongName" SG_ 1250 PnCActnStsCertfctNum "Plug And Charge Certificate Action Status : Plug And Charge Action Status Certificate Number";
BA_ "SignalType" SG_ 1250 PnCActnStsCertfctTyp "ENM";
BA_ "SignalLongName" SG_ 1250 PnCActnStsCertfctTyp "Plug And Charge Certificate Action Status : Plug And Charge Action Status Certificate Type";
BA_ "SignalType" SG_ 1250 PnCActnStsCertfctOpSts "ENM";
BA_ "SignalLongName" SG_ 1250 PnCActnStsCertfctOpSts "Plug And Charge Certificate Action Status : Plug And Charge Action Status Certificate Operation Status";
BA_ "SignalType" SG_ 1250 PnCStsDisp "ENM";
BA_ "SignalLongName" SG_ 1250 PnCStsDisp "Plug And Charge Status Display";
BA_ "SignalType" SG_ 1250 PnCEnbldSts "ENM";
BA_ "SignalLongName" SG_ 1250 PnCEnbldSts "Plug And Charge Enabled Status";
BA_ "SignalLongName" SG_ 659 GNSSVel01EstVel "Global Navigation Satellite System Velocity 01 : Global Navigation Satellite System Velocity 01 East Velocity";
BA_ "SignalLongName" SG_ 659 GNSSVel01EstVelUncrtnty "Global Navigation Satellite System Velocity 01 : Global Navigation Satellite System Velocity 01 East Velocity Uncertainty";
BA_ "SignalType" SG_ 659 GNSSVel01EstVelUncrtnty_DuD "ENM";
BA_ "SignalLongName" SG_ 659 GNSSVel01EstVelUncrtnty_DuD "Global Navigation Satellite System Velocity 01 : Global Navigation Satellite System Velocity 01 East Velocity Uncertainty Don't Use Data";
BA_ "SignalLongName" SG_ 659 GNSSVel01NrthVel "Global Navigation Satellite System Velocity 01 : Global Navigation Satellite System Velocity 01 North Velocity";
BA_ "SignalType" SG_ 659 GNSSVel01EstVel_Inv "ENM";
BA_ "SignalLongName" SG_ 659 GNSSVel01EstVel_Inv "Global Navigation Satellite System Velocity 01 : Global Navigation Satellite System Velocity 01 East Velocity Invalid";
BA_ "SignalType" SG_ 659 GNSSVel01EstVel_DuD "ENM";
BA_ "SignalLongName" SG_ 659 GNSSVel01EstVel_DuD "Global Navigation Satellite System Velocity 01 : Global Navigation Satellite System Velocity 01 East Velocity Don't Use Data";
BA_ "SignalType" SG_ 659 GNSSVel01EstVelUncrtnty_Inv "ENM";
BA_ "SignalLongName" SG_ 659 GNSSVel01EstVelUncrtnty_Inv "Global Navigation Satellite System Velocity 01 : Global Navigation Satellite System Velocity 01 East Velocity Uncertainty Invalid";
BA_ "SignalLongName" SG_ 659 GNSSVel01NrthVelUncrtnty "Global Navigation Satellite System Velocity 01 : Global Navigation Satellite System Velocity 01 North Velocity Uncertainty";
BA_ "SignalLongName" SG_ 659 GNSSVel02UpVel "Global Navigation Satellite System Velocity 02 : Global Navigation Satellite System Velocity 02 Up Velocity";
BA_ "SignalType" SG_ 659 GNSSVel01NrthVel_Inv "ENM";
BA_ "SignalLongName" SG_ 659 GNSSVel01NrthVel_Inv "Global Navigation Satellite System Velocity 01 : Global Navigation Satellite System Velocity 01 North Velocity Invalid";
BA_ "SignalType" SG_ 659 GNSSVel01NrthVel_DuD "ENM";
BA_ "SignalLongName" SG_ 659 GNSSVel01NrthVel_DuD "Global Navigation Satellite System Velocity 01 : Global Navigation Satellite System Velocity 01 North Velocity Don't Use Data";
BA_ "SignalType" SG_ 659 GNSSVel01NrthVelUncrtnty_Inv "ENM";
BA_ "SignalLongName" SG_ 659 GNSSVel01NrthVelUncrtnty_Inv "Global Navigation Satellite System Velocity 01 : Global Navigation Satellite System Velocity 01 North Velocity Uncertainty Invalid";
BA_ "SignalType" SG_ 659 GNSSVel01NrthVelUncrtnty_DuD "ENM";
BA_ "SignalLongName" SG_ 659 GNSSVel01NrthVelUncrtnty_DuD "Global Navigation Satellite System Velocity 01 : Global Navigation Satellite System Velocity 01 North Velocity Uncertainty Don't Use Data";
BA_ "SignalLongName" SG_ 659 GNSSVel02UpVelUncrtnty "Global Navigation Satellite System Velocity 02 : Global Navigation Satellite System Velocity 02 Up Velocity Uncertainty";
BA_ "SignalType" SG_ 659 GNSSVel02UpVel_Inv "ENM";
BA_ "SignalLongName" SG_ 659 GNSSVel02UpVel_Inv "Global Navigation Satellite System Velocity 02 : Global Navigation Satellite System Velocity 02 Up Velocity Invalid";
BA_ "SignalType" SG_ 659 GNSSVel02UpVel_DuD "ENM";
BA_ "SignalLongName" SG_ 659 GNSSVel02UpVel_DuD "Global Navigation Satellite System Velocity 02 : Global Navigation Satellite System Velocity 02 Up Velocity Don't Use Data";
BA_ "SignalType" SG_ 659 GNSSVel02UpVelUncrtnty_Inv "ENM";
BA_ "SignalLongName" SG_ 659 GNSSVel02UpVelUncrtnty_Inv "Global Navigation Satellite System Velocity 02 : Global Navigation Satellite System Velocity 02 Up Velocity Uncertainty Invalid";
BA_ "SignalType" SG_ 659 GNSSVel02UpVelUncrtnty_DuD "ENM";
BA_ "SignalLongName" SG_ 659 GNSSVel02UpVelUncrtnty_DuD "Global Navigation Satellite System Velocity 02 : Global Navigation Satellite System Velocity 02 Up Velocity Uncertainty Don't Use Data";
BA_ "SignalType" SG_ 659 GPSQM_PPSMode "ENM";
BA_ "SignalLongName" SG_ 659 GPSQM_PPSMode "Global Positioning System Quality Metrics : Precise Positioning System Mode";
BA_ "SignalType" SG_ 659 GPSQM_PPSMode_Inv "ENM";
BA_ "SignalLongName" SG_ 659 GPSQM_PPSMode_Inv "Global Positioning System Quality Metrics : Precise Positioning System Mode Invalid";
BA_ "SignalType" SG_ 659 WndPstnStsRR "ENM";
BA_ "SignalLongName" SG_ 659 WndPstnStsRR "Window Position Status Right Rear";
BA_ "SignalType" SG_ 659 WndPstnStsLR "ENM";
BA_ "SignalLongName" SG_ 659 WndPstnStsLR "Window Position Status Left Rear";
BA_ "SignalType" SG_ 1249 HiBmSelSwActv "ENM";
BA_ "SignalLongName" SG_ 1249 HiBmSelSwActv "High Beam Select Switch Active";
BA_ "SignalType" SG_ 1249 AE44BkBtnSts "ENM";
BA_ "SignalLongName" SG_ 1249 AE44BkBtnSts "Advanced Park Assist Back Button Status";
BA_ "SignalType" SG_ 1249 AE44SuprPrkSts "ENM";
BA_ "SignalLongName" SG_ 1249 AE44SuprPrkSts "Advanced Park Assist Supervised Parking Status";
BA_ "SignalLongName" SG_ 961 LvlgSysFrtAxlEstdLd "Leveling System Front Axle Estimated Load";
BA_ "SignalLongName" SG_ 961 LvlgSysRrAxlEstdLd "Leveling System Rear Axle Estimated Load";
BA_ "SignalType" SG_ 1817 LnchCtlUnvRsn "ENM";
BA_ "SignalLongName" SG_ 1817 LnchCtlUnvRsn "Launch Control Information : Launch Control Unavailable Reason";
BA_ "SignalType" SG_ 1817 LnchCtlSts "ENM";
BA_ "SignalLongName" SG_ 1817 LnchCtlSts "Launch Control Information : Launch Control Status";
BA_ "SignalType" SG_ 1817 LnchCtlCchTrgrd "ENM";
BA_ "SignalLongName" SG_ 1817 LnchCtlCchTrgrd "Launch Control Information : Launch Control Coach Triggered";
BA_ "SignalType" SG_ 1817 EVPedMpPerfModeReq "ENM";
BA_ "SignalLongName" SG_ 1817 EVPedMpPerfModeReq "Electric Vehicle Pedal Map Performance Mode Request";
BA_ "SignalType" SG_ 31 Sig2415 "ENM";
BA_ "SignalLongName" SG_ 31 Sig2415 "Signal2318";
BA_ "SignalType" SG_ 1248 VirtRrAxlLckSts "ENM";
BA_ "SignalLongName" SG_ 1248 VirtRrAxlLckSts "Virtual Rear Axle Lock Status";
BA_ "SignalLongName" SG_ 960 PrplSysMtrCRotrTemp "Propulsion System Motor C Rotor Temperature";
BA_ "SignalType" SG_ 960 PrplSysMtrCRotrTemp_Inv "ENM";
BA_ "SignalLongName" SG_ 960 PrplSysMtrCRotrTemp_Inv "Propulsion System Motor C Rotor Temperature Invalid";
BA_ "SignalLongName" SG_ 960 PrplSysMtrCSttrTemp "Propulsion System Motor C Stator Temperature";
BA_ "SignalType" SG_ 960 PrplSysMtrCSttrTemp_Inv "ENM";
BA_ "SignalLongName" SG_ 960 PrplSysMtrCSttrTemp_Inv "Propulsion System Motor C Stator Temperature Invalid";
BA_ "SignalType" SG_ 117 Sig2414 "ENM";
BA_ "SignalLongName" SG_ 117 Sig2414 "Signal2317";
BA_ "SignalType" SG_ 1818 SuprRmtPrkAval "ENM";
BA_ "SignalLongName" SG_ 1818 SuprRmtPrkAval "Supervised Remote Parking Available";
BA_ "SignalType" SG_ 1247 Sig4600 "ENM";
BA_ "SignalLongName" SG_ 1247 Sig4600 "Signal4907";
BA_ "SignalType" SG_ 1247 Sig4599 "ENM";
BA_ "SignalLongName" SG_ 1247 Sig4599 "Signal4906";
BA_ "SignalType" SG_ 1247 Sig4598 "ENM";
BA_ "SignalLongName" SG_ 1247 Sig4598 "Signal4905";
BA_ "SignalType" SG_ 1247 Sig4597 "ENM";
BA_ "SignalLongName" SG_ 1247 Sig4597 "Signal4904";
BA_ "SignalType" SG_ 1247 Sig4596 "ENM";
BA_ "SignalLongName" SG_ 1247 Sig4596 "Signal4903";
BA_ "SignalType" SG_ 1247 Sig4595 "ENM";
BA_ "SignalLongName" SG_ 1247 Sig4595 "Signal4902";
BA_ "SignalType" SG_ 1247 E49HrnChrpReq "ENM";
BA_ "SignalLongName" SG_ 1247 E49HrnChrpReq "Power Take Off Horn Chirp Request";
BA_ "SignalType" SG_ 1247 Sig4608 "ENM";
BA_ "SignalLongName" SG_ 1247 Sig4608 "Signal4915";
BA_ "SignalType" SG_ 1247 Sig4607 "ENM";
BA_ "SignalLongName" SG_ 1247 Sig4607 "Signal4914";
BA_ "SignalType" SG_ 1247 Sig4606 "ENM";
BA_ "SignalLongName" SG_ 1247 Sig4606 "Signal4913";
BA_ "SignalType" SG_ 1247 Sig4605 "ENM";
BA_ "SignalLongName" SG_ 1247 Sig4605 "Signal4912";
BA_ "SignalType" SG_ 1247 Sig4604 "ENM";
BA_ "SignalLongName" SG_ 1247 Sig4604 "Signal4911";
BA_ "SignalType" SG_ 1247 Sig4603 "ENM";
BA_ "SignalLongName" SG_ 1247 Sig4603 "Signal4910";
BA_ "SignalType" SG_ 1247 Sig4602 "ENM";
BA_ "SignalLongName" SG_ 1247 Sig4602 "Signal4909";
BA_ "SignalType" SG_ 1247 Sig4601 "ENM";
BA_ "SignalLongName" SG_ 1247 Sig4601 "Signal4908";
BA_ "SignalType" SG_ 1247 Sig4802 "ENM";
BA_ "SignalLongName" SG_ 1247 Sig4802 "Signal4986";
BA_ "SignalType" SG_ 1247 Sig4801 "ENM";
BA_ "SignalLongName" SG_ 1247 Sig4801 "Signal4985";
BA_ "SignalType" SG_ 1247 Sig4800 "ENM";
BA_ "SignalLongName" SG_ 1247 Sig4800 "Signal4984";
BA_ "SignalType" SG_ 1247 Sig4688 "ENM";
BA_ "SignalLongName" SG_ 1247 Sig4688 "Signal4934";
BA_ "SignalType" SG_ 1247 Sig4687 "ENM";
BA_ "SignalLongName" SG_ 1247 Sig4687 "Signal4933";
BA_ "SignalType" SG_ 1247 Sig4626 "ENM";
BA_ "SignalLongName" SG_ 1247 Sig4626 "Signal4924";
BA_ "SignalType" SG_ 1247 Sig4625 "ENM";
BA_ "SignalLongName" SG_ 1247 Sig4625 "Signal4923";
BA_ "SignalType" SG_ 1247 Sig4609 "ENM";
BA_ "SignalLongName" SG_ 1247 Sig4609 "Signal4916";
BA_ "SignalType" SG_ 1247 Sig4810 "ENM";
BA_ "SignalLongName" SG_ 1247 Sig4810 "Signal4994";
BA_ "SignalType" SG_ 1247 Sig4809 "ENM";
BA_ "SignalLongName" SG_ 1247 Sig4809 "Signal4993";
BA_ "SignalType" SG_ 1247 Sig4808 "ENM";
BA_ "SignalLongName" SG_ 1247 Sig4808 "Signal4992";
BA_ "SignalType" SG_ 1247 Sig4807 "ENM";
BA_ "SignalLongName" SG_ 1247 Sig4807 "Signal4991";
BA_ "SignalType" SG_ 1247 Sig4806 "ENM";
BA_ "SignalLongName" SG_ 1247 Sig4806 "Signal4990";
BA_ "SignalType" SG_ 1247 Sig4805 "ENM";
BA_ "SignalLongName" SG_ 1247 Sig4805 "Signal4989";
BA_ "SignalType" SG_ 1247 Sig4804 "ENM";
BA_ "SignalLongName" SG_ 1247 Sig4804 "Signal4988";
BA_ "SignalType" SG_ 1247 Sig4803 "ENM";
BA_ "SignalLongName" SG_ 1247 Sig4803 "Signal4987";
BA_ "SignalType" SG_ 1247 Sig4826 "ENM";
BA_ "SignalLongName" SG_ 1247 Sig4826 "Signal5008";
BA_ "SignalType" SG_ 1247 Sig4825 "ENM";
BA_ "SignalLongName" SG_ 1247 Sig4825 "Signal5007";
BA_ "SignalType" SG_ 1247 Sig4824 "ENM";
BA_ "SignalLongName" SG_ 1247 Sig4824 "Signal5006";
BA_ "SignalType" SG_ 1247 Sig4823 "ENM";
BA_ "SignalLongName" SG_ 1247 Sig4823 "Signal5005";
BA_ "SignalType" SG_ 1247 Sig4814 "ENM";
BA_ "SignalLongName" SG_ 1247 Sig4814 "Signal4998";
BA_ "SignalType" SG_ 1247 Sig4813 "ENM";
BA_ "SignalLongName" SG_ 1247 Sig4813 "Signal4997";
BA_ "SignalType" SG_ 1247 Sig4812 "ENM";
BA_ "SignalLongName" SG_ 1247 Sig4812 "Signal4996";
BA_ "SignalType" SG_ 1247 Sig4811 "ENM";
BA_ "SignalLongName" SG_ 1247 Sig4811 "Signal4995";
BA_ "SignalType" SG_ 1247 Sig4834 "ENM";
BA_ "SignalLongName" SG_ 1247 Sig4834 "Signal5016";
BA_ "SignalType" SG_ 1247 Sig4833 "ENM";
BA_ "SignalLongName" SG_ 1247 Sig4833 "Signal5015";
BA_ "SignalType" SG_ 1247 Sig4832 "ENM";
BA_ "SignalLongName" SG_ 1247 Sig4832 "Signal5014";
BA_ "SignalType" SG_ 1247 Sig4831 "ENM";
BA_ "SignalLongName" SG_ 1247 Sig4831 "Signal5013";
BA_ "SignalType" SG_ 1247 Sig4830 "ENM";
BA_ "SignalLongName" SG_ 1247 Sig4830 "Signal5012";
BA_ "SignalType" SG_ 1247 Sig4829 "ENM";
BA_ "SignalLongName" SG_ 1247 Sig4829 "Signal5011";
BA_ "SignalType" SG_ 1247 Sig4828 "ENM";
BA_ "SignalLongName" SG_ 1247 Sig4828 "Signal5010";
BA_ "SignalType" SG_ 1247 Sig4827 "ENM";
BA_ "SignalLongName" SG_ 1247 Sig4827 "Signal5009";
BA_ "SignalType" SG_ 1247 Sig4860 "ENM";
BA_ "SignalLongName" SG_ 1247 Sig4860 "Signal5031";
BA_ "SignalType" SG_ 1247 Sig4859 "ENM";
BA_ "SignalLongName" SG_ 1247 Sig4859 "Signal5030";
BA_ "SignalType" SG_ 1247 Sig4858 "ENM";
BA_ "SignalLongName" SG_ 1247 Sig4858 "Signal5029";
BA_ "SignalType" SG_ 1247 Sig4857 "ENM";
BA_ "SignalLongName" SG_ 1247 Sig4857 "Signal5028";
BA_ "SignalType" SG_ 1247 Sig4856 "ENM";
BA_ "SignalLongName" SG_ 1247 Sig4856 "Signal5027";
BA_ "SignalType" SG_ 1247 Sig4837 "ENM";
BA_ "SignalLongName" SG_ 1247 Sig4837 "Signal5019";
BA_ "SignalType" SG_ 1247 Sig4836 "ENM";
BA_ "SignalLongName" SG_ 1247 Sig4836 "Signal5018";
BA_ "SignalType" SG_ 1247 Sig4835 "ENM";
BA_ "SignalLongName" SG_ 1247 Sig4835 "Signal5017";
BA_ "SignalType" SG_ 1247 Sig4883 "ENM";
BA_ "SignalLongName" SG_ 1247 Sig4883 "Signal5045";
BA_ "SignalType" SG_ 1247 Sig4882 "ENM";
BA_ "SignalLongName" SG_ 1247 Sig4882 "Signal5044";
BA_ "SignalType" SG_ 1247 Sig4881 "ENM";
BA_ "SignalLongName" SG_ 1247 Sig4881 "Signal5043";
BA_ "SignalType" SG_ 1247 Sig4880 "ENM";
BA_ "SignalLongName" SG_ 1247 Sig4880 "Signal5042";
BA_ "SignalType" SG_ 1247 Sig4879 "ENM";
BA_ "SignalLongName" SG_ 1247 Sig4879 "Signal5041";
BA_ "SignalType" SG_ 1247 Sig4878 "ENM";
BA_ "SignalLongName" SG_ 1247 Sig4878 "Signal5040";
BA_ "SignalType" SG_ 1247 Sig4862 "ENM";
BA_ "SignalLongName" SG_ 1247 Sig4862 "Signal5033";
BA_ "SignalType" SG_ 1247 Sig4861 "ENM";
BA_ "SignalLongName" SG_ 1247 Sig4861 "Signal5032";
BA_ "SignalType" SG_ 1247 Sig4884 "ENM";
BA_ "SignalLongName" SG_ 1247 Sig4884 "Signal5046";
BA_ "SignalType" SG_ 661 LIBSOCCalReqd "ENM";
BA_ "SignalLongName" SG_ 661 LIBSOCCalReqd "Lithium Ion Battery State of Charge Calibration Requested";
BA_ "SignalLongName" SG_ 1819 ChrgCycEleclEngyUsd "Charge Cycle Electrical Energy Used";
BA_ "SignalType" SG_ 1819 ChrgCycEleclEngyUsd_DuD "ENM";
BA_ "SignalLongName" SG_ 1819 ChrgCycEleclEngyUsd_DuD "Charge Cycle Electrical Energy Used Don't Use Data";
BA_ "SignalType" SG_ 1819 OffBrdVehImbNtfn "ENM";
BA_ "SignalLongName" SG_ 1819 OffBrdVehImbNtfn "Off Board Vehicle Immobilization Notification";
BA_ "SignalLongName" SG_ 1819 LifetmEleclEngyEcon "Lifetime Electrical Energy Economy";
BA_ "SignalType" SG_ 1819 LifetmEleclEngyEcon_DuD "ENM";
BA_ "SignalLongName" SG_ 1819 LifetmEleclEngyEcon_DuD "Lifetime Electrical Energy Economy Don't Use Data";
BA_ "SignalLongName" SG_ 176 Sig4428 "Signal4625";
BA_ "SignalLongName" SG_ 536 Sig2531 "Signal2689";
BA_ "SignalLongName" SG_ 536 Sig2533 "Signal2688";
BA_ "SignalLongName" SG_ 536 Sig4427 "Signal4624";
BA_ "SignalLongName" SG_ 536 Sig2532 "Signal2690";
BA_ "SignalLongName" SG_ 1246 HVThrmlPwrCnsmd "High Voltage Thermal Power Information : High Voltage Thermal Power Consumed";
BA_ "SignalType" SG_ 1246 HVThrmlPwrCnsmd_Inv "ENM";
BA_ "SignalLongName" SG_ 1246 HVThrmlPwrCnsmd_Inv "High Voltage Thermal Power Information : High Voltage Thermal Power Consumed Invalid";
BA_ "SignalType" SG_ 1246 HVThrmlPwrCnsmd_DuD "ENM";
BA_ "SignalLongName" SG_ 1246 HVThrmlPwrCnsmd_DuD "High Voltage Thermal Power Information : High Voltage Thermal Power Consumed Don't Use Data";
BA_ "SignalLongName" SG_ 959 RmtPRNDMBklgtLvl "Remote PRNDM Backlighting Level";
BA_ "SignalLongName" SG_ 959 RmtPRNDMIndLvl "Remote PRNDM Indicator Level";
BA_ "SignalLongName" SG_ 73 Sig4939 "Signal5098";
BA_ "SignalType" SG_ 73 Sig4940 "ENM";
BA_ "SignalLongName" SG_ 73 Sig4940 "Signal5099";
BA_ "SignalType" SG_ 1821 EngCmptAjr "ENM";
BA_ "SignalLongName" SG_ 1821 EngCmptAjr "Engine Compartment Ajar";
BA_ "SignalType" SG_ 1821 EngCmptAjr_Inv "ENM";
BA_ "SignalLongName" SG_ 1821 EngCmptAjr_Inv "Engine Compartment Ajar Invalid";
BA_ "SignalType" SG_ 738 Sig7819 "ENM";
BA_ "SignalLongName" SG_ 738 Sig7819 "Signal7838";
BA_ "SignalType" SG_ 1245 ElecShfPriLoManSeltnIndReq "ENM";
BA_ "SignalLongName" SG_ 1245 ElecShfPriLoManSeltnIndReq "Electronic Shift Primary Low/Manual Selection Indication Request";
BA_ "SignalType" SG_ 1244 DrLckLRStsAuth "ENM";
BA_ "SignalLongName" SG_ 1244 DrLckLRStsAuth "Serial Data 86 Protected : Door Lock Left Rear Status Authenticated";
BA_ "SignalType" SG_ 1244 DrLckLFStsAuth "ENM";
BA_ "SignalLongName" SG_ 1244 DrLckLFStsAuth "Serial Data 86 Protected : Door Lock Left Front Status Authenticated";
BA_ "SignalType" SG_ 1244 CntrStckDispFlrIndOn "ENM";
BA_ "SignalLongName" SG_ 1244 CntrStckDispFlrIndOn "HMI General Information 3 Protected : Center Stack Display Failure Indication On";
BA_ "SignalType" SG_ 1244 ICMCstChgSetReq "ENM";
BA_ "SignalLongName" SG_ 1244 ICMCstChgSetReq "Intersection Collision Mitigation Customization Change Setting Request";
BA_ "SignalType" SG_ 1244 PrplDispExtndCpbltyLvlPct_DuD "ENM";
BA_ "SignalLongName" SG_ 1244 PrplDispExtndCpbltyLvlPct_DuD "Propulsion Display Extended Capability Information : Propulsion Display Extended Capability Level Percent Don't Use Data";
BA_ "SignalType" SG_ 1244 Sig7636 "ENM";
BA_ "SignalLongName" SG_ 1244 Sig7636 "Signal7752";
BA_ "SignalType" SG_ 1244 CrnrLmpRtCmndOn "ENM";
BA_ "SignalLongName" SG_ 1244 CrnrLmpRtCmndOn "Cornering Lamp Right Commanded On";
BA_ "SignalType" SG_ 1244 CrnrLmpLtCmndOn "ENM";
BA_ "SignalLongName" SG_ 1244 CrnrLmpLtCmndOn "Cornering Lamp Left Commanded On";
BA_ "SignalType" SG_ 1244 DrLckRRStsAuth "ENM";
BA_ "SignalLongName" SG_ 1244 DrLckRRStsAuth "Serial Data 86 Protected : Door Lock Right Rear Status Authenticated";
BA_ "SignalType" SG_ 1244 DrLckRFStsAuth "ENM";
BA_ "SignalLongName" SG_ 1244 DrLckRFStsAuth "Serial Data 86 Protected : Door Lock Right Front Status Authenticated";
BA_ "SignalType" SG_ 1244 DMSDrwIntnWrnDrvrResp "ENM";
BA_ "SignalLongName" SG_ 1244 DMSDrwIntnWrnDrvrResp "Driver Monitoring System Drowsy And Inattentive Warning Driver Response";
BA_ "SignalLongName" SG_ 1244 PrplDispExtndCpbltyLvlPct "Propulsion Display Extended Capability Information : Propulsion Display Extended Capability Level Percent";
BA_ "SignalType" SG_ 1244 E44SftBtnSeltdStatRw "ENM";
BA_ "SignalLongName" SG_ 1244 E44SftBtnSeltdStatRw "Park Assist Soft Button Selected State Raw";
BA_ "SignalType" SG_ 1244 FrtCmptShftrLckReqd "ENM";
BA_ "SignalLongName" SG_ 1244 FrtCmptShftrLckReqd "Front Compartment Shifter Lock Requested";
BA_ "SignalType" SG_ 1244 VirtCtlVehEmrgOffSwReqd "ENM";
BA_ "SignalLongName" SG_ 1244 VirtCtlVehEmrgOffSwReqd "HMI General Information 3 Protected : Virtual Control Vehicle Emergency Off Switch Requested";
BA_ "SignalType" SG_ 1244 VirtCtlVehOffSwReq "ENM";
BA_ "SignalLongName" SG_ 1244 VirtCtlVehOffSwReq "HMI General Information 3 Protected : Virtual Control Vehicle Off Switch Request";
BA_ "SignalType" SG_ 1244 DrMtzdStBltUnIndOn "ENM";
BA_ "SignalLongName" SG_ 1244 DrMtzdStBltUnIndOn "Driver Motorized Seat Belt Unavailable Indication On";
BA_ "SignalType" SG_ 1822 ICMCstAvlFlg5 "ENM";
BA_ "SignalLongName" SG_ 1822 ICMCstAvlFlg5 "Intersection Collision Mitigation Customization Availability Flag 5";
BA_ "SignalType" SG_ 1822 ICMCstAvlFlg4 "ENM";
BA_ "SignalLongName" SG_ 1822 ICMCstAvlFlg4 "Intersection Collision Mitigation Customization Availability Flag 4";
BA_ "SignalType" SG_ 1822 ICMCstAvlFlg3 "ENM";
BA_ "SignalLongName" SG_ 1822 ICMCstAvlFlg3 "Intersection Collision Mitigation Customization Availability Flag 3";
BA_ "SignalType" SG_ 1822 ICMCstAvlFlg2 "ENM";
BA_ "SignalLongName" SG_ 1822 ICMCstAvlFlg2 "Intersection Collision Mitigation Customization Availability Flag 2";
BA_ "SignalType" SG_ 1822 ICMCstAvlFlg1 "ENM";
BA_ "SignalLongName" SG_ 1822 ICMCstAvlFlg1 "Intersection Collision Mitigation Customization Availability Flag 1";
BA_ "SignalType" SG_ 1822 ICMCstSelCstCurSetVal "ENM";
BA_ "SignalLongName" SG_ 1822 ICMCstSelCstCurSetVal "Intersection Collision Mitigation Customization Select Customization Current Setting Value";
BA_ "SignalType" SG_ 1822 ICMCstSelCstSetAval "ENM";
BA_ "SignalLongName" SG_ 1822 ICMCstSelCstSetAval "Intersection Collision Mitigation Customization Select Customization Setting Available";
BA_ "SignalType" SG_ 1822 ICMCstAvlFlg7 "ENM";
BA_ "SignalLongName" SG_ 1822 ICMCstAvlFlg7 "Intersection Collision Mitigation Customization Availability Flag 7";
BA_ "SignalType" SG_ 1822 ICMCstAvlFlg6 "ENM";
BA_ "SignalLongName" SG_ 1822 ICMCstAvlFlg6 "Intersection Collision Mitigation Customization Availability Flag 6";
BA_ "SignalLongName" SG_ 175 PrcsrSecurPtrn_ECP_E "Processor Security Pattern - ECP_E";
BA_ "SignalLongName" SG_ 537 PrcsrSecurPtrn_VICM "Processor Security Pattern - VICM";
BA_ "SignalLongName" SG_ 30 Sig2581 "Signal2576";
BA_ "SignalType" SG_ 30 Sig2582 "ENM";
BA_ "SignalLongName" SG_ 30 Sig2582 "Signal2577";
BA_ "SignalType" SG_ 30 PrplSysSecAxlTrqReqStsChsSys "ENM";
BA_ "SignalLongName" SG_ 30 PrplSysSecAxlTrqReqStsChsSys "Propulsion System Secondary Axle Torque Request Status Chassis System";
BA_ "SignalLongName" SG_ 30 Sig2658 "Signal2663";
BA_ "SignalType" SG_ 30 Sig2659 "ENM";
BA_ "SignalLongName" SG_ 30 Sig2659 "Signal2664";
BA_ "SignalLongName" SG_ 1243 NextChrgDestLat "Next Charging Destination Information 2 : Next Charging Destination Latitude";
BA_ "SignalLongName" SG_ 1243 NextChrgDestLng "Next Charging Destination Information 2 : Next Charging Destination Longitude";
BA_ "SignalLongName" SG_ 1243 NavRtePrdtdCustUsblSOC "Navigation Route Information 1 : Navigation Route Predicted Customer Usable State of Charge";
BA_ "SignalType" SG_ 1243 NavRteChgOcc "ENM";
BA_ "SignalLongName" SG_ 1243 NavRteChgOcc "Navigation Route Information 1 : Navigation Route Change Occurred";
BA_ "SignalLongName" SG_ 1243 NavRtePrdtdOAT "Navigation Route Information 1 : Navigation Route Predicted Outside Air Temperature";
BA_ "SignalLongName" SG_ 1243 NavRtePrdtdRdLdPwr "Navigation Route Information 1 : Navigation Route Predicted Road Load Power";
BA_ "SignalLongName" SG_ 1243 NavRtePrdtdVehSpd "Navigation Route Information 1 : Navigation Route Predicted Vehicle Speed";
BA_ "SignalType" SG_ 1243 NavRteSts "ENM";
BA_ "SignalLongName" SG_ 1243 NavRteSts "Navigation Route Information 1 : Navigation Route Status";
BA_ "SignalLongName" SG_ 1243 NavRtePrdtdEngyDelt "Navigation Route Information 3 : Navigation Route Predicted Energy Delta";
BA_ "SignalLongName" SG_ 1243 NavRteTmIdx1 "Navigation Route Information 1 : Navigation Route Time Index 1";
BA_ "SignalLongName" SG_ 1243 NavRtePrdtdLat "Navigation Route Information 3 : Navigation Route Predicted Latitude";
BA_ "SignalLongName" SG_ 1243 NavRteTmIdx3 "Navigation Route Information 3 : Navigation Route Time Index 3";
BA_ "SignalLongName" SG_ 1243 NavRtePrdtdElvtn "Navigation Route Information 2 : Navigation Route Predicted Elevation";
BA_ "SignalLongName" SG_ 1243 NavRtePrdtdLng "Navigation Route Information 2 : Navigation Route Predicted Longitude";
BA_ "SignalLongName" SG_ 1243 NavRteTmIdx2 "Navigation Route Information 2 : Navigation Route Time Index 2";
BA_ "SignalLongName" SG_ 1243 NextChrgDestDistToArvl "Next Charging Destination Information 1 : Next Charging Destination Distance To Arrival";
BA_ "SignalLongName" SG_ 1243 NextChrgDestPwrLvl "Next Charging Destination Information 1 : Next Charging Destination Power Level";
BA_ "SignalLongName" SG_ 1243 NextChrgDestTmToArvl "Next Charging Destination Information 1 : Next Charging Destination Time To Arrival";
BA_ "SignalType" SG_ 1243 NextChrgDestSts "ENM";
BA_ "SignalLongName" SG_ 1243 NextChrgDestSts "Next Charging Destination Information 1 : Next Charging Destination Status";
BA_ "SignalType" SG_ 174 RegnOnDmndActv "ENM";
BA_ "SignalLongName" SG_ 174 RegnOnDmndActv "Regen On Demand Active";
BA_ "SignalType" SG_ 965 OnePedDrvMdDrvrSeltnEnbld "ENM";
BA_ "SignalLongName" SG_ 965 OnePedDrvMdDrvrSeltnEnbld "One Pedal Driving Mode Driver Selection Enabled";
BA_ "SignalType" SG_ 1449 SDGE44RS_CntrLtSd "ENM";
BA_ "SignalLongName" SG_ 1449 SDGE44RS_CntrLtSd "Side Distance Guard Park Assist Region Status : Center Left Side Region";
BA_ "SignalType" SG_ 1449 SuprRmtPrkPwrWndsClsReqd "ENM";
BA_ "SignalLongName" SG_ 1449 SuprRmtPrkPwrWndsClsReqd "Supervised Remote Parking Power Windows Close Requested";
BA_ "SignalType" SG_ 1449 SuprRmtPrkKyFbSrchReqd "ENM";
BA_ "SignalLongName" SG_ 1449 SuprRmtPrkKyFbSrchReqd "Supervised Remote Parking Key Fob Search Requested";
BA_ "SignalType" SG_ 1449 SuprRmtPrkStEntExtMemReq "ENM";
BA_ "SignalLongName" SG_ 1449 SuprRmtPrkStEntExtMemReq "Supervised Remote Parking Seat Entry/Exit Memory Request";
BA_ "SignalType" SG_ 1449 SuprRmtPrkSdMirFoldUnfldReq "ENM";
BA_ "SignalLongName" SG_ 1449 SuprRmtPrkSdMirFoldUnfldReq "Supervised Remote Parking Side Mirrors Fold Unfold Request";
BA_ "SignalType" SG_ 1449 SDGE44RS_FrtLtSd "ENM";
BA_ "SignalLongName" SG_ 1449 SDGE44RS_FrtLtSd "Side Distance Guard Park Assist Region Status : Front Left Side Region";
BA_ "SignalType" SG_ 1449 SDGE44RS_CntrRtSd "ENM";
BA_ "SignalLongName" SG_ 1449 SDGE44RS_CntrRtSd "Side Distance Guard Park Assist Region Status : Center Right Side Region";
BA_ "SignalType" SG_ 1449 SDGE44RS_RrLtSd "ENM";
BA_ "SignalLongName" SG_ 1449 SDGE44RS_RrLtSd "Side Distance Guard Park Assist Region Status : Rear Left Side Region";
BA_ "SignalType" SG_ 1449 SDGE44RS_FrtRtSd "ENM";
BA_ "SignalLongName" SG_ 1449 SDGE44RS_FrtRtSd "Side Distance Guard Park Assist Region Status : Front Right Side Region";
BA_ "SignalType" SG_ 1449 PrkAsstTrHtchPsntCstCrStVal "ENM";
BA_ "SignalLongName" SG_ 1449 PrkAsstTrHtchPsntCstCrStVal "Park Assist Trailer Hitch Present Customization Current Setting Value";
BA_ "SignalType" SG_ 1449 SDGE44RS_RrRtSd "ENM";
BA_ "SignalLongName" SG_ 1449 SDGE44RS_RrRtSd "Side Distance Guard Park Assist Region Status : Rear Right Side Region";
BA_ "SignalType" SG_ 1449 PrkAsstTrHtchPsntCstStAvl "ENM";
BA_ "SignalLongName" SG_ 1449 PrkAsstTrHtchPsntCstStAvl "Park Assist Trailer Hitch Present Customization Setting Available";
BA_ "SignalType" SG_ 1449 PrkAsstONOFFCstStAvl "ENM";
BA_ "SignalLongName" SG_ 1449 PrkAsstONOFFCstStAvl "Park Assist On Off Customization Setting Available";
BA_ "SignalLongName" SG_ 1450 CGMERDTC_CdNum "Central Gateway Module Emissions Related DTC : Code Number";
BA_ "SignalType" SG_ 1450 CGMERDTC_SysDes "ENM";
BA_ "SignalLongName" SG_ 1450 CGMERDTC_SysDes "Central Gateway Module Emissions Related DTC : System Designator";
BA_ "SignalType" SG_ 1450 CGMEmsRltMlfAtv "ENM";
BA_ "SignalLongName" SG_ 1450 CGMEmsRltMlfAtv "Central Gateway Module Emissions Related Malfunction Active";
BA_ "SignalLongName" SG_ 1450 PIMRI_CGM_RcntlyProgInd "Programming Inspection and Maintenance Readiness Indication - CGM : Recently Programmed Indicator";
BA_ "SignalType" SG_ 1450 PIMRI_CGM_PrmntDTCInd "ENM";
BA_ "SignalLongName" SG_ 1450 PIMRI_CGM_PrmntDTCInd "Programming Inspection and Maintenance Readiness Indication - CGM : Permanent DTC Indicator";
BA_ "SignalType" SG_ 1450 PIMRI_CGM_FltsPrsntInd "ENM";
BA_ "SignalLongName" SG_ 1450 PIMRI_CGM_FltsPrsntInd "Programming Inspection and Maintenance Readiness Indication - CGM : Faults Present Indicator";
BA_ "SignalType" SG_ 1024 Sig7635 "ENM";
BA_ "SignalLongName" SG_ 1024 Sig7635 "Signal7751";
BA_ "SignalLongName" SG_ 1024 Sig7637 "Signal7753";
BA_ "SignalLongName" SG_ 768 ChsSysTracCtlTgtVel "Chassis System Traction Control Target Velocity";
BA_ "SignalLongName" SG_ 16 PrplSysWhlFlrCtlPriAxlTrqCmd "Propulsion System Wheel Flare Control Primary Axle Torque Command";
BA_ "SignalType" SG_ 16 PrplSysWhlFlrCtlPriAxlActv "ENM";
BA_ "SignalLongName" SG_ 16 PrplSysWhlFlrCtlPriAxlActv "Propulsion System Wheel Flare Control Primary Axle Active";
BA_ "SignalLongName" SG_ 16 PrplSysPriAxlLtTrqActl "Propulsion System Primary Axle Information : Propulsion System Primary Axle Left Torque Actual";
BA_ "SignalType" SG_ 16 PrplSysPriAxlLtTrqActl_Inv "ENM";
BA_ "SignalLongName" SG_ 16 PrplSysPriAxlLtTrqActl_Inv "Propulsion System Primary Axle Information : Propulsion System Primary Axle Left Torque Actual Invalid";
BA_ "SignalLongName" SG_ 16 PrplSysPriAxlRtTrqActl "Propulsion System Primary Axle Information : Propulsion System Primary Axle Right Torque Actual";
BA_ "SignalType" SG_ 16 PrplSysPriAxlRtTrqActl_Inv "ENM";
BA_ "SignalLongName" SG_ 16 PrplSysPriAxlRtTrqActl_Inv "Propulsion System Primary Axle Information : Propulsion System Primary Axle Right Torque Actual Invalid";
BA_ "SignalLongName" SG_ 17 PrplSysWhlFlrCtlSecAxlTrqCmd "Propulsion System Wheel Flare Control Secondary Axle Torque Command";
BA_ "SignalType" SG_ 17 PrplSysWhlFlrCtlSecAxlActv "ENM";
BA_ "SignalLongName" SG_ 17 PrplSysWhlFlrCtlSecAxlActv "Propulsion System Wheel Flare Control Secondary Axle Active";
BA_ "SignalLongName" SG_ 18 PrplSysWhlFlrCtlPriAxlLtTrqCmd "Propulsion System Wheel Flare Control Primary Axle Left Torque Command";
BA_ "SignalType" SG_ 18 PrplSysWhlFlrCtlPriAxlLtActv "ENM";
BA_ "SignalLongName" SG_ 18 PrplSysWhlFlrCtlPriAxlLtActv "Propulsion System Wheel Flare Control Primary Axle Left Active";
VAL_ 1484 LnchCtlWhlSlSts 0 "No Action" 1 "Five Percent" 2 "Five And A Half Percent" 3 "Six Percent" 4 "Six And A Half Percent" 5 "Seven Percent" 6 "Seven And A Half Percent" 7 "Eight Percent" 8 "Eight And A Half Percent" 9 "Nine Percent" 10 "Nine And A Half Percent" 11 "Ten Percent" 12 "Ten And A Half Percent" 13 "Eleven Percent" 14 "Eleven And a Half Percent" 15 "Twelve Percent" 16 "Twelve And A Half Percent" 17 "Thirteen Percent" 18 "Thirteen And A Half Percent" 19 "Fourteen Percent" 20 "Fourteen And A Half Percent" 21 "Fifteen Percent" ;
VAL_ 1484 LnchCtlEngRE46ts 0 "No Action" 1 "800" 2 "900" 3 "1000" 4 "1100" 5 "1200" 6 "1300" 7 "1400" 8 "1500" 9 "1600" 10 "1700" 11 "1800" 12 "1900" 13 "2000" 14 "2100" 15 "2200" 16 "2300" 17 "2400" 18 "2500" 19 "2600" 20 "2700" 21 "2800" 22 "2900" 23 "3000" 24 "3100" 25 "3200" 26 "3300" 27 "3400" 28 "3500" 29 "3600" 30 "3700" 31 "3800" 32 "3900" 33 "4000" 34 "FlexibleRPM 1" 35 "FlexibleRPM 2" 36 "FlexibleRPM 3" 37 "FlexibleRPM 4" 38 "FlexibleRPM 5" ;
VAL_ 1484 DrvModeVisScreenSts 0 "No_Action" 1 "Custom" 2 "Personal" 3 "Sport" 4 "Snow_Ice" 5 "Weather" 6 "Tour" 7 "Track" 8 "Offroad" 9 "TowHaul" 10 "PerformanceSportPlus" 11 "Terrain" 12 "Baja" ;
VAL_ 1484 EngSndPerfModeReq 0 "No Action" 1 "Tour" 2 "Sport_OffRoad" 3 "Track" 4 "Stealth" 5 "Max Power" 6 "Terrain" 7 "Performance Mode 7" ;
VAL_ 1484 PerfTracMgmtMode 0 "Disabled" 1 "Wet" 2 "Dry" 3 "Sport 1" 4 "Sport 2/Race 1" 5 "Race" 6 "Inactive" ;
VAL_ 1484 HillDscntCtlSysSts 0 "Unknown" 1 "Normal" 2 "Enabled" 3 "Active" 4 "Failed" ;
VAL_ 1484 SprtModeDrvlineVisDispVal 0 "Setting_Unknown" 1 "Custom_Mode_1" 2 "Custom_Mode_2" 3 "Custom_Mode_3" 4 "Custom_Mode_4" 5 "Custom_Mode_5" 6 "Custom_Mode_6" 7 "Custom_Mode_7" ;
VAL_ 1484 SprtModeBrkPedVisDispVal 0 "Setting_Unknown" 1 "Custom_Mode_1" 2 "Custom_Mode_2" 3 "Custom_Mode_3" 4 "Custom_Mode_4" 5 "Custom_Mode_5" 6 "Custom_Mode_6" 7 "Custom_Mode_7" ;
VAL_ 1484 SprtModeActvAeroVisDispVal 0 "Setting_Unknown" 1 "Custom_Mode_1" 2 "Custom_Mode_2" 3 "Custom_Mode_3" 4 "Custom_Mode_4" 5 "Custom_Mode_5" 6 "Custom_Mode_6" 7 "Custom_Mode_7" ;
VAL_ 1484 SprtModeRideHghtVisDispVal 0 "Setting_Unknown" 1 "Custom_Mode_1" 2 "Custom_Mode_2" 3 "Custom_Mode_3" 4 "Custom_Mode_4" 5 "Custom_Mode_5" 6 "Custom_Mode_6" 7 "Custom_Mode_7" ;
VAL_ 1484 SprtModePwrtrnVisDispVal 0 "Setting_Unknown" 1 "Custom_Mode_1" 2 "Custom_Mode_2" 3 "Custom_Mode_3" 4 "Custom_Mode_4" 5 "Custom_Mode_5" 6 "Custom_Mode_6" 7 "Custom_Mode_7" ;
VAL_ 1484 SprtModeESCVisDispVal 0 "Setting_Unknown" 1 "Custom_Mode_1" 2 "Custom_Mode_2" 3 "Custom_Mode_3" 4 "Custom_Mode_4" 5 "Custom_Mode_5" 6 "Custom_Mode_6" 7 "Custom_Mode_7" ;
VAL_ 1484 SprtModeSpnsnVisDispVal 0 "Setting_Unknown" 1 "Custom_Mode_1" 2 "Custom_Mode_2" 3 "Custom_Mode_3" 4 "Custom_Mode_4" 5 "Custom_Mode_5" 6 "Custom_Mode_6" 7 "Custom_Mode_7" ;
VAL_ 1484 SprtModeSndVisDispVal 0 "Setting_Unknown" 1 "Custom_Mode_1" 2 "Custom_Mode_2" 3 "Custom_Mode_3" 4 "Custom_Mode_4" 5 "Custom_Mode_5" 6 "Custom_Mode_6" 7 "Custom_Mode_7" ;
VAL_ 1484 ShfToPrkBfrExtIndOn 0 "FALSE" 1 "TRUE" ;
VAL_ 1484 HillDscntCtlVirtSwAvl 0 "Not Available" 1 "Available" ;
VAL_ 1484 WthrSnwModeStrgVisDispVal 0 "Setting_Unknown" 1 "Custom_Mode_1" 2 "Custom_Mode_2" 3 "Custom_Mode_3" 4 "Custom_Mode_4" 5 "Custom_Mode_5" 6 "Custom_Mode_6" 7 "Custom_Mode_7" ;
VAL_ 1484 SprtModeStrgVisDispVal 0 "Setting_Unknown" 1 "Custom_Mode_1" 2 "Custom_Mode_2" 3 "Custom_Mode_3" 4 "Custom_Mode_4" 5 "Custom_Mode_5" 6 "Custom_Mode_6" 7 "Custom_Mode_7" ;
VAL_ 1485 TkModeBrkPedVisDispVal 0 "Setting_Unknown" 1 "Custom_Mode_1" 2 "Custom_Mode_2" 3 "Custom_Mode_3" 4 "Custom_Mode_4" 5 "Custom_Mode_5" 6 "Custom_Mode_6" 7 "Custom_Mode_7" ;
VAL_ 1485 TkModeActvAeroVisDispVal 0 "Setting_Unknown" 1 "Custom_Mode_1" 2 "Custom_Mode_2" 3 "Custom_Mode_3" 4 "Custom_Mode_4" 5 "Custom_Mode_5" 6 "Custom_Mode_6" 7 "Custom_Mode_7" ;
VAL_ 1485 TireTrdTempSts 0 "Unknown" 1 "Cold" 2 "Cool" 3 "Normal" 4 "Warm" 5 "Hot" ;
VAL_ 1485 TkModePwrtrnVisDispVal 0 "Setting_Unknown" 1 "Custom_Mode_1" 2 "Custom_Mode_2" 3 "Custom_Mode_3" 4 "Custom_Mode_4" 5 "Custom_Mode_5" 6 "Custom_Mode_6" 7 "Custom_Mode_7" ;
VAL_ 1485 TkModeESCVisDispVal 0 "Setting_Unknown" 1 "Custom_Mode_1" 2 "Custom_Mode_2" 3 "Custom_Mode_3" 4 "Custom_Mode_4" 5 "Custom_Mode_5" 6 "Custom_Mode_6" 7 "Custom_Mode_7" ;
VAL_ 1485 TkModeDrvlineVisDispVal 0 "Setting_Unknown" 1 "Custom_Mode_1" 2 "Custom_Mode_2" 3 "Custom_Mode_3" 4 "Custom_Mode_4" 5 "Custom_Mode_5" 6 "Custom_Mode_6" 7 "Custom_Mode_7" ;
VAL_ 1485 TkModeSndVisDispVal 0 "Setting_Unknown" 1 "Custom_Mode_1" 2 "Custom_Mode_2" 3 "Custom_Mode_3" 4 "Custom_Mode_4" 5 "Custom_Mode_5" 6 "Custom_Mode_6" 7 "Custom_Mode_7" ;
VAL_ 1485 TkModeRideHghtVisDispVal 0 "Setting_Unknown" 1 "Custom_Mode_1" 2 "Custom_Mode_2" 3 "Custom_Mode_3" 4 "Custom_Mode_4" 5 "Custom_Mode_5" 6 "Custom_Mode_6" 7 "Custom_Mode_7" ;
VAL_ 1485 TourModeActvAeroVisDispVal 0 "Setting_Unknown" 1 "Custom_Mode_1" 2 "Custom_Mode_2" 3 "Custom_Mode_3" 4 "Custom_Mode_4" 5 "Custom_Mode_5" 6 "Custom_Mode_6" 7 "Custom_Mode_7" ;
VAL_ 1485 TkModeStrgVisDispVal 0 "Setting_Unknown" 1 "Custom_Mode_1" 2 "Custom_Mode_2" 3 "Custom_Mode_3" 4 "Custom_Mode_4" 5 "Custom_Mode_5" 6 "Custom_Mode_6" 7 "Custom_Mode_7" ;
VAL_ 1485 TkModeSpnsnVisDispVal 0 "Setting_Unknown" 1 "Custom_Mode_1" 2 "Custom_Mode_2" 3 "Custom_Mode_3" 4 "Custom_Mode_4" 5 "Custom_Mode_5" 6 "Custom_Mode_6" 7 "Custom_Mode_7" ;
VAL_ 1485 TourModeESCVisDispVal 0 "Setting_Unknown" 1 "Custom_Mode_1" 2 "Custom_Mode_2" 3 "Custom_Mode_3" 4 "Custom_Mode_4" 5 "Custom_Mode_5" 6 "Custom_Mode_6" 7 "Custom_Mode_7" ;
VAL_ 1485 TourModeDrvlineVisDispVal 0 "Setting_Unknown" 1 "Custom_Mode_1" 2 "Custom_Mode_2" 3 "Custom_Mode_3" 4 "Custom_Mode_4" 5 "Custom_Mode_5" 6 "Custom_Mode_6" 7 "Custom_Mode_7" ;
VAL_ 1485 TourModeBrkPedVisDispVal 0 "Setting_Unknown" 1 "Custom_Mode_1" 2 "Custom_Mode_2" 3 "Custom_Mode_3" 4 "Custom_Mode_4" 5 "Custom_Mode_5" 6 "Custom_Mode_6" 7 "Custom_Mode_7" ;
VAL_ 1485 TourModeRideHghtVisDispVal 0 "Setting_Unknown" 1 "Custom_Mode_1" 2 "Custom_Mode_2" 3 "Custom_Mode_3" 4 "Custom_Mode_4" 5 "Custom_Mode_5" 6 "Custom_Mode_6" 7 "Custom_Mode_7" ;
VAL_ 1485 TourModePwrtrnVisDispVal 0 "Setting_Unknown" 1 "Custom_Mode_1" 2 "Custom_Mode_2" 3 "Custom_Mode_3" 4 "Custom_Mode_4" 5 "Custom_Mode_5" 6 "Custom_Mode_6" 7 "Custom_Mode_7" ;
VAL_ 1485 TourModeStrgVisDispVal 0 "Setting_Unknown" 1 "Custom_Mode_1" 2 "Custom_Mode_2" 3 "Custom_Mode_3" 4 "Custom_Mode_4" 5 "Custom_Mode_5" 6 "Custom_Mode_6" 7 "Custom_Mode_7" ;
VAL_ 1485 TourModeSpnsnVisDispVal 0 "Setting_Unknown" 1 "Custom_Mode_1" 2 "Custom_Mode_2" 3 "Custom_Mode_3" 4 "Custom_Mode_4" 5 "Custom_Mode_5" 6 "Custom_Mode_6" 7 "Custom_Mode_7" ;
VAL_ 1485 TourModeSndVisDispVal 0 "Setting_Unknown" 1 "Custom_Mode_1" 2 "Custom_Mode_2" 3 "Custom_Mode_3" 4 "Custom_Mode_4" 5 "Custom_Mode_5" 6 "Custom_Mode_6" 7 "Custom_Mode_7" ;
VAL_ 1485 TrlrStbAsstActIO 0 "FALSE" 1 "TRUE" ;
VAL_ 1485 TrcCntrlOnIO 0 "FALSE" 1 "TRUE" ;
VAL_ 1485 TrcCntrlOffIO 0 "FALSE" 1 "TRUE" ;
VAL_ 1485 TnDrvTrCtrlOffUnvIndOn 0 "FALSE" 1 "TRUE" ;
VAL_ 1485 SrBkLwBkFlDrVisMsgRqOn 0 "FALSE" 1 "TRUE" ;
VAL_ 1485 TrcStbScrConfig 0 "None" 1 "TCS Only" 2 "TCS and ESC" 3 "TCS ESC and Comp" ;
VAL_ 712 Sig2631 0 "FALSE" 1 "TRUE" ;
VAL_ 712 Sig3403 0 "FALSE" 1 "TRUE" ;
VAL_ 712 Sig2663 0 "FALSE" 1 "TRUE" ;
VAL_ 712 Sig2619 0 "FALSE" 1 "TRUE" ;
VAL_ 712 Sig3646 0 "FALSE" 1 "TRUE" ;
VAL_ 712 Sig3486 0 "FALSE" 1 "TRUE" ;
VAL_ 712 Sig3483 0 "FALSE" 1 "TRUE" ;
VAL_ 731 ACRfHiSdFldPrs_Inv 0 "FALSE" 1 "TRUE" ;
VAL_ 1503 ChrgCordThftAlrtCstSetAval 0 "FALSE" 1 "TRUE" ;
VAL_ 1503 ChrgCordThftAlrtCstCurrSetVal 0 "No Action" 1 "Off" 2 "On" ;
VAL_ 1509 ChrgPwrLossAlrtCstSetAval 0 "FALSE" 1 "TRUE" ;
VAL_ 1509 ChrgrSysAudblIndCstCurrSetVal 0 "No Action" 1 "Off" 2 "On" ;
VAL_ 1509 ChrgPwrLossAlrtCstCurrSetVal 0 "No Action" 1 "Off" 2 "On" ;
VAL_ 1509 ChrgPortDrIndReq 0 "Inactive" 1 "Open Park" 2 "Open Moving" 3 "Fault" ;
VAL_ 1510 HVWrlsChrgDrvrAlgnCkReqd 0 "FALSE" 1 "TRUE" ;
VAL_ 1510 HVChrgVehSysFltSts 0 "None" 1 "Vehicle Control System Fault" 2 "Vehicle Operating Status Fault" ;
VAL_ 1510 InsfcntTmtoCmpltChrgIndOn 0 "FALSE" 1 "TRUE" ;
VAL_ 1511 CntctrsOpnUndrTempIndOn 0 "FALSE" 1 "TRUE" ;
VAL_ 1511 ChrgrSysAudblIndCstSetAval 0 "FALSE" 1 "TRUE" ;
VAL_ 1511 ChrgStsPeekInScrnActvIndOn 0 "FALSE" 1 "TRUE" ;
VAL_ 1512 PrtblChrgCordLimCstSetAval 0 "FALSE" 1 "TRUE" ;
VAL_ 1512 OffBrdChrgStnFltDtd 0 "FALSE" 1 "TRUE" ;
VAL_ 1512 NeutCstdwnCertModeActvIndOn 0 "FALSE" 1 "TRUE" ;
VAL_ 1512 LocBsdChrgCstSetAval 0 "FALSE" 1 "TRUE" ;
VAL_ 1512 LocBsdChrgCstCurrSetVal 0 "No Action" 1 "Off" 2 "On" ;
VAL_ 1514 LBCPSS_PstnUpdtLoc 0 "No Action" 1 "Update Position 1" 2 "Update Position 2" 3 "Update Position 3" 4 "Update Position 4" ;
VAL_ 1514 LBCCDRR_PstnNumResp 0 "No Action" 1 "Clear Position 1" 2 "Clear Position 2" 3 "Clear Position 3" 4 "Clear Position 4" ;
VAL_ 1514 LBCCDRR_ClrStrdPstnResp 0 "No Action" 1 "Clear Position Request Acknowledged" 2 "Clear Position Request Performed" ;
VAL_ 1514 ServHybChrgSysIndOn 0 "FALSE" 1 "TRUE" ;
VAL_ 1514 LBCCF_Loc4PstnStrdIndOn 0 "FALSE" 1 "TRUE" ;
VAL_ 1514 LBCCF_Loc3PstnStrdIndOn 0 "FALSE" 1 "TRUE" ;
VAL_ 1514 LBCCF_Loc2PstnStrdIndOn 0 "FALSE" 1 "TRUE" ;
VAL_ 1514 LBCCF_Loc1PstnStrdIndOn 0 "FALSE" 1 "TRUE" ;
VAL_ 1514 LBCPSS_PstnUpdtSts 0 "No Action" 1 "Position Updated" 2 "Position Modified" ;
VAL_ 1515 VehLocSts 0 "Not Within Stored Regions" 1 "Within Stored Region 1" 2 "Within Stored Region 2" 3 "Within Stored Region 3" 4 "Within Stored Region 4" ;
VAL_ 1515 VehLocSts_Inv 0 "FALSE" 1 "TRUE" ;
VAL_ 1516 TODCSR_ChrgSchedDyOfWkResp 0 "No Action" 1 "Sunday" 2 "Monday" 3 "Tuesday" 4 "Wednesday" 5 "Thursday" 6 "Friday" 7 "Saturday" 8 "All Days Same" 9 "Monday to Friday Same" 10 "Saturday and Sunday Same" ;
VAL_ 1516 TODCSR_ChrgSchedCstSetVal 0 "No Action" 1 "Off" 2 "On" ;
VAL_ 1516 TODCSR_ERSPrdDyResp 0 "No Action" 1 "Weekday 1" 2 "Weekday 2" 3 "Weekday 3" 4 "Weekday 4" 5 "Weekday 5" 6 "Weekend 1" 7 "Weekend 2" 8 "Weekend 3" 9 "Weekend 4" 10 "Weekend 5" ;
VAL_ 1516 TODCSR_ERSCstSetVal 0 "No Action" 1 "Off" 2 "On" ;
VAL_ 1516 TODCSR_ERSPrdLvlResp 0 "No Action" 1 "Low Rate" 2 "Medium Rate" 3 "High Rate" 4 "Reserved 1" 5 "Invalid Rate" ;
VAL_ 1516 PrtblChrgCordLimCstSetResp 0 "No Action" 1 "Reduced" 2 "Maximum" ;
VAL_ 1516 TODCSR_ERSPrfResp 0 "No Action" 1 "Low Rate" 2 "Medium Rate" 3 "High Rate" ;
VAL_ 1516 TODCCbnPrcndtngSetResp 0 "No Action" 1 "Off" 2 "On" ;
VAL_ 1516 TODCSR_LocNumResp 0 "No Action" 1 "Not in Stored Location" 2 "Stored Location 1" 3 "Stored Location 2" 4 "Stored Location 3" 5 "Stored Location 4" ;
VAL_ 1516 TODCSR_LocChrgPwrLvlResp 0 "Unknown" 1 "Level 1" 2 "Level 2" 3 "DC" 4 "Wireless" ;
VAL_ 1516 UtlChrgIntfrIndOn 0 "FALSE" 1 "TRUE" ;
VAL_ 1517 TODCNP_DprtrDyOfWk 0 "Unknown" 1 "Sunday" 2 "Monday" 3 "Tuesday" 4 "Wednesday" 5 "Thursday" 6 "Friday" 7 "Saturday" ;
VAL_ 1517 TODCNP_Chrg 0 "No Action" 1 "Charge Now" 2 "Charge Later" 3 "Invalid" ;
VAL_ 1517 TODCNP_PCCLCstCurrSetVal 0 "No Action" 1 "Reduced" 2 "Maximum" ;
VAL_ 1517 TmOfDyChrgInvHMIEntIndReqd 0 "FALSE" 1 "TRUE" ;
VAL_ 1517 PrtblChrgCordLimSetExpIndOn 0 "FALSE" 1 "TRUE" ;
VAL_ 1517 RngPerHrGaindThisChrg_DuD 0 "FALSE" 1 "TRUE" ;
VAL_ 1517 RngGaindThisChrg_DuD 0 "FALSE" 1 "TRUE" ;
VAL_ 1517 TODCNextPlndCbnPrcndtngSetResp 0 "No Action" 1 "Off" 2 "On" ;
VAL_ 1519 EngyEconMeasUnt 0 "Distance Per Electrical Energy" 1 "Distance Per Volume Equivalent" 2 "Electrical Energy Per Distance" 3 "Volume Equivalent Per Distance" 4 "Electrical Energy Per Distance x 100" 5 "Volume Equivalent Per Distance x 100" ;
VAL_ 1520 ECHG_CurrEconRdy 0 "FALSE" 1 "TRUE" ;
VAL_ 1520 HiVltgChrgAbrtRsn 0 "No Action" 1 "Loss of AC" 2 "Unplugged Charging" 3 "Unplugged Delayed" 4 "Charge Failure" 5 "Cordset Fault" 6 "Cordset Delay" ;
VAL_ 1520 HiVltgChrgSysSplyFltIndOn 0 "FALSE" 1 "TRUE" ;
VAL_ 1520 HiVltgBatStopChrgBtnVsbl 0 "FALSE" 1 "TRUE" ;
VAL_ 1520 HiVltgBatChrgCordCnctdIndOn 0 "FALSE" 1 "TRUE" ;
VAL_ 1520 HiVltgBatBulkChrgCmplt 0 "FALSE" 1 "TRUE" ;
VAL_ 1520 ElecPrplMtrOvrSpdIndOn 0 "FALSE" 1 "TRUE" ;
VAL_ 1520 HiVltgChrgInhbRsn 0 "No Action" 1 "Cord Not Fully Inserted" 2 "Cord Lock Not Engaged" 3 "See Charging Station" ;
VAL_ 1520 DrvCycEleclEngyUsd_DuD 0 "FALSE" 1 "TRUE" ;
VAL_ 1521 HiVltgBatPrplRng_Inv 0 "FALSE" 1 "TRUE" ;
VAL_ 1521 HiVltgBatPrplRng_DuD 0 "FALSE" 1 "TRUE" ;
VAL_ 1521 HiVltgBatRmnUsblEngy_Inv 0 "FALSE" 1 "TRUE" ;
VAL_ 1521 HiVltgBatRmnUsblEngy_DuD 0 "FALSE" 1 "TRUE" ;
VAL_ 1522 DispHiVltgBatChrgCmpltInfo 0 "FALSE" 1 "TRUE" ;
VAL_ 1524 ElecRateSchedSsnResp 0 "No Action" 1 "Summer" 2 "Winter" 3 "Yearly" ;
VAL_ 1524 HiVltgBatTotUsblEngy_Inv 0 "FALSE" 1 "TRUE" ;
VAL_ 1524 HiVltgBatTotUsblEngy_DuD 0 "FALSE" 1 "TRUE" ;
VAL_ 1524 ElecRateSchedSsnStrtMthResp 0 "No Action" 1 "January" 2 "February" 3 "March" 4 "April" 5 "May" 6 "June" 7 "July" 8 "August" 9 "September" 10 "October" 11 "November" 12 "December" ;
VAL_ 736 LIB1PackExtrnVltg_Inv 0 "FALSE" 1 "TRUE" ;
VAL_ 736 LIB1PackExtrnVltg_DuD 0 "FALSE" 1 "TRUE" ;
VAL_ 736 LIB1AvgTemp_Inv 0 "FALSE" 1 "TRUE" ;
VAL_ 736 LIB1AvgTemp_DuD 0 "FALSE" 1 "TRUE" ;
VAL_ 736 LIB1MaxTemp_DuD 0 "FALSE" 1 "TRUE" ;
VAL_ 736 LIB1MaxTemp_Inv 0 "FALSE" 1 "TRUE" ;
VAL_ 736 LIB1MinTemp_Inv 0 "FALSE" 1 "TRUE" ;
VAL_ 736 LIB1MinTemp_DuD 0 "FALSE" 1 "TRUE" ;
VAL_ 736 LIB1CellBalFlt_DuD 0 "FALSE" 1 "TRUE" ;
VAL_ 736 LIB1CellBalFlt 0 "No Fault" 1 "Low Severity" 2 "Medium Severity" 3 "High Severity" ;
VAL_ 736 LIB1StatOfChrg_Inv 0 "FALSE" 1 "TRUE" ;
VAL_ 736 LIB1StatOfChrg_DuD 0 "FALSE" 1 "TRUE" ;
VAL_ 736 LIB1CellVltgFlt_Inv 0 "FALSE" 1 "TRUE" ;
VAL_ 736 LIB1CellVltgFlt_DuD 0 "FALSE" 1 "TRUE" ;
VAL_ 736 LIB1CellVltgFlt 0 "No Fault" 1 "Low Severity" 2 "Medium Severity" 3 "High Severity" ;
VAL_ 736 LIB1CellBalFlt_Inv 0 "FALSE" 1 "TRUE" ;
VAL_ 952 StrgWhlTchSnsHndsOnStat 0 "Hands Off" 1 "Hands On" ;
VAL_ 1417 ACCAutoStSpStat 0 "No_Set_Speed_Change" 1 "Proposed_Speed_Limit_Change" 2 "Accepted_Speed_Limit_Change" 3 "Declined_Speed_Limit_Change" ;
VAL_ 1417 ACCSpdLimSgnUnt 0 "km/h" 1 "mph" ;
VAL_ 1417 ACCDrSlctdSpdIndOn 0 "FALSE" 1 "TRUE" ;
VAL_ 1417 FrwdImpMtgnOpSlctCstCrStVal 0 "SETTING_UNKNOWN" 1 "OFF" 2 "ALERT" 3 "ALERT_BRAKE" 4 "ALERT_BRAKE_STEER" 5 "RESERVED_5" 6 "RESERVED_6" 7 "RESERVED_7" ;
VAL_ 1417 FrntPCMRspTypCstCrStVal 0 "SETTING_UNKNOWN" 1 "OFF" 2 "ALERT" 3 "ALERT_AND_BRAKE" 4 "ALERT_AND_BRAKE_AND_STEER" 5 "RESERVED_5" 6 "RESERVED_6" 7 "RESERVED_7" ;
VAL_ 1417 ACCSysSlctdMd 0 "Cruise Control Mode Switching Not Supported" 1 "Adaptive Cruise Control" 2 "Enhanced Cruise Control" ;
VAL_ 1417 FrntPCMRspTypCstAvlFlg1 0 "FALSE" 1 "TRUE" ;
VAL_ 1417 AutoEmrgBrkgDsbldIndOn 0 "FALSE" 1 "TRUE" ;
VAL_ 1417 ACCGoNtfrChmEvntSt 0 "NO_ACTION" 1 "ACTIVE" ;
VAL_ 1417 AnmlWrnIndReq 0 "Off" 1 "Animal Advisory" 2 "Animal Alert" ;
VAL_ 1417 FrwdVehAhdIndReq 0 "OFF" 1 "ON" 2 "0.5_Hz" 3 "1_Hz" 4 "2_Hz" 5 "4_Hz" ;
VAL_ 1417 FrtPedtrnClsnMtgnAudAttnReqd 0 "FALSE" 1 "TRUE" ;
VAL_ 1417 FrntPCMRspTypCstStAvl 0 "FALSE" 1 "TRUE" ;
VAL_ 1417 FrntPCMRspTypCstAvlFlg7 0 "FALSE" 1 "TRUE" ;
VAL_ 1417 FrntPCMRspTypCstAvlFlg6 0 "FALSE" 1 "TRUE" ;
VAL_ 1417 FrntPCMRspTypCstAvlFlg5 0 "FALSE" 1 "TRUE" ;
VAL_ 1417 FrntPCMRspTypCstAvlFlg4 0 "FALSE" 1 "TRUE" ;
VAL_ 1417 FrntPCMRspTypCstAvlFlg3 0 "FALSE" 1 "TRUE" ;
VAL_ 1417 FrntPCMRspTypCstAvlFlg2 0 "FALSE" 1 "TRUE" ;
VAL_ 1417 FrwdImpMtgnOpSlctCstAvlFlg7 0 "FALSE" 1 "TRUE" ;
VAL_ 1417 FrwdImpMtgnOpSlctCstAvlFlg6 0 "FALSE" 1 "TRUE" ;
VAL_ 1417 FrwdImpMtgnOpSlctCstAvlFlg5 0 "FALSE" 1 "TRUE" ;
VAL_ 1417 FrwdImpMtgnOpSlctCstAvlFlg4 0 "FALSE" 1 "TRUE" ;
VAL_ 1417 FrwdImpMtgnOpSlctCstAvlFlg3 0 "FALSE" 1 "TRUE" ;
VAL_ 1417 FrwdImpMtgnOpSlctCstAvlFlg2 0 "FALSE" 1 "TRUE" ;
VAL_ 1417 FrwdImpMtgnOpSlctCstAvlFlg1 0 "FALSE" 1 "TRUE" ;
VAL_ 1417 FrwdClsnAlrtImntAlrtAudAttnReqd 0 "FALSE" 1 "TRUE" ;
VAL_ 1417 GoNotfrCstAvlFlg7 0 "FALSE" 1 "TRUE" ;
VAL_ 1417 GoNotfrCstAvlFlg6 0 "FALSE" 1 "TRUE" ;
VAL_ 1417 GoNotfrCstAvlFlg5 0 "FALSE" 1 "TRUE" ;
VAL_ 1417 GoNotfrCstAvlFlg4 0 "FALSE" 1 "TRUE" ;
VAL_ 1417 GoNotfrCstAvlFlg3 0 "FALSE" 1 "TRUE" ;
VAL_ 1417 GoNotfrCstAvlFlg2 0 "FALSE" 1 "TRUE" ;
VAL_ 1417 GoNotfrCstAvlFlg1 0 "FALSE" 1 "TRUE" ;
VAL_ 1417 FrwdImpMtgnOpSlctCstStAvl 0 "FALSE" 1 "TRUE" ;
VAL_ 1259 SprTireSt 0 "Undetermined" 1 "No Spare Detected" 2 "Spare Detected" ;
VAL_ 40 RAI1P_RrAxlStsAuth 0 "Normal" 1 "Temporary Inhibit" 2 "Temporary Limited" 3 "Permanently Failed" ;
VAL_ 40 RAI1P_RrAxlEstdTrqAuth_Inv 0 "FALSE" 1 "TRUE" ;
VAL_ 1465 PIMRI_WE48_PrmntDTCInd 0 "FALSE" 1 "TRUE" ;
VAL_ 1465 PIMRI_WE48_FltsPrsntInd 0 "FALSE" 1 "TRUE" ;
VAL_ 1466 TirePrsStatLRInr 0 "Unknown" 1 "Nominal" 2 "Low - Service Now" 3 "Low" 4 "Low - Extended Mobility" 5 "High" ;
VAL_ 1466 TirePrsLRInr_Inv 0 "FALSE" 1 "TRUE" ;
VAL_ 1466 TirePrsStatRRInr 0 "Unknown" 1 "Nominal" 2 "Low - Service Now" 3 "Low" 4 "Low - Extended Mobility" 5 "High" ;
VAL_ 1466 TirePrsRRInr_Inv 0 "FALSE" 1 "TRUE" ;
VAL_ 1466 ElecRateSchedSsnStrtMthReq 0 "No Action" 1 "January" 2 "February" 3 "March" 4 "April" 5 "May" 6 "June" 7 "July" 8 "August" 9 "September" 10 "October" 11 "November" 12 "December" ;
VAL_ 1466 ElecRateSchedSsnReq 0 "No Action" 1 "Summer" 2 "Winter" 3 "Yearly" ;
VAL_ 1466 VirtOnePedDrvReq 0 "No Action" 1 "On" 2 "Off" ;
VAL_ 1466 TlmHVDCFstChrgSoonReq 0 "No Action" 1 "Off" 2 "On" ;
VAL_ 1466 HVDCFstChrgSoonReq 0 "No Action" 1 "Off" 2 "On" ;
VAL_ 1466 OnePedDrvCstChgSetReq 0 "No Action" 1 "Level 1" 2 "Level 2" 3 "Level 3" 4 "Level 4" ;
VAL_ 1466 Sig2580 0 "Unknown" 1 "Partial Loss" 2 "Full Loss" 3 "No Faults Detected" ;
VAL_ 1466 Sig0613 0 "Unknown" 1 "Partial Loss" 2 "Full Loss" 3 "No Faults Detected" ;
VAL_ 1466 E44MutDrvrReq 0 "No Action" 1 "Mute Requested" 2 "Unmute Requested" ;
VAL_ 1466 CbnPrcndtngSchTempCstSetReqAtv 0 "FALSE" 1 "TRUE" ;
VAL_ 1466 DMSIntnDrvrCstChgSetReq 0 "No Action" 1 "Off" 2 "On" ;
VAL_ 1466 DMSDrwDrvrCstChgSetReq 0 "No Action" 1 "Off" 2 "Normal" 3 "Low Sensitivity" ;
VAL_ 1466 Sig3200 0 "Unknown" 1 "Partial Loss" 2 "Full Loss" 3 "No Faults Detected" ;
VAL_ 929 VehDynsPerfModeReq 0 "No Action" 1 "Tour" 2 "Sport" 3 "Track" 4 "Weather" 5 "Performance Mode 5" 6 "Performance Mode 6" 7 "Performance Mode 7" ;
VAL_ 929 RrDiffPerfModeReq 0 "No Action" 1 "Normal" 2 "ESC & TCS Off" 3 "PTM 2-5" 4 "TCS Off" 5 "Rear eLocker Speed Limited" 6 "4Hi/Terrain" 7 "Rear eLocker No Speed Limit" ;
VAL_ 1467 OnePedDrvCstSetAval 0 "FALSE" 1 "TRUE" ;
VAL_ 1467 OnePedDrvCstSetAllwdFlg7 0 "FALSE" 1 "TRUE" ;
VAL_ 1467 OnePedDrvCstSetAllwdFlg6 0 "FALSE" 1 "TRUE" ;
VAL_ 1467 OnePedDrvCstSetAllwdFlg5 0 "FALSE" 1 "TRUE" ;
VAL_ 1467 OnePedDrvCstSetAllwdFlg4 0 "FALSE" 1 "TRUE" ;
VAL_ 1467 OnePedDrvCstSetAllwdFlg3 0 "FALSE" 1 "TRUE" ;
VAL_ 1467 OnePedDrvCstSetAllwdFlg2 0 "FALSE" 1 "TRUE" ;
VAL_ 1467 OnePedDrvCstSetAllwdFlg1 0 "FALSE" 1 "TRUE" ;
VAL_ 1467 VirtOnePedDrvCtlAval 0 "Not Available" 1 "Available" ;
VAL_ 1467 OnePedDrvCstSetAvlFlg7 0 "FALSE" 1 "TRUE" ;
VAL_ 1467 OnePedDrvCstSetAvlFlg6 0 "FALSE" 1 "TRUE" ;
VAL_ 1467 OnePedDrvCstSetAvlFlg5 0 "FALSE" 1 "TRUE" ;
VAL_ 1467 OnePedDrvCstSetAvlFlg4 0 "FALSE" 1 "TRUE" ;
VAL_ 1467 OnePedDrvCstSetAvlFlg3 0 "FALSE" 1 "TRUE" ;
VAL_ 1467 OnePedDrvCstSetAvlFlg2 0 "FALSE" 1 "TRUE" ;
VAL_ 1467 OnePedDrvCstSetAvlFlg1 0 "FALSE" 1 "TRUE" ;
VAL_ 1467 VirtOnePedDrvUserCtlAllwd 0 "Allowed" 1 "Not Allowed" ;
VAL_ 1468 OnePedDrvIndOn 0 "FALSE" 1 "TRUE" ;
VAL_ 1468 OnePedDrvWrnIndReq 0 "No Action" 1 "Forced Exit" ;
VAL_ 1468 OnePedDrvCurrSeltnVal 0 "Unknown" 1 "On" 2 "Off" ;
VAL_ 1468 OnePedDrvCstCurrSetVal 0 "Setting Unknown" 1 "Level 1" 2 "Level 2" 3 "Level 3" 4 "Level 4" ;
VAL_ 931 ElecMchnAInvrtStat 0 "Power Consumption" 1 "Power Generation" 2 "Deactivated" 3 "Readiness" 4 "Faulted" 5 "Invalid" ;
VAL_ 115 Sig4928 0 "FALSE" 1 "TRUE" ;
VAL_ 194 PrplSysInvrtBDCCurrAuth_Inv 0 "FALSE" 1 "TRUE" ;
VAL_ 953 PrplSysMtrBRotrTemp_Inv 0 "FALSE" 1 "TRUE" ;
VAL_ 953 Sig2567 0 "Power Consumption" 1 "Power Generation" 2 "Deactivated" 3 "Readiness" 4 "Faulted" 5 "Invalid" ;
VAL_ 953 PrplSysMtrBSttrTemp_Inv 0 "FALSE" 1 "TRUE" ;
VAL_ 1471 PIMRI_VECM_PrmntDTCInd 0 "FALSE" 1 "TRUE" ;
VAL_ 1471 PIMRI_VECM_FltsPrsntInd 0 "FALSE" 1 "TRUE" ;
VAL_ 1471 BECM2EmsRltMlfAtv 0 "FALSE" 1 "TRUE" ;
VAL_ 1471 BECM2ERDTC_SysDes 0 "P0-Powertrain Codes SAE Controlled" 1 "P1-Powertrain Codes MFG Controlled" 2 "P2-Powertrain Codes Reserved" 3 "P3-Powertrain Codes Reserved" 4 "C0-Chassis Codes SAE Controlled" 5 "C1-Chassis Codes MFG Controlled" 6 "C2-Chassis Codes Reserved" 7 "C3-Chassis Codes Reserved" 8 "B0-Body Codes SAE Controlled" 9 "B1-Body Codes MFG Controlled" 10 "B2-Body Codes Reserved" 11 "B3-Body Codes Reserved" 12 "U0-Network Codes SAE Controlled" 13 "U1-Network Codes MFG Controlled" 14 "U2- Network Codes Reserved" 15 "U3-Network Codes Reserved" ;
VAL_ 1472 HiVltgBatDispTempLvlPct_DuD 0 "FALSE" 1 "TRUE" ;
VAL_ 1472 HiVltgBatLoSOCIndReq 0 "No Action" 1 "Warning Level 1" 2 "Warning Level 2" 3 "Warning Level 3" ;
VAL_ 1472 HiVltgBatLoSOCIndReq_DuD 0 "FALSE" 1 "TRUE" ;
VAL_ 1472 HiVltgBatPrcndtngSts 0 "No Action" 1 "Inactive" 2 "Active" 3 "Performance Limited" 4 "Battery At Target" 5 "Disabled" ;
VAL_ 1472 HiVltgBatPrcndtngSts_DuD 0 "FALSE" 1 "TRUE" ;
VAL_ 1472 HVDCFstChrgPrepCmpltIndOn 0 "FALSE" 1 "TRUE" ;
VAL_ 1472 HVDCFstChrgPerfLtdIndOn 0 "FALSE" 1 "TRUE" ;
VAL_ 1472 CbnPrcndtngSchTempCstSetAval 0 "FALSE" 1 "TRUE" ;
VAL_ 954 HiVltgBatMaxCellVltg_Inv 0 "FALSE" 1 "TRUE" ;
VAL_ 954 HiVltgBatMinCellVltg_Inv 0 "FALSE" 1 "TRUE" ;
VAL_ 954 AuxPwrModDCDCStat 0 "In Operation" 1 "Cut-off" ;
VAL_ 178 PrplSysInvrtADCCurrAuth_Inv 0 "FALSE" 1 "TRUE" ;
VAL_ 955 HVWrlsChrgFncActvtd 0 "FALSE" 1 "TRUE" ;
VAL_ 955 HVBatWrlsCntctrSts 0 "Open" 1 "Precharge" 2 "Close" ;
VAL_ 955 HVWrlsChrgFncActvtdTyp 0 "None" 1 "Local Enable" 2 "Remote Enable" 3 "Reserved" 4 "User Disable" 5 "Vehicle Operating Mode Disable" 6 "PPC Fault Disable" 7 "PTC Fault Disable" 8 "CSU Fault Disable" 9 "WCCMS Disable" 10 "PFC Fault Disable" 11 "Vehicle Actively Disable" ;
VAL_ 534 HVWrlsChrgModeCmd 0 "None" 1 "Voltage Control Mode" 2 "Current Control Mode" ;
VAL_ 1475 SecAxlDrvUntOilTemp_Inv 0 "FALSE" 1 "TRUE" ;
VAL_ 1435 RrStrgModeSeltnIndOn 0 "FALSE" 1 "TRUE" ;
VAL_ 1435 RrStrgModeUnvIndReq 0 "No Indication" 1 "Speed Too High" 2 "Incorrect Gear" 3 "Mode Unavailable" 4 "Steering Too Fast" 5 "Automated Driving 1" 6 "Automated Driving 2" ;
VAL_ 1470 Sig4476 0 "FALSE" 1 "TRUE" ;
VAL_ 1476 Sig5020 0 "FALSE" 1 "TRUE" ;
VAL_ 1477 PnCActnReqCertfctTyp 0 "None" 1 "GM Provisioning Certificate" 2 "Contract Certificate" 3 "V2G Root Certificate" 4 "OCSP Certificate" 5 "Private Operator Root Certificate" 6 "Reserved1" 7 "Reserved2" 8 "Reserved3" 9 "Reserved4" 10 "Reserved5" 11 "Reserved6" 12 "Reserved7" 13 "Reserved8" 14 "All Contract And Private Operator Root Certificates" ;
VAL_ 1477 PnCActnReqCertfctOp 0 "No Action" 1 "Disable Certificate" 2 "Enable Certificate" 3 "Erase Certificate" 4 "Install Certificate" ;
VAL_ 1477 PnCEnblReq 0 "Unknown" 1 "No Action" 2 "Enable" 3 "Disable" ;
VAL_ 1496 AutoCoolServFllIndReq 0 "No Indication" 1 "ACSF Enabled" 2 "ACSF Completed Successfully" 3 "ACSF Canceled" ;
VAL_ 1496 Sig4478 0 "Cleaning Not Required" 1 "Allowed" 2 "Not Allowed" 3 "In Progress" 4 "Complete" 5 "Pending Driver Input" 6 "Not Available" 7 "Do Not Press Pedals" ;
VAL_ 1496 Sig2583 0 "No Action" 1 "No Indication" 2 "Idle Needed" 3 "Overheated" 4 "Interrupted" ;
VAL_ 1496 Sig4480 0 "FALSE" 1 "TRUE" ;
VAL_ 1504 PrplSysChsSysPriAxlRtTrqReqSts 0 "No Request" 1 "Request Honored" 2 "Lost Arbitration" 3 "Serial Data Failure Temporary" 4 "Serial Data Failure Permanent" 5 "Control System Failure Temporary" 6 "Control System Failure Permanent" ;
VAL_ 1504 PrplSysChsSysPriAxlLtTrqReqSts 0 "No Request" 1 "Request Honored" 2 "Lost Arbitration" 3 "Serial Data Failure Temporary" 4 "Serial Data Failure Permanent" 5 "Control System Failure Temporary" 6 "Control System Failure Permanent" ;
VAL_ 1505 PrplSysElecPrkBrkApplReqd 0 "FALSE" 1 "TRUE" ;
VAL_ 74 DrvMtrSysFltd 0 "FALSE" 1 "TRUE" ;
VAL_ 1535 ICMTrngOncmgTrfcChmEvntStat 0 "No Action" 1 "Active" 2 "Cancel Chime" ;
VAL_ 1535 ICMRtChmEvntStat 0 "No Action" 1 "Active" 2 "Cancel Chime" ;
VAL_ 1535 ICMLtChmEvntStat 0 "No Action" 1 "Active" 2 "Cancel Chime" ;
VAL_ 1811 RIMUnvTlgtIndOn 0 "FALSE" 1 "TRUE" ;
VAL_ 1811 ICMWrnIndReq 0 "Off" 1 "Left" 2 "Right" 3 "Oncoming" ;
VAL_ 1812 PnCCertStsDispCertTyp2 0 "None" 1 "GM Provisioning Certificate" 2 "Contract Certificate" 3 "V2G Root Certificate" 4 "OCSP Certificate" 5 "Private Operator Root Certificate" ;
VAL_ 1253 PnCCertStsDispCertTyp3 0 "None" 1 "GM Provisioning Certificate" 2 "Contract Certificate" 3 "V2G Root Certificate" 4 "OCSP Certificate" 5 "Private Operator Root Certificate" ;
VAL_ 1813 PnCCertStsDispCertTyp4 0 "None" 1 "GM Provisioning Certificate" 2 "Contract Certificate" 3 "V2G Root Certificate" 4 "OCSP Certificate" 5 "Private Operator Root Certificate" ;
VAL_ 1813 PnCCertStsDispCertTyp1 0 "None" 1 "GM Provisioning Certificate" 2 "Contract Certificate" 3 "V2G Root Certificate" 4 "OCSP Certificate" 5 "Private Operator Root Certificate" ;
VAL_ 1813 PnCCertStsDispCertSts 0 "No Action" 1 "Certificate Not Installed" 2 "Certificate Disabled" 3 "Certificate Enabled" ;
VAL_ 1252 PnCCertStsDispCertTyp5 0 "None" 1 "GM Provisioning Certificate" 2 "Contract Certificate" 3 "V2G Root Certificate" 4 "OCSP Certificate" 5 "Private Operator Root Certificate" ;
VAL_ 957 Sig0071 0 "FALSE" 1 "TRUE" ;
VAL_ 116 HVBatOutOfEngyRdcdPrplReq 0 "FALSE" 1 "TRUE" ;
VAL_ 958 Sig0070 0 "FALSE" 1 "TRUE" ;
VAL_ 1814 DrvMtrInvrt3MaxTemp_Inv 0 "FALSE" 1 "TRUE" ;
VAL_ 1815 ManRgnModeOvrrdn 0 "FALSE" 1 "TRUE" ;
VAL_ 1250 PnCActnStsCertfctTyp 0 "None" 1 "GM Provisioning Certificate" 2 "Contract Certificate" 3 "V2G Root Certificate" 4 "OCSP Certificate" 5 "Private Operator Root Certificate" 6 "Reserved1" 7 "Reserved2" 8 "Reserved3" 9 "Reserved4" 10 "Reserved5" 11 "Reserved6" 12 "Reserved7" 13 "Reserved8" 14 "All Contract And Private Operator Root Certificates" ;
VAL_ 1250 PnCActnStsCertfctOpSts 0 "NoAction" 1 "CertificateDisabledSuccessfully" 2 "CertificateDisableFailed" 3 "CertificateEnabledSuccessfully" 4 "CertificateEnableFailed" 5 "CertificateErasedSuccessfully" 6 "CertificateErasureFailed" 7 "CertificateDisableOperationInProgress" 8 "CertificateEnableOperationInProgress" 9 "CertificateEraseOperationInProgress" 10 "SelectedCertificateOperationLocationisOutofBounds" 11 "NoCertificateisInstalledintheRequestedCertificateLocation" 12 "NoCertificateofThisCertificateTypeisInstalledintheEVCC" 13 "CertificateOperationNotSupportedonThisCertificateType" 14 "CertificateOperationCannotbePerformedatThisTime" 15 "CertificateInstallOperationInProgress" 16 "CertificateInstalledSuccessfully" 17 "CertificateInstallFailed" ;
VAL_ 1250 PnCStsDisp 0 "No Action" 1 "No Errors" 2 "Unplug And Replug" 3 "Two Factor Authentication Failure" 4 "Try Different Charging Station" 5 "Install Contract or Private Operator Certificate" 6 "Contract Certificate Invalid" 7 "Service Vehicle" 8 "Certificate Revoked" ;
VAL_ 1250 PnCEnbldSts 0 "Unknown" 1 "Enabled" 2 "Disabled" ;
VAL_ 659 GNSSVel01EstVelUncrtnty_DuD 0 "FALSE" 1 "TRUE" ;
VAL_ 659 GNSSVel01EstVel_Inv 0 "FALSE" 1 "TRUE" ;
VAL_ 659 GNSSVel01EstVel_DuD 0 "FALSE" 1 "TRUE" ;
VAL_ 659 GNSSVel01EstVelUncrtnty_Inv 0 "FALSE" 1 "TRUE" ;
VAL_ 659 GNSSVel01NrthVel_Inv 0 "FALSE" 1 "TRUE" ;
VAL_ 659 GNSSVel01NrthVel_DuD 0 "FALSE" 1 "TRUE" ;
VAL_ 659 GNSSVel01NrthVelUncrtnty_Inv 0 "FALSE" 1 "TRUE" ;
VAL_ 659 GNSSVel01NrthVelUncrtnty_DuD 0 "FALSE" 1 "TRUE" ;
VAL_ 659 GNSSVel02UpVel_Inv 0 "FALSE" 1 "TRUE" ;
VAL_ 659 GNSSVel02UpVel_DuD 0 "FALSE" 1 "TRUE" ;
VAL_ 659 GNSSVel02UpVelUncrtnty_Inv 0 "FALSE" 1 "TRUE" ;
VAL_ 659 GNSSVel02UpVelUncrtnty_DuD 0 "FALSE" 1 "TRUE" ;
VAL_ 659 GPSQM_PPSMode 0 "GNSS Standalone" 1 "GNSS and SBAS" 2 "GNSS and RTX" 3 "GNSS and DR" 4 "GNSS and SBAS and DR" 5 "GNSS and RTX and DR" 6 "DR ONLY" 7 "GNSS and RTX and DR and MM" ;
VAL_ 659 GPSQM_PPSMode_Inv 0 "FALSE" 1 "TRUE" ;
VAL_ 659 WndPstnStsRR 0 "Denormalized" 1 "Fully Closed" 2 "Less Than Position A" 3 "Position A" 4 "Greater Than A but less than Position C" 5 "Position C" 6 "Greater than Position C but less than Fully open" 7 "Fully Open" ;
VAL_ 659 WndPstnStsLR 0 "Denormalized" 1 "Fully Closed" 2 "Less Than Position A" 3 "Position A" 4 "Greater Than A but less than Position C" 5 "Position C" 6 "Greater than Position C but less than Fully open" 7 "Fully Open" ;
VAL_ 1249 HiBmSelSwActv 0 "FALSE" 1 "TRUE" ;
VAL_ 1249 AE44BkBtnSts 0 "No Request" 1 "Back Request" ;
VAL_ 1249 AE44SuprPrkSts 0 "No Request" 1 "In Vehicle Request" 2 "Supervised Request" ;
VAL_ 1817 LnchCtlUnvRsn 0 "No Indication" 1 "Steering Turned" 2 "Generic Unused 2" 3 "Generic Unused 3" 4 "Generic Unused 4" 5 "Generic Unused 5" 6 "Generic Unused 6" 7 "Generic Unused 7" ;
VAL_ 1817 LnchCtlSts 0 "No Action" 1 "Unavailable" 2 "Available" 3 "Armed" 4 "Active" 5 "Generic Unused 5" 6 "Generic Unused 6" 7 "Generic Unused 7" ;
VAL_ 1817 LnchCtlCchTrgrd 0 "FALSE" 1 "TRUE" ;
VAL_ 1817 EVPedMpPerfModeReq 0 "No Action" 1 "Normal" 2 "Sport" 3 "Snow" 4 "Track_Baja_Offroad" 5 "Crawl" 6 "Max Power" 7 "Tow_Haul" ;
VAL_ 31 Sig2415 0 "FALSE" 1 "TRUE" ;
VAL_ 1248 VirtRrAxlLckSts 0 "Off" 1 "On" 2 "Unavailable" 3 "Faulted" ;
VAL_ 960 PrplSysMtrCRotrTemp_Inv 0 "FALSE" 1 "TRUE" ;
VAL_ 960 PrplSysMtrCSttrTemp_Inv 0 "FALSE" 1 "TRUE" ;
VAL_ 117 Sig2414 0 "No Fault" 1 "Propulsion Fault" 2 "HV Fault" 3 "Controller Fault" 4 "Latent Fault" 5 "Full Propulsion System Fault" ;
VAL_ 1818 SuprRmtPrkAval 0 "Not Available" 1 "Available" ;
VAL_ 1247 Sig4600 0 "FALSE" 1 "TRUE" ;
VAL_ 1247 Sig4599 0 "FALSE" 1 "TRUE" ;
VAL_ 1247 Sig4598 0 "FALSE" 1 "TRUE" ;
VAL_ 1247 Sig4597 0 "FALSE" 1 "TRUE" ;
VAL_ 1247 Sig4596 0 "FALSE" 1 "TRUE" ;
VAL_ 1247 Sig4595 0 "FALSE" 1 "TRUE" ;
VAL_ 1247 E49HrnChrpReq 0 "No Action" 1 "Active" 2 "Cancel Horn" ;
VAL_ 1247 Sig4608 0 "FALSE" 1 "TRUE" ;
VAL_ 1247 Sig4607 0 "FALSE" 1 "TRUE" ;
VAL_ 1247 Sig4606 0 "FALSE" 1 "TRUE" ;
VAL_ 1247 Sig4605 0 "FALSE" 1 "TRUE" ;
VAL_ 1247 Sig4604 0 "FALSE" 1 "TRUE" ;
VAL_ 1247 Sig4603 0 "FALSE" 1 "TRUE" ;
VAL_ 1247 Sig4602 0 "FALSE" 1 "TRUE" ;
VAL_ 1247 Sig4601 0 "FALSE" 1 "TRUE" ;
VAL_ 1247 Sig4802 0 "FALSE" 1 "TRUE" ;
VAL_ 1247 Sig4801 0 "FALSE" 1 "TRUE" ;
VAL_ 1247 Sig4800 0 "FALSE" 1 "TRUE" ;
VAL_ 1247 Sig4688 0 "FALSE" 1 "TRUE" ;
VAL_ 1247 Sig4687 0 "FALSE" 1 "TRUE" ;
VAL_ 1247 Sig4626 0 "FALSE" 1 "TRUE" ;
VAL_ 1247 Sig4625 0 "FALSE" 1 "TRUE" ;
VAL_ 1247 Sig4609 0 "FALSE" 1 "TRUE" ;
VAL_ 1247 Sig4810 0 "FALSE" 1 "TRUE" ;
VAL_ 1247 Sig4809 0 "FALSE" 1 "TRUE" ;
VAL_ 1247 Sig4808 0 "FALSE" 1 "TRUE" ;
VAL_ 1247 Sig4807 0 "FALSE" 1 "TRUE" ;
VAL_ 1247 Sig4806 0 "FALSE" 1 "TRUE" ;
VAL_ 1247 Sig4805 0 "FALSE" 1 "TRUE" ;
VAL_ 1247 Sig4804 0 "FALSE" 1 "TRUE" ;
VAL_ 1247 Sig4803 0 "FALSE" 1 "TRUE" ;
VAL_ 1247 Sig4826 0 "FALSE" 1 "TRUE" ;
VAL_ 1247 Sig4825 0 "FALSE" 1 "TRUE" ;
VAL_ 1247 Sig4824 0 "FALSE" 1 "TRUE" ;
VAL_ 1247 Sig4823 0 "FALSE" 1 "TRUE" ;
VAL_ 1247 Sig4814 0 "FALSE" 1 "TRUE" ;
VAL_ 1247 Sig4813 0 "FALSE" 1 "TRUE" ;
VAL_ 1247 Sig4812 0 "FALSE" 1 "TRUE" ;
VAL_ 1247 Sig4811 0 "FALSE" 1 "TRUE" ;
VAL_ 1247 Sig4834 0 "FALSE" 1 "TRUE" ;
VAL_ 1247 Sig4833 0 "FALSE" 1 "TRUE" ;
VAL_ 1247 Sig4832 0 "FALSE" 1 "TRUE" ;
VAL_ 1247 Sig4831 0 "FALSE" 1 "TRUE" ;
VAL_ 1247 Sig4830 0 "FALSE" 1 "TRUE" ;
VAL_ 1247 Sig4829 0 "FALSE" 1 "TRUE" ;
VAL_ 1247 Sig4828 0 "FALSE" 1 "TRUE" ;
VAL_ 1247 Sig4827 0 "FALSE" 1 "TRUE" ;
VAL_ 1247 Sig4860 0 "FALSE" 1 "TRUE" ;
VAL_ 1247 Sig4859 0 "FALSE" 1 "TRUE" ;
VAL_ 1247 Sig4858 0 "FALSE" 1 "TRUE" ;
VAL_ 1247 Sig4857 0 "FALSE" 1 "TRUE" ;
VAL_ 1247 Sig4856 0 "FALSE" 1 "TRUE" ;
VAL_ 1247 Sig4837 0 "FALSE" 1 "TRUE" ;
VAL_ 1247 Sig4836 0 "FALSE" 1 "TRUE" ;
VAL_ 1247 Sig4835 0 "FALSE" 1 "TRUE" ;
VAL_ 1247 Sig4883 0 "FALSE" 1 "TRUE" ;
VAL_ 1247 Sig4882 0 "FALSE" 1 "TRUE" ;
VAL_ 1247 Sig4881 0 "FALSE" 1 "TRUE" ;
VAL_ 1247 Sig4880 0 "FALSE" 1 "TRUE" ;
VAL_ 1247 Sig4879 0 "FALSE" 1 "TRUE" ;
VAL_ 1247 Sig4878 0 "FALSE" 1 "TRUE" ;
VAL_ 1247 Sig4862 0 "FALSE" 1 "TRUE" ;
VAL_ 1247 Sig4861 0 "FALSE" 1 "TRUE" ;
VAL_ 1247 Sig4884 0 "FALSE" 1 "TRUE" ;
VAL_ 661 LIBSOCCalReqd 0 "FALSE" 1 "TRUE" ;
VAL_ 1819 ChrgCycEleclEngyUsd_DuD 0 "FALSE" 1 "TRUE" ;
VAL_ 1819 OffBrdVehImbNtfn 0 "No action" 1 "Warning Level 1" 2 "Warning Level 2" 3 "Warning Level 3" ;
VAL_ 1819 LifetmEleclEngyEcon_DuD 0 "FALSE" 1 "TRUE" ;
VAL_ 1246 HVThrmlPwrCnsmd_Inv 0 "FALSE" 1 "TRUE" ;
VAL_ 1246 HVThrmlPwrCnsmd_DuD 0 "FALSE" 1 "TRUE" ;
VAL_ 73 Sig4940 0 "FALSE" 1 "TRUE" ;
VAL_ 1821 EngCmptAjr 0 "FALSE" 1 "TRUE" ;
VAL_ 1821 EngCmptAjr_Inv 0 "FALSE" 1 "TRUE" ;
VAL_ 738 Sig7819 0 "RVC Active" 1 "Loss of Arbitration" 2 "Unknown" ;
VAL_ 1245 ElecShfPriLoManSeltnIndReq 0 "No Indication" 1 "Low" 2 "Manual" ;
VAL_ 1244 DrLckLRStsAuth 0 "Unknown" 1 "Locked" 2 "Unlocked" ;
VAL_ 1244 DrLckLFStsAuth 0 "Unknown" 1 "Locked" 2 "Unlocked" ;
VAL_ 1244 CntrStckDispFlrIndOn 0 "FALSE" 1 "TRUE" ;
VAL_ 1244 ICMCstChgSetReq 0 "No Action" 1 "Off" 2 "Alert" 3 "Alert Brake" 4 "Alert Brake Steer" ;
VAL_ 1244 PrplDispExtndCpbltyLvlPct_DuD 0 "FALSE" 1 "TRUE" ;
VAL_ 1244 Sig7636 0 "No Request" 1 "Reset Request Active" ;
VAL_ 1244 CrnrLmpRtCmndOn 0 "FALSE" 1 "TRUE" ;
VAL_ 1244 CrnrLmpLtCmndOn 0 "FALSE" 1 "TRUE" ;
VAL_ 1244 DrLckRRStsAuth 0 "Unknown" 1 "Locked" 2 "Unlocked" ;
VAL_ 1244 DrLckRFStsAuth 0 "Unknown" 1 "Locked" 2 "Unlocked" ;
VAL_ 1244 DMSDrwIntnWrnDrvrResp 0 "No Action" 1 "Dismiss" ;
VAL_ 1244 E44SftBtnSeltdStatRw 0 "Not_Pressed" 1 "Pressed" 2 "Unknown" 3 "Failed" ;
VAL_ 1244 FrtCmptShftrLckReqd 0 "FALSE" 1 "TRUE" ;
VAL_ 1244 VirtCtlVehEmrgOffSwReqd 0 "FALSE" 1 "TRUE" ;
VAL_ 1244 VirtCtlVehOffSwReq 0 "Not Pressed" 1 "Pressed" 2 "Press and Hold" ;
VAL_ 1244 DrMtzdStBltUnIndOn 0 "FALSE" 1 "TRUE" ;
VAL_ 1822 ICMCstAvlFlg5 0 "FALSE" 1 "TRUE" ;
VAL_ 1822 ICMCstAvlFlg4 0 "FALSE" 1 "TRUE" ;
VAL_ 1822 ICMCstAvlFlg3 0 "FALSE" 1 "TRUE" ;
VAL_ 1822 ICMCstAvlFlg2 0 "FALSE" 1 "TRUE" ;
VAL_ 1822 ICMCstAvlFlg1 0 "FALSE" 1 "TRUE" ;
VAL_ 1822 ICMCstSelCstCurSetVal 0 "Setting Unknown" 1 "Off" 2 "Alert" 3 "Alert Brake" 4 "Alert Brake Steer" ;
VAL_ 1822 ICMCstSelCstSetAval 0 "FALSE" 1 "TRUE" ;
VAL_ 1822 ICMCstAvlFlg7 0 "FALSE" 1 "TRUE" ;
VAL_ 1822 ICMCstAvlFlg6 0 "FALSE" 1 "TRUE" ;
VAL_ 30 Sig2582 0 "FALSE" 1 "TRUE" ;
VAL_ 30 PrplSysSecAxlTrqReqStsChsSys 0 "No Request" 1 "Request Honored" 2 "Lost Arbitration" 3 "Serial Data Failure Temporary" 4 "Serial Data Failure Permanent" 5 "Control System Failure Temporary" 6 "Control System Failure Permanent" ;
VAL_ 30 Sig2659 0 "FALSE" 1 "TRUE" ;
VAL_ 1243 NavRteChgOcc 0 "FALSE" 1 "TRUE" ;
VAL_ 1243 NavRteSts 0 "No Action" 1 "Inactive" 2 "Active" 3 "Predicted" 4 "Learned" ;
VAL_ 1243 NextChrgDestSts 0 "No Action" 1 "Charge Not Planned" 2 "Charge Planned" 3 "Charge Location Reached" ;
VAL_ 174 RegnOnDmndActv 0 "FALSE" 1 "TRUE" ;
VAL_ 965 OnePedDrvMdDrvrSeltnEnbld 0 "FALSE" 1 "TRUE" ;
VAL_ 1449 SDGE44RS_CntrLtSd 0 "OFF" 1 "FAILED" 2 "BLOCKED" 3 "ATTACHED_OBJECT" 4 "NO_OBJECT" 5 "ZONE_1" 6 "ZONE_2" 7 "ZONE_3" 8 "ZONE_4" 9 "ZONE_5" 10 "ZONE_6" 11 "OFF_NO_FAULT" 12 "RESERVED_1" 13 "RESERVED_2" 14 "RESERVED_3" ;
VAL_ 1449 SuprRmtPrkPwrWndsClsReqd 0 "FALSE" 1 "TRUE" ;
VAL_ 1449 SuprRmtPrkKyFbSrchReqd 0 "FALSE" 1 "TRUE" ;
VAL_ 1449 SuprRmtPrkStEntExtMemReq 0 "No Request" 1 "Seat Entry" 2 "Seat Exit" 3 "Stop Movement" ;
VAL_ 1449 SuprRmtPrkSdMirFoldUnfldReq 0 "No Request" 1 "Fold" 2 "Unfold" ;
VAL_ 1449 SDGE44RS_FrtLtSd 0 "OFF" 1 "FAILED" 2 "BLOCKED" 3 "ATTACHED_OBJECT" 4 "NO_OBJECT" 5 "ZONE_1" 6 "ZONE_2" 7 "ZONE_3" 8 "ZONE_4" 9 "ZONE_5" 10 "ZONE_6" 11 "OFF_NO_FAULT" 12 "RESERVED_1" 13 "RESERVED_2" 14 "RESERVED_3" ;
VAL_ 1449 SDGE44RS_CntrRtSd 0 "OFF" 1 "FAILED" 2 "BLOCKED" 3 "ATTACHED_OBJECT" 4 "NO_OBJECT" 5 "ZONE_1" 6 "ZONE_2" 7 "ZONE_3" 8 "ZONE_4" 9 "ZONE_5" 10 "ZONE_6" 11 "OFF_NO_FAULT" 12 "RESERVED_1" 13 "RESERVED_2" 14 "RESERVED_3" ;
VAL_ 1449 SDGE44RS_RrLtSd 0 "OFF" 1 "FAILED" 2 "BLOCKED" 3 "ATTACHED_OBJECT" 4 "NO_OBJECT" 5 "ZONE_1" 6 "ZONE_2" 7 "ZONE_3" 8 "ZONE_4" 9 "ZONE_5" 10 "ZONE_6" 11 "OFF_NO_FAULT" 12 "RESERVED_1" 13 "RESERVED_2" 14 "RESERVED_3" ;
VAL_ 1449 SDGE44RS_FrtRtSd 0 "OFF" 1 "FAILED" 2 "BLOCKED" 3 "ATTACHED_OBJECT" 4 "NO_OBJECT" 5 "ZONE_1" 6 "ZONE_2" 7 "ZONE_3" 8 "ZONE_4" 9 "ZONE_5" 10 "ZONE_6" 11 "OFF_NO_FAULT" 12 "RESERVED_1" 13 "RESERVED_2" 14 "RESERVED_3" ;
VAL_ 1449 PrkAsstTrHtchPsntCstCrStVal 0 "SETTING_UNKNOWN" 1 "OFF_NOT_ATTACHED" 2 "ON_ATTACHED" 3 "RESERVED_3" 4 "RESERVED_4" 5 "RESERVED_5" 6 "RESERVED_6" 7 "RESERVED_7" ;
VAL_ 1449 SDGE44RS_RrRtSd 0 "OFF" 1 "FAILED" 2 "BLOCKED" 3 "ATTACHED_OBJECT" 4 "NO_OBJECT" 5 "ZONE_1" 6 "ZONE_2" 7 "ZONE_3" 8 "ZONE_4" 9 "ZONE_5" 10 "ZONE_6" 11 "OFF_NO_FAULT" 12 "RESERVED_1" 13 "RESERVED_2" 14 "RESERVED_3" ;
VAL_ 1449 PrkAsstTrHtchPsntCstStAvl 0 "FALSE" 1 "TRUE" ;
VAL_ 1449 PrkAsstONOFFCstStAvl 0 "FALSE" 1 "TRUE" ;
VAL_ 1450 CGMERDTC_SysDes 0 "P0-Powertrain Codes SAE Controlled" 1 "P1-Powertrain Codes MFG Controlled" 2 "P2-Powertrain Codes Reserved" 3 "P3-Powertrain Codes Reserved" 4 "C0-Chassis Codes SAE Controlled" 5 "C1-Chassis Codes MFG Controlled" 6 "C2-Chassis Codes Reserved" 7 "C3-Chassis Codes Reserved" 8 "B0-Body Codes SAE Controlled" 9 "B1-Body Codes MFG Controlled" 10 "B2-Body Codes Reserved" 11 "B3-Body Codes Reserved" 12 "U0-Network Codes SAE Controlled" 13 "U1-Network Codes MFG Controlled" 14 "U2- Network Codes Reserved" 15 "U3-Network Codes Reserved" ;
VAL_ 1450 CGMEmsRltMlfAtv 0 "FALSE" 1 "TRUE" ;
VAL_ 1450 PIMRI_CGM_PrmntDTCInd 0 "FALSE" 1 "TRUE" ;
VAL_ 1450 PIMRI_CGM_FltsPrsntInd 0 "FALSE" 1 "TRUE" ;
VAL_ 1024 Sig7635 0 "FALSE" 1 "TRUE" ;
VAL_ 16 PrplSysWhlFlrCtlPriAxlActv 0 "FALSE" 1 "TRUE" ;
VAL_ 16 PrplSysPriAxlLtTrqActl_Inv 0 "FALSE" 1 "TRUE" ;
VAL_ 16 PrplSysPriAxlRtTrqActl_Inv 0 "FALSE" 1 "TRUE" ;
VAL_ 17 PrplSysWhlFlrCtlSecAxlActv 0 "FALSE" 1 "TRUE" ;
VAL_ 18 PrplSysWhlFlrCtlPriAxlLtActv 0 "FALSE" 1 "TRUE" ;
